VERSION "HNPBNNNYNNNNNNNNNNNNNNNNNNNNNNNNYNYYYYYYYY>4>%%%/4>'%**4YYY///"

NS_ :

BS_:

BU_: RDF2 Air Vehicle_CAN MPC2

BO_ 3221225472 VECTOR__INDEPENDENT_SIG_MSG: 0 Vector__XXX
 SG_ IHC_StaticLightDist : 0|16@1+ (1,0) [0|65535] "" Vector__XXX
 SG_ IHC_State : 0|8@1+ (1,0) [0|255] "" Vector__XXX
 SG_ RSF_SpeedLimit2FusionStrategy : 0|3@1+ (1,0) [0|7] "" Vector__XXX

BO_ 2566881322 NM_MPC_RDF2: 8 RDF2
 SG_ NM_Mode : 0|8@1+ (1,0) [0|255] "" Vector__XXX
 SG_ NM_Successor : 8|8@1+ (1,0) [0|255] "NoUnit" Vector__XXX
 SG_ NM_Ud_Launch : 16|6@1+ (1,0) [0|63] "" Vector__XXX
 SG_ NM_Sleep_Ack : 22|1@1+ (1,0) [0|1] "" Vector__XXX
 SG_ NM_Sleep_Ind : 23|1@1+ (1,0) [0|1] "" Vector__XXX
 SG_ NM_Ud_Srv M : 24|8@1+ (1,0) [0|255] "" Vector__XXX
 SG_ WakeupRsn_MPC m2 : 32|8@1+ (1,0) [0|255] "" Vector__XXX
 SG_ Awake_NwSt m15 : 32|1@1+ (1,0) [0|1] "" Vector__XXX
 SG_ Awake_Diag_Actv m15 : 33|1@1+ (1,0) [0|1] "" Vector__XXX
 SG_ Awake_IgnOn m15 : 34|1@1+ (1,0) [0|1] "" Vector__XXX
 SG_ Awake_XCP_Diag m15 : 36|1@1+ (1,0) [0|1] "" Vector__XXX
 SG_ Awake_VC_TrfData m15 : 37|1@1+ (1,0) [0|1] "" Vector__XXX
 SG_ WakeupCnt_cv m2 : 40|8@1+ (1,0) [0|254] "NoUnit" Vector__XXX
 SG_ Nw_Id : 56|8@1+ (1,0) [0|255] "" Vector__XXX

BO_ 2566881392 NM_MPC_A: 8 Air
 SG_ NM_Mode : 0|8@1+ (1,0) [0|255] "" Vector__XXX
 SG_ NM_Successor : 8|8@1+ (1,0) [0|255] "NoUnit" Vector__XXX
 SG_ NM_Ud_Launch : 16|6@1+ (1,0) [0|63] "" Vector__XXX
 SG_ NM_Sleep_Ack : 22|1@1+ (1,0) [0|1] "" Vector__XXX
 SG_ NM_Sleep_Ind : 23|1@1+ (1,0) [0|1] "" Vector__XXX
 SG_ NM_Ud_Srv M : 24|8@1+ (1,0) [0|255] "" Vector__XXX
 SG_ WakeupRsn_MPC m2 : 32|8@1+ (1,0) [0|255] "" Vector__XXX
 SG_ Awake_NwSt m15 : 32|1@1+ (1,0) [0|1] "" Vector__XXX
 SG_ Awake_Diag_Actv m15 : 33|1@1+ (1,0) [0|1] "" Vector__XXX
 SG_ Awake_IgnOn m15 : 34|1@1+ (1,0) [0|1] "" Vector__XXX
 SG_ Awake_XCP_Diag m15 : 36|1@1+ (1,0) [0|1] "" Vector__XXX
 SG_ Awake_VC_TrfData m15 : 37|1@1+ (1,0) [0|1] "" Vector__XXX
 SG_ WakeupCnt_cv m2 : 40|8@1+ (1,0) [0|254] "NoUnit" Vector__XXX
 SG_ Nw_Id : 56|8@1+ (1,0) [0|255] "" Vector__XXX

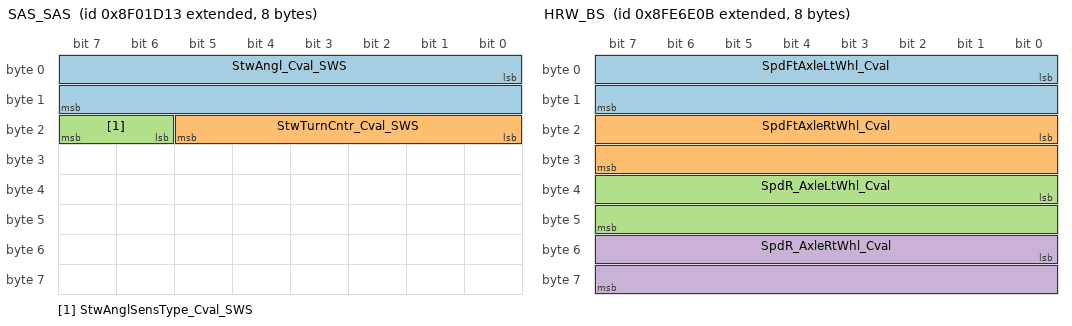
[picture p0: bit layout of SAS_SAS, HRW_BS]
BO_ 2297437459 SAS_SAS: 8 Vehicle_CAN
 SG_ StwAngl_Cval_SWS : 0|16@1+ (0.0009765625,-31.374) [-31.374|31.3750234375] "rad"  MPC2
 SG_ StwTurnCntr_Cval_SWS : 16|6@1+ (1,-32) [-32|29] "turn"  MPC2
 SG_ StwAnglSensType_Cval_SWS : 22|2@1+ (1,0) [0|3] ""  MPC2

BO_ 2298375691 HRW_BS: 8 Vehicle_CAN
 SG_ SpdFtAxleLtWhl_Cval : 0|16@1+ (0.00390625,0) [0|250.99609375] "km/h"  MPC2
 SG_ SpdFtAxleRtWhl_Cval : 16|16@1+ (0.00390625,0) [0|250.99609375] "km/h"  MPC2
 SG_ SpdR_AxleLtWhl_Cval : 32|16@1+ (0.00390625,0) [0|250.99609375] "km/h"  MPC2
 SG_ SpdR_AxleRtWhl_Cval : 48|16@1+ (0.00390625,0) [0|250.99609375] "km/h"  MPC2

BO_ 2365484055 TCO1_ICUC: 8 Vehicle_CAN
 SG_ DirInd_Stat_ICUC : 30|2@1+ (1,0) [0|3] ""  MPC2
 SG_ VehSpd_Cval_ICUC : 48|16@1+ (0.00390625,0) [0|250.99609375] "km/h"  MPC2

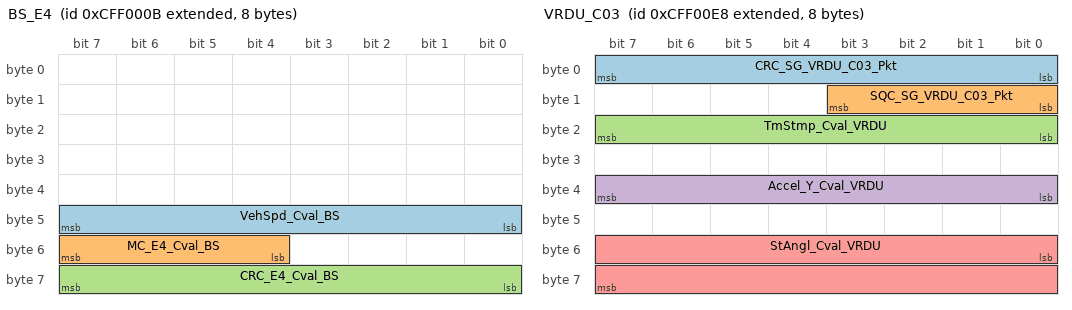
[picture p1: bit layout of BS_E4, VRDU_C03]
BO_ 2365521931 BS_E4: 8 Vehicle_CAN
 SG_ VehSpd_Cval_BS : 40|8@1+ (1,0) [0|250] "km/h"  MPC2
 SG_ MC_E4_Cval_BS : 52|4@1+ (1,0) [0|15] "NoUnit"  MPC2
 SG_ CRC_E4_Cval_BS : 56|8@1+ (1,0) [0|255] "NoUnit"  MPC2

BO_ 2365522152 VRDU_C03: 8 Vehicle_CAN
 SG_ CRC_SG_VRDU_C03_Pkt : 0|8@1+ (1,0) [0|255] "NoUnit"  MPC2
 SG_ SQC_SG_VRDU_C03_Pkt : 8|4@1+ (1,0) [0|15] "NoUnit"  MPC2
 SG_ TmStmp_Cval_VRDU : 16|8@1+ (1,0) [0|250] "NoUnit"  MPC2
 SG_ Accel_Y_Cval_VRDU : 32|8@1+ (0.1,-12.5) [-12.5|12.5] "m/s²"  MPC2
 SG_ StAngl_Cval_VRDU : 48|16@1+ (4E-005,-1.28508) [-1.28508|1.28512] "rad"  MPC2

BO_ 2431648512 EEC2_Prop_CPC3: 8 Vehicle_CAN
 SG_ AccelPdlKickDnSw_Rq : 2|2@1+ (1,0) [0|3] ""  MPC2
 SG_ AccelPdlPosn_Cval : 8|8@1+ (0.4,0) [0|100] "%"  MPC2

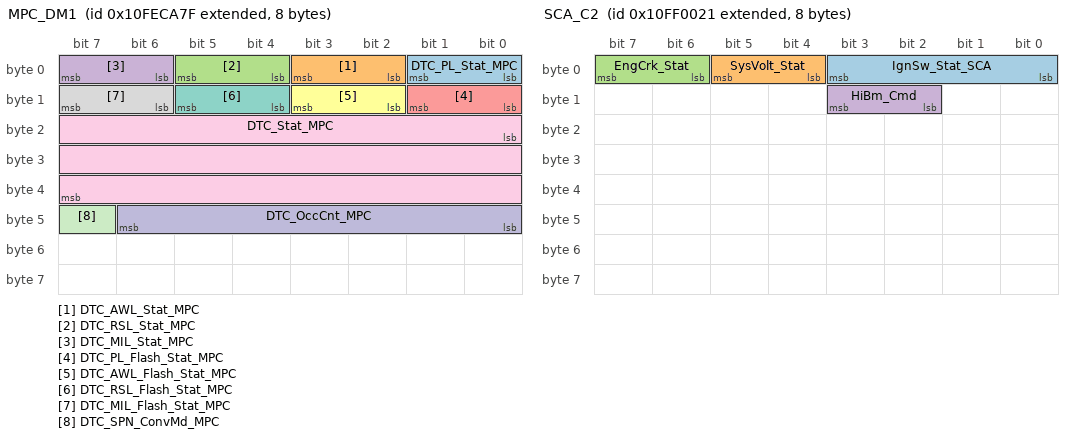
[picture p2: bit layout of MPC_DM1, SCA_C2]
BO_ 2432617087 MPC_DM1: 8 MPC2
 SG_ DTC_PL_Stat_MPC : 0|2@1+ (1,0) [0|3] "" Vector__XXX
 SG_ DTC_AWL_Stat_MPC : 2|2@1+ (1,0) [0|3] "" Vector__XXX
 SG_ DTC_RSL_Stat_MPC : 4|2@1+ (1,0) [0|3] "" Vector__XXX
 SG_ DTC_MIL_Stat_MPC : 6|2@1+ (1,0) [0|3] "" Vector__XXX
 SG_ DTC_PL_Flash_Stat_MPC : 8|2@1+ (1,0) [0|3] "" Vector__XXX
 SG_ DTC_AWL_Flash_Stat_MPC : 10|2@1+ (1,0) [0|3] "" Vector__XXX
 SG_ DTC_RSL_Flash_Stat_MPC : 12|2@1+ (1,0) [0|3] "" Vector__XXX
 SG_ DTC_MIL_Flash_Stat_MPC : 14|2@1+ (1,0) [0|3] "" Vector__XXX
 SG_ DTC_Stat_MPC : 16|24@1+ (1,0) [0|16777215] "NoUnit" Vector__XXX
 SG_ DTC_OccCnt_MPC : 40|7@1+ (1,0) [0|126] "count(s)" Vector__XXX
 SG_ DTC_SPN_ConvMd_MPC : 47|1@1+ (1,0) [0|1] "" Vector__XXX

BO_ 2432630817 SCA_C2: 8 Vehicle_CAN
 SG_ IgnSw_Stat_SCA : 0|4@1+ (1,0) [0|15] ""  MPC2
 SG_ SysVolt_Stat : 4|2@1+ (1,0) [0|3] ""  MPC2
 SG_ EngCrk_Stat : 6|2@1+ (1,0) [0|3] ""  MPC2
 SG_ HiBm_Cmd : 10|2@1+ (1,0) [0|3] ""  MPC2

BO_ 2432630911 MPC_C01: 8 MPC2
 SG_ Rsrv_CRC_SG_MPC_C01_Pkt : 0|8@1+ (1,0) [0|255] "NoUnit" Vector__XXX
 SG_ Rsrv_SQC_SG_MPC_C01_Pkt : 8|4@1+ (1,0) [0|15] "NoUnit" Vector__XXX
 SG_ LaneDptFuncActv_Stat_MPC : 12|4@1+ (1,0) [0|15] "" Vector__XXX
 SG_ LaneDptImntLt_Rq_MPC : 16|2@1+ (1,0) [0|3] "" Vector__XXX
 SG_ LaneDptImntRt_Rq_MPC : 18|2@1+ (1,0) [0|3] "" Vector__XXX
 SG_ LaneDptWarnLt_Rq_MPC : 20|2@1+ (1,0) [0|3] "" Vector__XXX
 SG_ LaneDptWarnRt_Rq_MPC : 22|2@1+ (1,0) [0|3] "" Vector__XXX
 SG_ LaneDptD_Actv_Stat_MPC : 24|2@1+ (1,0) [0|3] "" Vector__XXX
 SG_ SwLED_LDW_Rq_MPC : 26|2@1+ (1,0) [0|3] "" Vector__XXX
 SG_ TypeLaneMarkLt_Stat_MPC : 28|2@1+ (1,0) [0|3] "" Vector__XXX
 SG_ TypeLaneMarkRt_Stat_MPC : 30|2@1+ (1,0) [0|3] "" Vector__XXX
 SG_ ActlLgtDist_Cval : 32|8@1+ (2.5,0) [0|625] "m" Vector__XXX
 SG_ HL_ChgOvrLvl_Cval : 40|4@1+ (1,0) [0|15] "count(s)" Vector__XXX
 SG_ IHC_Func_Stat_MPC : 44|4@1+ (1,0) [0|15] "" Vector__XXX
 SG_ HiBm_Rq_MPC : 48|2@1+ (1,0) [0|3] "" Vector__XXX
 SG_ DayNightMd_Stat_MPC : 50|2@1+ (1,0) [0|3] "" Vector__XXX
 SG_ LimSight_Stat_MPC : 52|2@1+ (1,0) [0|3] "" Vector__XXX
 SG_ LaneMarkRecLt_Stat : 54|2@1+ (1,0) [0|3] "" Vector__XXX
 SG_ LaneMarkRecRt_Stat : 56|2@1+ (1,0) [0|3] "" Vector__XXX
 SG_ LaneMarkColLt_Cval_MPC : 58|3@1+ (1,0) [0|7] "" Vector__XXX
 SG_ LaneMarkColRt_Cval_MPC : 61|3@1+ (1,0) [0|7] "" Vector__XXX

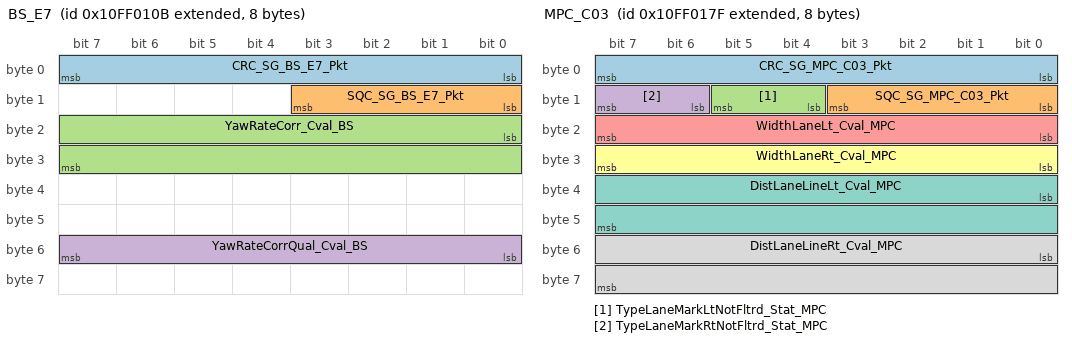
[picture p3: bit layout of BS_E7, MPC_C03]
BO_ 2432631051 BS_E7: 8 Vehicle_CAN
 SG_ CRC_SG_BS_E7_Pkt : 0|8@1+ (1,0) [0|255] "NoUnit"  MPC2
 SG_ SQC_SG_BS_E7_Pkt : 8|4@1+ (1,0) [0|15] "NoUnit"  MPC2
 SG_ YawRateCorr_Cval_BS : 16|16@1+ (0.0001220703125,-3.92) [-3.92|3.9199658203125] "rad/s"  MPC2
 SG_ YawRateCorrQual_Cval_BS : 48|8@1+ (0.4,0) [0|100] "%"  MPC2

BO_ 2432631167 MPC_C03: 8 MPC2
 SG_ CRC_SG_MPC_C03_Pkt : 0|8@1+ (1,0) [0|255] "NoUnit" Vector__XXX
 SG_ SQC_SG_MPC_C03_Pkt : 8|4@1+ (1,0) [0|15] "NoUnit" Vector__XXX
 SG_ TypeLaneMarkLtNotFltrd_Stat_MPC : 12|2@1+ (1,0) [0|3] "" Vector__XXX
 SG_ TypeLaneMarkRtNotFltrd_Stat_MPC : 14|2@1+ (1,0) [0|3] "" Vector__XXX
 SG_ WidthLaneLt_Cval_MPC : 16|8@1+ (10,0) [0|2500] "mm" Vector__XXX
 SG_ WidthLaneRt_Cval_MPC : 24|8@1+ (10,0) [0|2500] "mm" Vector__XXX
 SG_ DistLaneLineLt_Cval_MPC : 32|16@1+ (0.0078125,-250.99609375) [-250.99609375|250.99609375] "m" Vector__XXX
 SG_ DistLaneLineRt_Cval_MPC : 48|16@1+ (0.0078125,-250.99609375) [-250.99609375|250.99609375] "m" Vector__XXX

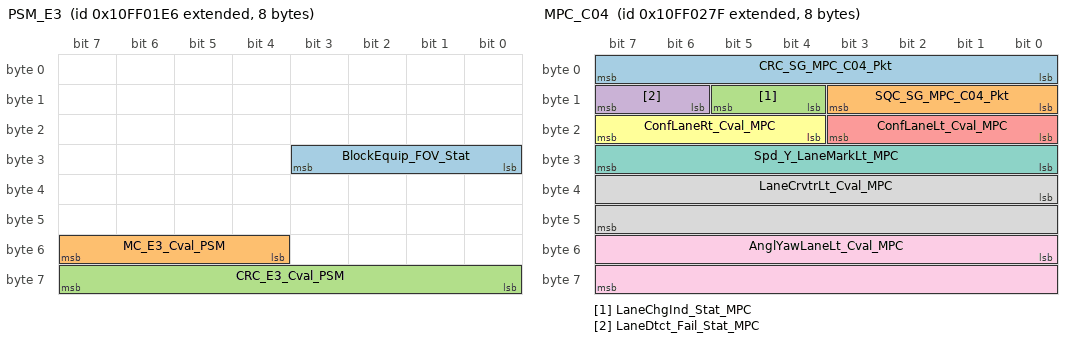
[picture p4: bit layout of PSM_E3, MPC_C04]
BO_ 2432631270 PSM_E3: 8 Vehicle_CAN
 SG_ BlockEquip_FOV_Stat : 24|4@1+ (1,0) [0|15] ""  MPC2
 SG_ MC_E3_Cval_PSM : 52|4@1+ (1,0) [0|15] "NoUnit"  MPC2
 SG_ CRC_E3_Cval_PSM : 56|8@1+ (1,0) [0|255] "NoUnit"  MPC2

BO_ 2432631423 MPC_C04: 8 MPC2
 SG_ CRC_SG_MPC_C04_Pkt : 0|8@1+ (1,0) [0|255] "NoUnit" Vector__XXX
 SG_ SQC_SG_MPC_C04_Pkt : 8|4@1+ (1,0) [0|15] "NoUnit" Vector__XXX
 SG_ LaneChgInd_Stat_MPC : 12|2@1+ (1,0) [0|3] "" Vector__XXX
 SG_ LaneDtct_Fail_Stat_MPC : 14|2@1+ (1,0) [0|3] "" Vector__XXX
 SG_ ConfLaneLt_Cval_MPC : 16|4@1+ (10,0) [0|100] "%" Vector__XXX
 SG_ ConfLaneRt_Cval_MPC : 20|4@1+ (10,0) [0|100] "%" Vector__XXX
 SG_ Spd_Y_LaneMarkLt_MPC : 24|8@1+ (0.1,-12.5) [-12.5|12.5] "m/s" Vector__XXX
 SG_ LaneCrvtrLt_Cval_MPC : 32|16@1+ (0.0078125,-250) [-250|251.9921875] "1/km" Vector__XXX
 SG_ AnglYawLaneLt_Cval_MPC : 48|16@1+ (0.00390625,-125) [-125|125] "°" Vector__XXX

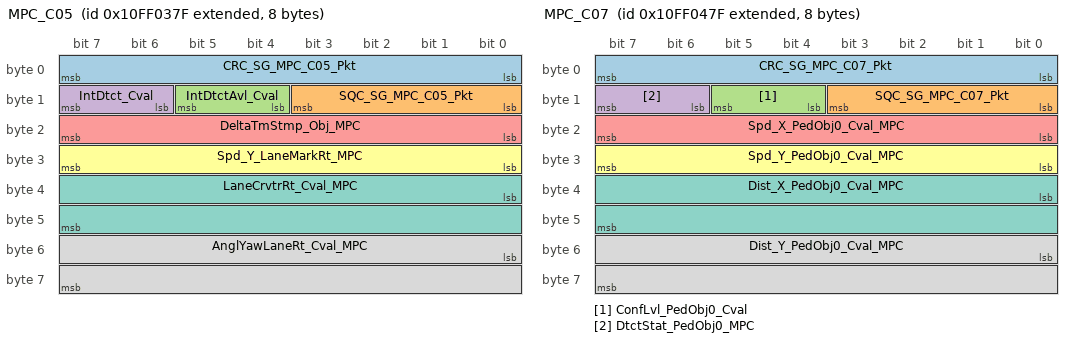
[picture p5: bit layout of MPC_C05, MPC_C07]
BO_ 2432631679 MPC_C05: 8 MPC2
 SG_ CRC_SG_MPC_C05_Pkt : 0|8@1+ (1,0) [0|255] "NoUnit" Vector__XXX
 SG_ SQC_SG_MPC_C05_Pkt : 8|4@1+ (1,0) [0|15] "NoUnit" Vector__XXX
 SG_ IntDtctAvl_Cval : 12|2@1+ (1,0) [0|3] "" Vector__XXX
 SG_ IntDtct_Cval : 14|2@1+ (1,0) [0|3] "" Vector__XXX
 SG_ DeltaTmStmp_Obj_MPC : 16|8@1+ (1,0) [0|250] "NoUnit" Vector__XXX
 SG_ Spd_Y_LaneMarkRt_MPC : 24|8@1+ (0.1,-12.5) [-12.5|12.5] "m/s" Vector__XXX
 SG_ LaneCrvtrRt_Cval_MPC : 32|16@1+ (0.0078125,-250) [-250|251.9921875] "1/km" Vector__XXX
 SG_ AnglYawLaneRt_Cval_MPC : 48|16@1+ (0.00390625,-125) [-125|125] "°" Vector__XXX

BO_ 2432631935 MPC_C07: 8 MPC2
 SG_ CRC_SG_MPC_C07_Pkt : 0|8@1+ (1,0) [0|255] "NoUnit" Vector__XXX
 SG_ SQC_SG_MPC_C07_Pkt : 8|4@1+ (1,0) [0|15] "NoUnit" Vector__XXX
 SG_ ConfLvl_PedObj0_Cval : 12|2@1+ (1,0) [0|3] "" Vector__XXX
 SG_ DtctStat_PedObj0_MPC : 14|2@1+ (1,0) [0|3] "" Vector__XXX
 SG_ Spd_X_PedObj0_Cval_MPC : 16|8@1+ (1,-200) [-200|50] "km/h" Vector__XXX
 SG_ Spd_Y_PedObj0_Cval_MPC : 24|8@1+ (0.1,-12.5) [-12.5|12.5] "m/s" Vector__XXX
 SG_ Dist_X_PedObj0_Cval_MPC : 32|16@1+ (0.0078125,-250.99609375) [-250.99609375|250.99609375] "m" Vector__XXX
 SG_ Dist_Y_PedObj0_Cval_MPC : 48|16@1+ (0.0078125,-250.99609375) [-250.99609375|250.99609375] "m" Vector__XXX

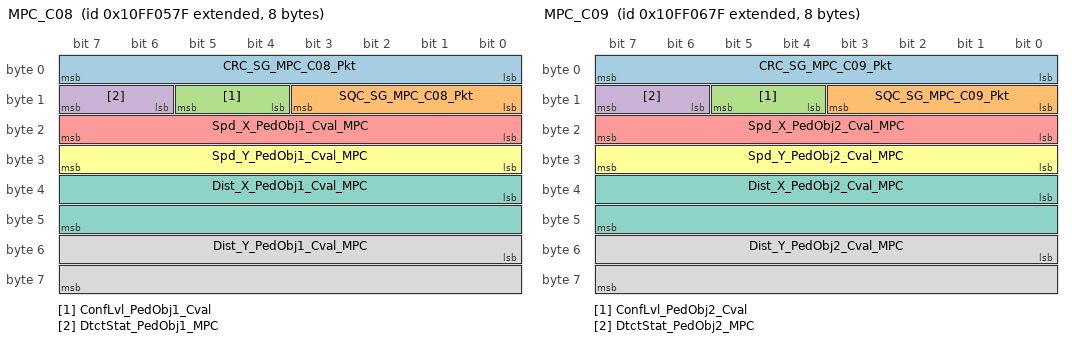
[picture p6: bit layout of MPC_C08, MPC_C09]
BO_ 2432632191 MPC_C08: 8 MPC2
 SG_ CRC_SG_MPC_C08_Pkt : 0|8@1+ (1,0) [0|255] "NoUnit" Vector__XXX
 SG_ SQC_SG_MPC_C08_Pkt : 8|4@1+ (1,0) [0|15] "NoUnit" Vector__XXX
 SG_ ConfLvl_PedObj1_Cval : 12|2@1+ (1,0) [0|3] "" Vector__XXX
 SG_ DtctStat_PedObj1_MPC : 14|2@1+ (1,0) [0|3] "" Vector__XXX
 SG_ Spd_X_PedObj1_Cval_MPC : 16|8@1+ (1,-200) [-200|50] "km/h" Vector__XXX
 SG_ Spd_Y_PedObj1_Cval_MPC : 24|8@1+ (0.1,-12.5) [-12.5|12.5] "m/s" Vector__XXX
 SG_ Dist_X_PedObj1_Cval_MPC : 32|16@1+ (0.0078125,-250.99609375) [-250.99609375|250.99609375] "m" Vector__XXX
 SG_ Dist_Y_PedObj1_Cval_MPC : 48|16@1+ (0.0078125,-250.99609375) [-250.99609375|250.99609375] "m" Vector__XXX

BO_ 2432632447 MPC_C09: 8 MPC2
 SG_ CRC_SG_MPC_C09_Pkt : 0|8@1+ (1,0) [0|255] "NoUnit" Vector__XXX
 SG_ SQC_SG_MPC_C09_Pkt : 8|4@1+ (1,0) [0|15] "NoUnit" Vector__XXX
 SG_ ConfLvl_PedObj2_Cval : 12|2@1+ (1,0) [0|3] "" Vector__XXX
 SG_ DtctStat_PedObj2_MPC : 14|2@1+ (1,0) [0|3] "" Vector__XXX
 SG_ Spd_X_PedObj2_Cval_MPC : 16|8@1+ (1,-200) [-200|50] "km/h" Vector__XXX
 SG_ Spd_Y_PedObj2_Cval_MPC : 24|8@1+ (0.1,-12.5) [-12.5|12.5] "m/s" Vector__XXX
 SG_ Dist_X_PedObj2_Cval_MPC : 32|16@1+ (0.0078125,-250.99609375) [-250.99609375|250.99609375] "m" Vector__XXX
 SG_ Dist_Y_PedObj2_Cval_MPC : 48|16@1+ (0.0078125,-250.99609375) [-250.99609375|250.99609375] "m" Vector__XXX

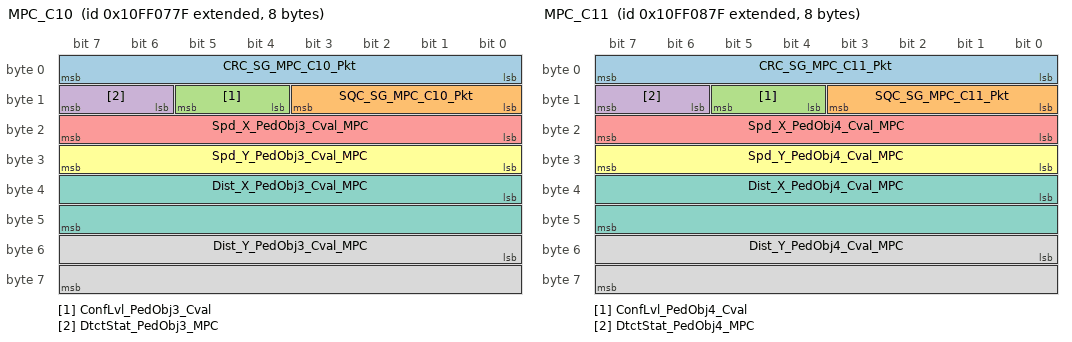
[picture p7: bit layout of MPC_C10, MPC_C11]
BO_ 2432632703 MPC_C10: 8 MPC2
 SG_ CRC_SG_MPC_C10_Pkt : 0|8@1+ (1,0) [0|255] "NoUnit" Vector__XXX
 SG_ SQC_SG_MPC_C10_Pkt : 8|4@1+ (1,0) [0|15] "NoUnit" Vector__XXX
 SG_ ConfLvl_PedObj3_Cval : 12|2@1+ (1,0) [0|3] "" Vector__XXX
 SG_ DtctStat_PedObj3_MPC : 14|2@1+ (1,0) [0|3] "" Vector__XXX
 SG_ Spd_X_PedObj3_Cval_MPC : 16|8@1+ (1,-200) [-200|50] "km/h" Vector__XXX
 SG_ Spd_Y_PedObj3_Cval_MPC : 24|8@1+ (0.1,-12.5) [-12.5|12.5] "m/s" Vector__XXX
 SG_ Dist_X_PedObj3_Cval_MPC : 32|16@1+ (0.0078125,-250.99609375) [-250.99609375|250.99609375] "m" Vector__XXX
 SG_ Dist_Y_PedObj3_Cval_MPC : 48|16@1+ (0.0078125,-250.99609375) [-250.99609375|250.99609375] "m" Vector__XXX

BO_ 2432632959 MPC_C11: 8 MPC2
 SG_ CRC_SG_MPC_C11_Pkt : 0|8@1+ (1,0) [0|255] "NoUnit" Vector__XXX
 SG_ SQC_SG_MPC_C11_Pkt : 8|4@1+ (1,0) [0|15] "NoUnit" Vector__XXX
 SG_ ConfLvl_PedObj4_Cval : 12|2@1+ (1,0) [0|3] "" Vector__XXX
 SG_ DtctStat_PedObj4_MPC : 14|2@1+ (1,0) [0|3] "" Vector__XXX
 SG_ Spd_X_PedObj4_Cval_MPC : 16|8@1+ (1,-200) [-200|50] "km/h" Vector__XXX
 SG_ Spd_Y_PedObj4_Cval_MPC : 24|8@1+ (0.1,-12.5) [-12.5|12.5] "m/s" Vector__XXX
 SG_ Dist_X_PedObj4_Cval_MPC : 32|16@1+ (0.0078125,-250.99609375) [-250.99609375|250.99609375] "m" Vector__XXX
 SG_ Dist_Y_PedObj4_Cval_MPC : 48|16@1+ (0.0078125,-250.99609375) [-250.99609375|250.99609375] "m" Vector__XXX

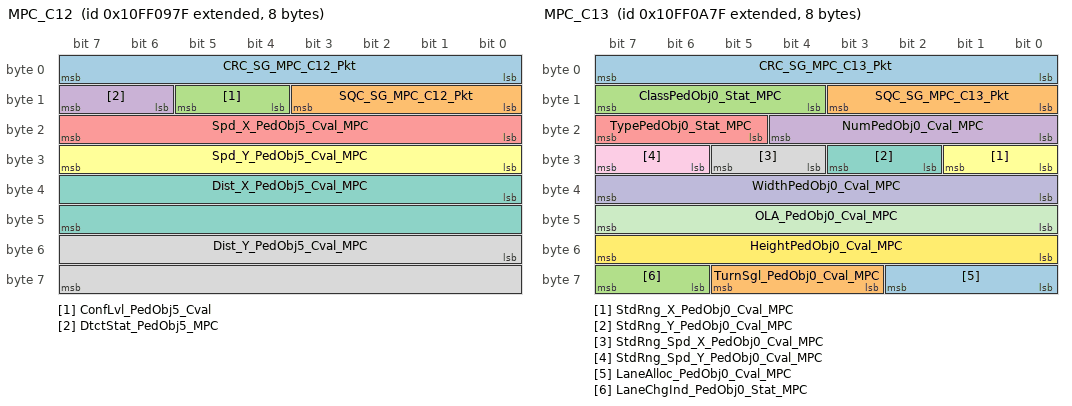
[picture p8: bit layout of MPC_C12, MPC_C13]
BO_ 2432633215 MPC_C12: 8 MPC2
 SG_ CRC_SG_MPC_C12_Pkt : 0|8@1+ (1,0) [0|255] "NoUnit" Vector__XXX
 SG_ SQC_SG_MPC_C12_Pkt : 8|4@1+ (1,0) [0|15] "NoUnit" Vector__XXX
 SG_ ConfLvl_PedObj5_Cval : 12|2@1+ (1,0) [0|3] "" Vector__XXX
 SG_ DtctStat_PedObj5_MPC : 14|2@1+ (1,0) [0|3] "" Vector__XXX
 SG_ Spd_X_PedObj5_Cval_MPC : 16|8@1+ (1,-200) [-200|50] "km/h" Vector__XXX
 SG_ Spd_Y_PedObj5_Cval_MPC : 24|8@1+ (0.1,-12.5) [-12.5|12.5] "m/s" Vector__XXX
 SG_ Dist_X_PedObj5_Cval_MPC : 32|16@1+ (0.0078125,-250.99609375) [-250.99609375|250.99609375] "m" Vector__XXX
 SG_ Dist_Y_PedObj5_Cval_MPC : 48|16@1+ (0.0078125,-250.99609375) [-250.99609375|250.99609375] "m" Vector__XXX

BO_ 2432633471 MPC_C13: 8 MPC2
 SG_ CRC_SG_MPC_C13_Pkt : 0|8@1+ (1,0) [0|255] "NoUnit" Vector__XXX
 SG_ SQC_SG_MPC_C13_Pkt : 8|4@1+ (1,0) [0|15] "NoUnit" Vector__XXX
 SG_ ClassPedObj0_Stat_MPC : 12|4@1+ (1,0) [0|15] "" Vector__XXX
 SG_ NumPedObj0_Cval_MPC : 16|5@1+ (1,0) [0|30] "NoUnit" Vector__XXX
 SG_ TypePedObj0_Stat_MPC : 21|3@1+ (1,0) [0|7] "" Vector__XXX
 SG_ StdRng_X_PedObj0_Cval_MPC : 24|2@1+ (1,0) [0|3] "" Vector__XXX
 SG_ StdRng_Y_PedObj0_Cval_MPC : 26|2@1+ (1,0) [0|3] "" Vector__XXX
 SG_ StdRng_Spd_X_PedObj0_Cval_MPC : 28|2@1+ (1,0) [0|3] "" Vector__XXX
 SG_ StdRng_Spd_Y_PedObj0_Cval_MPC : 30|2@1+ (1,0) [0|3] "" Vector__XXX
 SG_ WidthPedObj0_Cval_MPC : 32|8@1+ (0.05,0) [0|12.5] "m" Vector__XXX
 SG_ OLA_PedObj0_Cval_MPC : 40|8@1+ (0.004,-0.5) [-0.5|0.5] "rad" Vector__XXX
 SG_ HeightPedObj0_Cval_MPC : 48|8@1+ (0.05,0) [0|12.5] "m" Vector__XXX
 SG_ LaneAlloc_PedObj0_Cval_MPC : 56|3@1+ (1,0) [0|7] "" Vector__XXX
 SG_ TurnSgl_PedObj0_Cval_MPC : 59|3@1+ (1,0) [0|7] "" Vector__XXX
 SG_ LaneChgInd_PedObj0_Stat_MPC : 62|2@1+ (1,0) [0|3] "" Vector__XXX

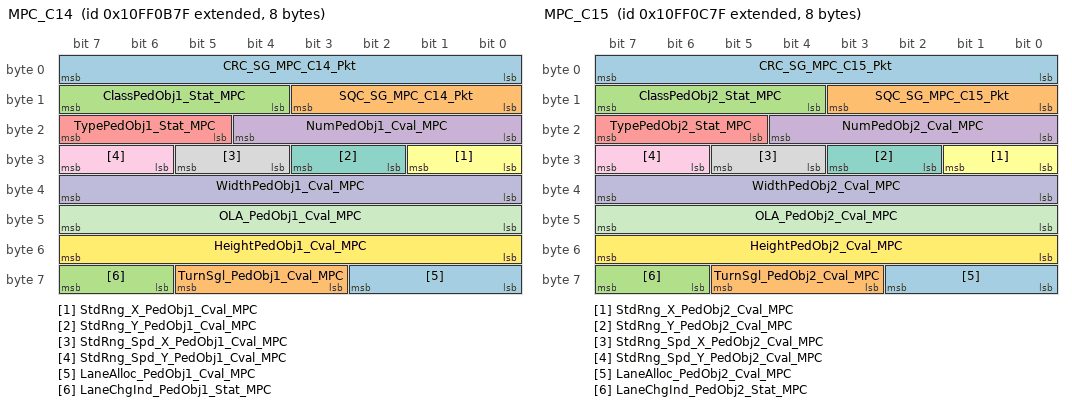
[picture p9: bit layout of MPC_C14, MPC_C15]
BO_ 2432633727 MPC_C14: 8 MPC2
 SG_ CRC_SG_MPC_C14_Pkt : 0|8@1+ (1,0) [0|255] "NoUnit" Vector__XXX
 SG_ SQC_SG_MPC_C14_Pkt : 8|4@1+ (1,0) [0|15] "NoUnit" Vector__XXX
 SG_ ClassPedObj1_Stat_MPC : 12|4@1+ (1,0) [0|15] "" Vector__XXX
 SG_ NumPedObj1_Cval_MPC : 16|5@1+ (1,0) [0|30] "NoUnit" Vector__XXX
 SG_ TypePedObj1_Stat_MPC : 21|3@1+ (1,0) [0|7] "" Vector__XXX
 SG_ StdRng_X_PedObj1_Cval_MPC : 24|2@1+ (1,0) [0|3] "" Vector__XXX
 SG_ StdRng_Y_PedObj1_Cval_MPC : 26|2@1+ (1,0) [0|3] "" Vector__XXX
 SG_ StdRng_Spd_X_PedObj1_Cval_MPC : 28|2@1+ (1,0) [0|3] "" Vector__XXX
 SG_ StdRng_Spd_Y_PedObj1_Cval_MPC : 30|2@1+ (1,0) [0|3] "" Vector__XXX
 SG_ WidthPedObj1_Cval_MPC : 32|8@1+ (0.05,0) [0|12.5] "m" Vector__XXX
 SG_ OLA_PedObj1_Cval_MPC : 40|8@1+ (0.004,-0.5) [-0.5|0.5] "rad" Vector__XXX
 SG_ HeightPedObj1_Cval_MPC : 48|8@1+ (0.05,0) [0|12.5] "m" Vector__XXX
 SG_ LaneAlloc_PedObj1_Cval_MPC : 56|3@1+ (1,0) [0|7] "" Vector__XXX
 SG_ TurnSgl_PedObj1_Cval_MPC : 59|3@1+ (1,0) [0|7] "" Vector__XXX
 SG_ LaneChgInd_PedObj1_Stat_MPC : 62|2@1+ (1,0) [0|3] "" Vector__XXX

BO_ 2432633983 MPC_C15: 8 MPC2
 SG_ CRC_SG_MPC_C15_Pkt : 0|8@1+ (1,0) [0|255] "NoUnit" Vector__XXX
 SG_ SQC_SG_MPC_C15_Pkt : 8|4@1+ (1,0) [0|15] "NoUnit" Vector__XXX
 SG_ ClassPedObj2_Stat_MPC : 12|4@1+ (1,0) [0|15] "" Vector__XXX
 SG_ NumPedObj2_Cval_MPC : 16|5@1+ (1,0) [0|30] "NoUnit" Vector__XXX
 SG_ TypePedObj2_Stat_MPC : 21|3@1+ (1,0) [0|7] "" Vector__XXX
 SG_ StdRng_X_PedObj2_Cval_MPC : 24|2@1+ (1,0) [0|3] "" Vector__XXX
 SG_ StdRng_Y_PedObj2_Cval_MPC : 26|2@1+ (1,0) [0|3] "" Vector__XXX
 SG_ StdRng_Spd_X_PedObj2_Cval_MPC : 28|2@1+ (1,0) [0|3] "" Vector__XXX
 SG_ StdRng_Spd_Y_PedObj2_Cval_MPC : 30|2@1+ (1,0) [0|3] "" Vector__XXX
 SG_ WidthPedObj2_Cval_MPC : 32|8@1+ (0.05,0) [0|12.5] "m" Vector__XXX
 SG_ OLA_PedObj2_Cval_MPC : 40|8@1+ (0.004,-0.5) [-0.5|0.5] "rad" Vector__XXX
 SG_ HeightPedObj2_Cval_MPC : 48|8@1+ (0.05,0) [0|12.5] "m" Vector__XXX
 SG_ LaneAlloc_PedObj2_Cval_MPC : 56|3@1+ (1,0) [0|7] "" Vector__XXX
 SG_ TurnSgl_PedObj2_Cval_MPC : 59|3@1+ (1,0) [0|7] "" Vector__XXX
 SG_ LaneChgInd_PedObj2_Stat_MPC : 62|2@1+ (1,0) [0|3] "" Vector__XXX

CM_ "CHECKSUM={EF10D18F581602AD82588EC0D8D8A7D16F9B9236}XDIS NWC Export: ASSISTANCE_CAN_667kB [44,1], UUID BA5943FFBF5F11E7B70578E3B518F750, RELEASED 2017-11-11 CET-00:17:23XDIS-Database: CVD-Database";
CM_ BO_ 3221225472 "This is a message for not used signals, created by Vector CANdb++ DBC OLE DB Provider.";
CM_ SG_ 2297437459 StwAngl_Cval_SWS "Steering Wheel Angle Steering Wheel Sensor Current value";
CM_ SG_ 2297437459 StwTurnCntr_Cval_SWS "Steering Wheel Turn Counter Steering Wheel Sensor Current value";
CM_ SG_ 2297437459 StwAnglSensType_Cval_SWS "Steering Wheel Angle Sensor Type Steering Wheel Sensor Current value";
CM_ SG_ 2298375691 SpdFtAxleLtWhl_Cval "Front Axle, Left Wheel Speed";
CM_ SG_ 2298375691 SpdFtAxleRtWhl_Cval "Front Axle, Right Wheel Speed";
CM_ SG_ 2298375691 SpdR_AxleLtWhl_Cval "Rear Axle, Left Wheel Speed";
CM_ SG_ 2298375691 SpdR_AxleRtWhl_Cval "Rear Axle, Right Wheel Speed";
CM_ SG_ 2365484055 DirInd_Stat_ICUC "Direction Indicator Current state Speedometer";
CM_ SG_ 2365484055 VehSpd_Cval_ICUC "Vehicle Speed Current value ICUC";
CM_ SG_ 2365521931 VehSpd_Cval_BS "Vehicle Speed Current value";
CM_ SG_ 2365521931 MC_E4_Cval_BS "Message Counter E4 Current Value BS";
CM_ SG_ 2365521931 CRC_E4_Cval_BS "Checksum E4 Current value BS";
CM_ SG_ 2365522152 CRC_SG_VRDU_C03_Pkt "Message checksum";
CM_ SG_ 2365522152 SQC_SG_VRDU_C03_Pkt "Message Counter C03 Current Value VRDU";
CM_ SG_ 2365522152 TmStmp_Cval_VRDU "VRDU Time stamp - current value";
CM_ SG_ 2365522152 Accel_Y_Cval_VRDU "Lateral Accelerate (Y) Current value VRDU";
CM_ SG_ 2365522152 StAngl_Cval_VRDU "Steering Angle Current value VRDU";
CM_ SG_ 2431648512 AccelPdlKickDnSw_Rq "Accelerator Pedal Kickdown Switch";
CM_ SG_ 2431648512 AccelPdlPosn_Cval "Accelerator Pedal Position Current value";
CM_ SG_ 2432617087 DTC_PL_Stat_MPC "Protect Lamp Status";
CM_ SG_ 2432617087 DTC_AWL_Stat_MPC "Amber Warning Lamp Status";
CM_ SG_ 2432617087 DTC_RSL_Stat_MPC "Red Stop Lamp Status";
CM_ SG_ 2432617087 DTC_MIL_Stat_MPC "Malfunction Indicator Lamp Status";
CM_ SG_ 2432617087 DTC_PL_Flash_Stat_MPC "Protect Lamp Flash Status";
CM_ SG_ 2432617087 DTC_AWL_Flash_Stat_MPC "Amber Warning Lamp Flash Status";
CM_ SG_ 2432617087 DTC_RSL_Flash_Stat_MPC "Red Stop Lamp Flash Status";
CM_ SG_ 2432617087 DTC_MIL_Flash_Stat_MPC "Malfunction Indicator Lamp Flash Status";
CM_ SG_ 2432617087 DTC_Stat_MPC "DTC MPC Current state";
CM_ SG_ 2432617087 DTC_OccCnt_MPC "DTC Occurrence Count";
CM_ SG_ 2432617087 DTC_SPN_ConvMd_MPC "SPN Conversion Method";
CM_ SG_ 2432630817 IgnSw_Stat_SCA "Ignition Switch Current state from SCA";
CM_ SG_ 2432630817 SysVolt_Stat "System Voltage Current state";
CM_ SG_ 2432630817 EngCrk_Stat "Engine Cranking Current State";
CM_ SG_ 2432630817 HiBm_Cmd "High beam Command";
CM_ SG_ 2432630911 Rsrv_CRC_SG_MPC_C01_Pkt "Checksum C01 Current value MPC";
CM_ SG_ 2432630911 Rsrv_SQC_SG_MPC_C01_Pkt "Sequence Counter C01 Current Value MPC";
CM_ SG_ 2432630911 LaneDptFuncActv_Stat_MPC "Lane Departure Function Activation Current state";
CM_ SG_ 2432630911 LaneDptImntLt_Rq_MPC "Lane departure imminent left side (optical)";
CM_ SG_ 2432630911 LaneDptImntRt_Rq_MPC "Lane departure imminent right side (optical)";
CM_ SG_ 2432630911 LaneDptWarnLt_Rq_MPC "Lane departure warning left side (optical, acoustical)";
CM_ SG_ 2432630911 LaneDptWarnRt_Rq_MPC "Lane departure warning right side (optical, acoustical)";
CM_ SG_ 2432630911 LaneDptD_Actv_Stat_MPC "Lane Departure Driver Activation Current state";
CM_ SG_ 2432630911 SwLED_LDW_Rq_MPC "Request switch LED (LDW)";
CM_ SG_ 2432630911 TypeLaneMarkLt_Stat_MPC "Type of left lane mark";
CM_ SG_ 2432630911 TypeLaneMarkRt_Stat_MPC "Type of right lane mark";
CM_ SG_ 2432630911 ActlLgtDist_Cval "Actual Light Distance Current value";
CM_ SG_ 2432630911 HL_ChgOvrLvl_Cval "Head Lamp Change Over Level Current value";
CM_ SG_ 2432630911 IHC_Func_Stat_MPC "IHC Function Current state MPC";
CM_ SG_ 2432630911 HiBm_Rq_MPC "High beam Requested state MPC";
CM_ SG_ 2432630911 DayNightMd_Stat_MPC "Day-/Night Mode Current State MPC";
CM_ SG_ 2432630911 LimSight_Stat_MPC "Limited Sight Current state (MPC)";
CM_ SG_ 2432630911 LaneMarkRecLt_Stat "Lane Mark Recognition Left Current state";
CM_ SG_ 2432630911 LaneMarkRecRt_Stat "Lane Mark Recognition Right(s) Current state";
CM_ SG_ 2432630911 LaneMarkColLt_Cval_MPC "Lane Mark Color Left Current value MPC";
CM_ SG_ 2432630911 LaneMarkColRt_Cval_MPC "Lane Mark Color Right(s) Current value MPC";
CM_ SG_ 2432631051 CRC_SG_BS_E7_Pkt "Checksum E7 Current value BS";
CM_ SG_ 2432631051 SQC_SG_BS_E7_Pkt "Sequence Counter E7 Current Value BS";
CM_ SG_ 2432631051 YawRateCorr_Cval_BS "Yaw Rate Corrected  Current value BS";
CM_ SG_ 2432631051 YawRateCorrQual_Cval_BS "Yaw Rate Correction Quality Current value BS";
CM_ SG_ 2432631167 CRC_SG_MPC_C03_Pkt "Checksum C03 Current value MPC (Autosar) {D6,90,4A,04,B9,73,2D,E2,9C,56,10,C5,7F,39,EE,A8}";
CM_ SG_ 2432631167 SQC_SG_MPC_C03_Pkt "Sequence Counter C03 Current Value MPC (Autosar)";
CM_ SG_ 2432631167 TypeLaneMarkLtNotFltrd_Stat_MPC "Type of left lane mark not filtered";
CM_ SG_ 2432631167 TypeLaneMarkRtNotFltrd_Stat_MPC "Type of right lane mark not filtered";
CM_ SG_ 2432631167 WidthLaneLt_Cval_MPC "width of left lane mark";
CM_ SG_ 2432631167 WidthLaneRt_Cval_MPC "width of right lane mark";
CM_ SG_ 2432631167 DistLaneLineLt_Cval_MPC "Distance to left lane mark";
CM_ SG_ 2432631167 DistLaneLineRt_Cval_MPC "Distance to right lane mark";
CM_ SG_ 2432631270 BlockEquip_FOV_Stat "Blocking Equipment FOV Current state";
CM_ SG_ 2432631270 MC_E3_Cval_PSM "Message Counter E3 Current Value PSM";
CM_ SG_ 2432631270 CRC_E3_Cval_PSM "Checksum E3 Current value PSM";
CM_ SG_ 2432631423 CRC_SG_MPC_C04_Pkt "Checksum C04 Current value MPC (Autosar) {3D,93,E9,44,9A,F0,4B,A1,F7,52,A8,03,59,AF,0A,60}";
CM_ SG_ 2432631423 SQC_SG_MPC_C04_Pkt "Sequence Counter C04 Current Value MPC (Autosar)";
CM_ SG_ 2432631423 LaneChgInd_Stat_MPC "Lane Change Indicator Current state MPC";
CM_ SG_ 2432631423 LaneDtct_Fail_Stat_MPC "Lane Detection Failure Current state (MPC)";
CM_ SG_ 2432631423 ConfLaneLt_Cval_MPC "Confidence Lane Left Current value MPC";
CM_ SG_ 2432631423 ConfLaneRt_Cval_MPC "Confidence Lane Right Current value MPC";
CM_ SG_ 2432631423 Spd_Y_LaneMarkLt_MPC "Lateral Speed (vy) to lane marking Left (MPC)";
CM_ SG_ 2432631423 LaneCrvtrLt_Cval_MPC "lane curvature c0 left MPC";
CM_ SG_ 2432631423 AnglYawLaneLt_Cval_MPC "angle of yaw to the lane left MPC";
CM_ SG_ 2432631679 CRC_SG_MPC_C05_Pkt "Checksum C05 Current value MPC {5D,C8,38,A3,13,7E,E9,59,C4,34,9F,0F,7A,E5,55,C0}";
CM_ SG_ 2432631679 SQC_SG_MPC_C05_Pkt "Sequence Counter C05 Current Value MPC";
CM_ SG_ 2432631679 IntDtctAvl_Cval "Intruder Detection Available Current value";
CM_ SG_ 2432631679 IntDtct_Cval "Intruder Detected Current value";
CM_ SG_ 2432631679 DeltaTmStmp_Obj_MPC "Time Stamp of objects (MPC)";
CM_ SG_ 2432631679 Spd_Y_LaneMarkRt_MPC "Lateral Speed (vy) to lane marking right (MPC)";
CM_ SG_ 2432631679 LaneCrvtrRt_Cval_MPC "lane curvature c0 right MPC";
CM_ SG_ 2432631679 AnglYawLaneRt_Cval_MPC "angle of yaw to the lane right MPC";
CM_ SG_ 2432631935 CRC_SG_MPC_C07_Pkt "Checksum C07 Current value MPC {D3,53,CE,4E,C9,49,C4,44,BF,3F,BA,3A,B5,35,B0,30}";
CM_ SG_ 2432631935 SQC_SG_MPC_C07_Pkt "Message Counter C07 Current Value MPC";
CM_ SG_ 2432631935 ConfLvl_PedObj0_Cval "Confidence Level of pedestrian object 0 Current value (MPC)";
CM_ SG_ 2432631935 DtctStat_PedObj0_MPC "Detection State of pedestrian object 0 Current Value (MPC)";
CM_ SG_ 2432631935 Spd_X_PedObj0_Cval_MPC "Relative speed longitudinal (vx) of pedestrian object 0 Current value (MPC)";
CM_ SG_ 2432631935 Spd_Y_PedObj0_Cval_MPC "Relative speed lateral (vy) of pedestrian object 0 Current value (MPC)";
CM_ SG_ 2432631935 Dist_X_PedObj0_Cval_MPC "Distance longitudinal (x) of pedestrian object 0 Current value (MPC)";
CM_ SG_ 2432631935 Dist_Y_PedObj0_Cval_MPC "Distance lateral (y) of pedestrian object 0 Current value (MPC)";
CM_ SG_ 2432632191 CRC_SG_MPC_C08_Pkt "Checksum C08 Current value MPC {F9,56,AE,0B,63,BB,18,70,C8,25,7D,D5,32,8A,E2,3F}";
CM_ SG_ 2432632191 SQC_SG_MPC_C08_Pkt "Message Counter C08 Current Value MPC";
CM_ SG_ 2432632191 ConfLvl_PedObj1_Cval "Confidence Level of pedestrian object 1 Current value (MPC)";
CM_ SG_ 2432632191 DtctStat_PedObj1_MPC "Detection State of pedestrian object 1 Current Value (MPC)";
CM_ SG_ 2432632191 Spd_X_PedObj1_Cval_MPC "Relative speed longitudinal (vx) of pedestrian object 1 Current value (MPC)";
CM_ SG_ 2432632191 Spd_Y_PedObj1_Cval_MPC "Relative speed lateral (vy) of pedestrian object 1 Current value (MPC)";
CM_ SG_ 2432632191 Dist_X_PedObj1_Cval_MPC "Distance longitudinal (x) of pedestrian object 1 Current value (MPC)";
CM_ SG_ 2432632191 Dist_Y_PedObj1_Cval_MPC "Distance lateral (y) of pedestrian object 1 Current value (MPC)";
CM_ SG_ 2432632447 CRC_SG_MPC_C09_Pkt "Checksum C09 Current value MPC {5C,AC,FC,51,A1,F1,46,96,E6,3B,8B,DB,30,80,D0,25}";
CM_ SG_ 2432632447 SQC_SG_MPC_C09_Pkt "Message Counter C09 Current Value MPC";
CM_ SG_ 2432632447 ConfLvl_PedObj2_Cval "Confidence Level of pedestrian object 2 Current value (MPC)";
CM_ SG_ 2432632447 DtctStat_PedObj2_MPC "Detection State of pedestrian object 2 Current Value (MPC)";
CM_ SG_ 2432632447 Spd_X_PedObj2_Cval_MPC "Relative speed longitudinal (vx) of pedestrian object 2 Current value (MPC)";
CM_ SG_ 2432632447 Spd_Y_PedObj2_Cval_MPC "Relative speed lateral (vy) of pedestrian object 2 Current value (MPC)";
CM_ SG_ 2432632447 Dist_X_PedObj2_Cval_MPC "Distance longitudinal (x) of pedestrian object 2 Current value (MPC)";
CM_ SG_ 2432632447 Dist_Y_PedObj2_Cval_MPC "Distance lateral (y) of pedestrian object 2 Current value (MPC)";
CM_ SG_ 2432632703 CRC_SG_MPC_C10_Pkt "Checksum C10 Current value MPC {27,80,D9,37,90,E9,47,A0,F9,57,B0,0E,67,C0,1E,77}";
CM_ SG_ 2432632703 SQC_SG_MPC_C10_Pkt "Message Counter C10 Current Value MPC";
CM_ SG_ 2432632703 ConfLvl_PedObj3_Cval "Confidence Level of pedestrian object 3 Current value (MPC)";
CM_ SG_ 2432632703 DtctStat_PedObj3_MPC "Detection State of pedestrian object 3 Current Value (MPC)";
CM_ SG_ 2432632703 Spd_X_PedObj3_Cval_MPC "Relative speed longitudinal (vx) of pedestrian object 3 Current value (MPC)";
CM_ SG_ 2432632703 Spd_Y_PedObj3_Cval_MPC "Relative speed lateral (vy) of pedestrian object 3 Current value (MPC)";
CM_ SG_ 2432632703 Dist_X_PedObj3_Cval_MPC "Distance longitudinal (x) of pedestrian object 3 Current value (MPC)";
CM_ SG_ 2432632703 Dist_Y_PedObj3_Cval_MPC "Distance lateral (y) of pedestrian object 3 Current value (MPC)";
CM_ SG_ 2432632959 CRC_SG_MPC_C11_Pkt "Checksum C11 Current value MPC {1B,3A,59,78,97,B6,D5,F4,18,37,56,75,94,B3,D2,F1}";
CM_ SG_ 2432632959 SQC_SG_MPC_C11_Pkt "Message Counter C11 Current Value MPC";
CM_ SG_ 2432632959 ConfLvl_PedObj4_Cval "Confidence Level of pedestrian object 4 Current value (MPC)";
CM_ SG_ 2432632959 DtctStat_PedObj4_MPC "Detection State of pedestrian object 4 Current Value (MPC)";
CM_ SG_ 2432632959 Spd_X_PedObj4_Cval_MPC "Relative speed longitudinal (vx) of pedestrian object 4 Current value (MPC)";
CM_ SG_ 2432632959 Spd_Y_PedObj4_Cval_MPC "Relative speed lateral (vy) of pedestrian object 4 Current value (MPC)";
CM_ SG_ 2432632959 Dist_X_PedObj4_Cval_MPC "Distance longitudinal (x) of pedestrian object 4 Current value (MPC)";
CM_ SG_ 2432632959 Dist_Y_PedObj4_Cval_MPC "Distance lateral (y) of pedestrian object 4 Current value (MPC)";
CM_ SG_ 2432633215 CRC_SG_MPC_C12_Pkt "Checksum C12 Current value MPC {99,D2,10,49,82,BB,F4,32,6B,A4,DD,1B,54,8D,C6,04}";
CM_ SG_ 2432633215 SQC_SG_MPC_C12_Pkt "Message Counter C12 Current Value MPC";
CM_ SG_ 2432633215 ConfLvl_PedObj5_Cval "Confidence Level of pedestrian object 5 Current value (MPC)";
CM_ SG_ 2432633215 DtctStat_PedObj5_MPC "Detection State of pedestrian object 5 Current Value (MPC)";
CM_ SG_ 2432633215 Spd_X_PedObj5_Cval_MPC "Relative speed longitudinal (vx) of pedestrian object 5 Current value (MPC)";
CM_ SG_ 2432633215 Spd_Y_PedObj5_Cval_MPC "Relative speed lateral (vy) of pedestrian object 5 Current value (MPC)";
CM_ SG_ 2432633215 Dist_X_PedObj5_Cval_MPC "Distance longitudinal (x) of pedestrian object 5 Current value (MPC)";
CM_ SG_ 2432633215 Dist_Y_PedObj5_Cval_MPC "Distance lateral (y) of pedestrian object 5 Current value (MPC)";
CM_ SG_ 2432633471 CRC_SG_MPC_C13_Pkt "Checksum C13 Current value MPC {53,68,7D,92,A7,BC,D1,E6,FB,15,2A,3F,54,69,7E,93}";
CM_ SG_ 2432633471 SQC_SG_MPC_C13_Pkt "Message Counter C13 Current Value MPC";
CM_ SG_ 2432633471 ClassPedObj0_Stat_MPC "classification of pedestrian object 0 Current state (MPC)";
CM_ SG_ 2432633471 NumPedObj0_Cval_MPC "object number of pedestrian object 0 Current value (MPC)";
CM_ SG_ 2432633471 TypePedObj0_Stat_MPC "Object type of pedestrian object 0 Current state (MPC)";
CM_ SG_ 2432633471 StdRng_X_PedObj0_Cval_MPC "Longitudinal (x) standard deviation range gate of pedestrian object 0 Current Value (MPC)";
CM_ SG_ 2432633471 StdRng_Y_PedObj0_Cval_MPC "Lateral (y) standard deviation range gate of pedestrian object 0 Current Value (MPC)";
CM_ SG_ 2432633471 StdRng_Spd_X_PedObj0_Cval_MPC "Longitudinal speed standard deviation range gate of pedestrian object 0 Current Value (MPC)";
CM_ SG_ 2432633471 StdRng_Spd_Y_PedObj0_Cval_MPC "Lateral speed standard deviation range gate of pedestrian object 0 Current Value (MPC)";
CM_ SG_ 2432633471 WidthPedObj0_Cval_MPC "Width of the pedestrian object 0 Current value (MPC)";
CM_ SG_ 2432633471 OLA_PedObj0_Cval_MPC "OLA Pedestrian Object 0 Current value MPC";
CM_ SG_ 2432633471 HeightPedObj0_Cval_MPC "Height over grorund of the pedestrian object 0 Current value (MPC)";
CM_ SG_ 2432633471 LaneAlloc_PedObj0_Cval_MPC "Lane Allocation Pedestrian Object 0 Current value MPC";
CM_ SG_ 2432633471 TurnSgl_PedObj0_Cval_MPC "Turn Signal Pedestrian Object 0 Current value MPC";
CM_ SG_ 2432633471 LaneChgInd_PedObj0_Stat_MPC "Lane Change Indication Pedestrian Object 0 Current state MPC";
CM_ SG_ 2432633727 CRC_SG_MPC_C14_Pkt "Checksum C14 Current value MPC {23,55,87,B9,EB,22,54,86,B8,EA,21,53,85,B7,E9,20}";
CM_ SG_ 2432633727 SQC_SG_MPC_C14_Pkt "Message Counter C14 Current Value MPC";
CM_ SG_ 2432633727 ClassPedObj1_Stat_MPC "classification of pedestrian object 1 Current state (MPC)";
CM_ SG_ 2432633727 NumPedObj1_Cval_MPC "object number of pedestrian object 1 Current value (MPC)";
CM_ SG_ 2432633727 TypePedObj1_Stat_MPC "Object type of pedestrian object 1 Current state (MPC)";
CM_ SG_ 2432633727 StdRng_X_PedObj1_Cval_MPC "Longitudinal (x) standard deviation range gate of pedestrian object 1 Current Value (MPC)";
CM_ SG_ 2432633727 StdRng_Y_PedObj1_Cval_MPC "Lateral (y) standard deviation range gate of pedestrian object 1 Current Value (MPC)";
CM_ SG_ 2432633727 StdRng_Spd_X_PedObj1_Cval_MPC "Longitudinal speed standard deviation range gate of pedestrian object 1 Current Value (MPC)";
CM_ SG_ 2432633727 StdRng_Spd_Y_PedObj1_Cval_MPC "Lateral speed standard deviation range gate of pedestrian object 1 Current Value (MPC)";
CM_ SG_ 2432633727 WidthPedObj1_Cval_MPC "Width of the pedestrian object 1 Current value (MPC)";
CM_ SG_ 2432633727 OLA_PedObj1_Cval_MPC "OLA Pedestrian Object 1 Current value MPC";
CM_ SG_ 2432633727 HeightPedObj1_Cval_MPC "Height over grorund of the pedestrian object 1 Current value (MPC)";
CM_ SG_ 2432633727 LaneAlloc_PedObj1_Cval_MPC "Lane Allocation Pedestrian Object 1 Current value MPC";
CM_ SG_ 2432633727 TurnSgl_PedObj1_Cval_MPC "Turn Signal Pedestrian Object 1 Current value MPC";
CM_ SG_ 2432633727 LaneChgInd_PedObj1_Stat_MPC "Lane Change Indication Pedestrian Object 1 Current state MPC";
CM_ SG_ 2432633983 CRC_SG_MPC_C15_Pkt "Checksum C15 Current value MPC {C6,5C,ED,83,19,AA,40,D1,67,F8,8E,24,B5,4B,DC,72}";
CM_ SG_ 2432633983 SQC_SG_MPC_C15_Pkt "Message Counter C15 Current Value MPC";
CM_ SG_ 2432633983 ClassPedObj2_Stat_MPC "classification of pedestrian object 2 Current state (MPC)";
CM_ SG_ 2432633983 NumPedObj2_Cval_MPC "object number of pedestrian object 2 Current value (MPC)";
CM_ SG_ 2432633983 TypePedObj2_Stat_MPC "Object type of pedestrian object 2 Current state (MPC)";
CM_ SG_ 2432633983 StdRng_X_PedObj2_Cval_MPC "Longitudinal (x) standard deviation range gate of pedestrian object 2 Current Value (MPC)";
CM_ SG_ 2432633983 StdRng_Y_PedObj2_Cval_MPC "Lateral (y) standard deviation range gate of pedestrian object 2 Current Value (MPC)";
CM_ SG_ 2432633983 StdRng_Spd_X_PedObj2_Cval_MPC "Longitudinal speed standard deviation range gate of pedestrian object 2 Current Value (MPC)";
CM_ SG_ 2432633983 StdRng_Spd_Y_PedObj2_Cval_MPC "Lateral speed standard deviation range gate of pedestrian object 2 Current Value (MPC)";
CM_ SG_ 2432633983 WidthPedObj2_Cval_MPC "Width of the pedestrian object 2 Current value (MPC)";
CM_ SG_ 2432633983 OLA_PedObj2_Cval_MPC "OLA Pedestrian Object 2 Current value MPC";
CM_ SG_ 2432633983 HeightPedObj2_Cval_MPC "Height over grorund of the pedestrian object 2 Current value (MPC)";
CM_ SG_ 2432633983 LaneAlloc_PedObj2_Cval_MPC "Lane Allocation Pedestrian Object 2 Current value MPC";
CM_ SG_ 2432633983 TurnSgl_PedObj2_Cval_MPC "Turn Signal Pedestrian Object 2 Current value MPC";
CM_ SG_ 2432633983 LaneChgInd_PedObj2_Stat_MPC "Lane Change Indication Pedestrian Object 2 Current state MPC";
BA_DEF_ SG_  "GenSigTimeout_MPC2" INT 0 65535;
BA_DEF_ BU_  "NodeLayerModules" STRING ;
BA_DEF_  "NMIdType" INT 0 1;
BA_DEF_ BU_  "TpOwnSystemEcuNumber" HEX 0 255;
BA_DEF_ BU_  "TpNodeBaseAddress" HEX 0 65535;
BA_DEF_ BO_  "GenMsgStartValue" STRING ;
BA_DEF_ SG_  "GenSigSNA" STRING ;
BA_DEF_  "Version" HEX 0 255;
BA_DEF_  "NmMessageCount" INT 0 256;
BA_DEF_  "NWID" HEX 0 255;
BA_DEF_  "NBTMax" INT 0 255;
BA_DEF_  "NBTMin" INT 0 255;
BA_DEF_  "SamplePointMax" FLOAT 0 100;
BA_DEF_  "SamplePointMin" FLOAT 0 100;
BA_DEF_  "NWM-Basisadresse" HEX 0 536870911;
BA_DEF_  "NWM-Typ" ENUM  "zentral (MB-W210)","dezentral (MB-OSAN)","keines","VAG-OSEK","BMW-OSEK","PAG-OSEK","DBAG-OSEK";
BA_DEF_ BU_  "NWM-Knoten" ENUM  "nein","ja";
BA_DEF_ BU_  "NWM-Stationsadresse" HEX 0 255;
BA_DEF_ SG_  "FlexKomIsMotorola" ENUM  "nein","ja";
BA_DEF_ SG_  "FlexKomSigLaenge" INT 0 64;
BA_DEF_ SG_  "FlexKomSigStartPos" INT 0 63;
BA_DEF_ SG_  "FlexKomComment" STRING ;
BA_DEF_ SG_  "FlexKomSigName" STRING ;
BA_DEF_ SG_  "FlexKomSID" INT 0 2147483647;
BA_DEF_ SG_  "GenSigStartValue" HEX 0 4294967295;
BA_DEF_ SG_  "FlexKomSigStartValue" STRING ;
BA_DEF_ SG_  "GenSigCycleTime" INT 0 65535;
BA_DEF_ SG_  "GenSigSendType" ENUM  "cyclicX","spontanX","cyclicIfActiveX","spontanWithDelay","cyclicAndSpontanX","cyclicAndSpontanWithDelay","spontanWithRepitition","cyclicIfActiveAndSpontanWD","cyclicIfActiveFast","cyclicWithRepeatOnDemand","none";
BA_DEF_ BO_  "GenMsgNrOfRepetitions" INT 0 65535;
BA_DEF_ BO_  "GenMsgDelayTime" INT 0 65535;
BA_DEF_ BO_  "GenMsgStartDelayTime" INT 0 65535;
BA_DEF_ BO_  "GenMsgCycleTime" INT 0 65535;
BA_DEF_ BO_  "GenMsgSendType" ENUM  "cyclicX","spontanX","cyclicIfActiveX","spontanWithDelay","cyclicAndSpontanX","cyclicAndSpontanWithDelay","spontanWithRepitition","cyclicIfActiveAndSpontanWD","cyclicIfActiveFast","cyclicWithRepeatOnDemand","none";
BA_DEF_  "Baudrate" INT 0 1000000;
BA_DEF_  "VersionWeek" INT 0 53;
BA_DEF_  "VersionYear" INT 0 99;
BA_DEF_ BO_  "DiagResponse" ENUM  "nein","ja";
BA_DEF_ BO_  "DiagRequest" ENUM  "nein","ja";
BA_DEF_ BO_  "DiagState" ENUM  "nein","ja";
BA_DEF_ BO_  "App-Botschaft" ENUM  "nein","ja";
BA_DEF_ BO_  "NWM-Botschaft" ENUM  "nein","ja";
BA_DEF_  "Manufacturer" ENUM  "DBAG","VAG","BMWAG","PAG","GM";
BA_DEF_ BO_  "GenMsgMinAcceptLength" INT -1 8;
BA_DEF_DEF_  "GenSigTimeout_MPC2" 0;
BA_DEF_DEF_  "NodeLayerModules" "dcnm01.dll,CANoeILNLDC.dll";
BA_DEF_DEF_  "NMIdType" 1;
BA_DEF_DEF_  "TpOwnSystemEcuNumber" 0;
BA_DEF_DEF_  "TpNodeBaseAddress" 0;
BA_DEF_DEF_  "GenMsgStartValue" "";
BA_DEF_DEF_  "GenSigSNA" "";
BA_DEF_DEF_  "Version" 160;
BA_DEF_DEF_  "NmMessageCount" 256;
BA_DEF_DEF_  "NWID" 6;
BA_DEF_DEF_  "NBTMax" 20;
BA_DEF_DEF_  "NBTMin" 10;
BA_DEF_DEF_  "SamplePointMax" 88;
BA_DEF_DEF_  "SamplePointMin" 83;
BA_DEF_DEF_  "NWM-Basisadresse" 419397632;
BA_DEF_DEF_  "NWM-Typ" "DBAG-OSEK";
BA_DEF_DEF_  "NWM-Knoten" "nein";
BA_DEF_DEF_  "NWM-Stationsadresse" 0;
BA_DEF_DEF_  "FlexKomIsMotorola" "nein";
BA_DEF_DEF_  "FlexKomSigLaenge" 0;
BA_DEF_DEF_  "FlexKomSigStartPos" 0;
BA_DEF_DEF_  "FlexKomComment" "";
BA_DEF_DEF_  "FlexKomSigName" "";
BA_DEF_DEF_  "FlexKomSID" 0;
BA_DEF_DEF_  "GenSigStartValue" 0;
BA_DEF_DEF_  "FlexKomSigStartValue" "";
BA_DEF_DEF_  "GenSigCycleTime" 0;
BA_DEF_DEF_  "GenSigSendType" "cyclicX";
BA_DEF_DEF_  "GenMsgNrOfRepetitions" 0;
BA_DEF_DEF_  "GenMsgDelayTime" 0;
BA_DEF_DEF_  "GenMsgStartDelayTime" 0;
BA_DEF_DEF_  "GenMsgCycleTime" 0;
BA_DEF_DEF_  "GenMsgSendType" "cyclicX";
BA_DEF_DEF_  "Baudrate" 666666;
BA_DEF_DEF_  "VersionWeek" 50;
BA_DEF_DEF_  "VersionYear" 16;
BA_DEF_DEF_  "DiagResponse" "nein";
BA_DEF_DEF_  "DiagRequest" "nein";
BA_DEF_DEF_  "DiagState" "nein";
BA_DEF_DEF_  "App-Botschaft" "nein";
BA_DEF_DEF_  "NWM-Botschaft" "nein";
BA_DEF_DEF_  "Manufacturer" "DBAG";
BA_DEF_DEF_  "GenMsgMinAcceptLength" -1;
BA_ "VersionWeek" 39;
BA_ "VersionYear" 17;
BA_ "NWM-Stationsadresse" BU_ MPC2 127;
BA_ "NWM-Knoten" BU_ MPC2 1;
BA_ "TpOwnSystemEcuNumber" BU_ MPC2 127;
BA_ "TpNodeBaseAddress" BU_ MPC2 6362;
BA_ "GenMsgStartValue" BO_ 2297437459 "FFFFFFFFFFFFFF00h";
BA_ "GenMsgNrOfRepetitions" BO_ 2297437459 2;
BA_ "GenMsgDelayTime" BO_ 2297437459 20;
BA_ "GenMsgCycleTime" BO_ 2297437459 10;
BA_ "GenMsgMinAcceptLength" BO_ 2297437459 8;
BA_ "GenMsgStartValue" BO_ 2298375691 "FFFFFFFFFFFFFFFFh";
BA_ "GenMsgNrOfRepetitions" BO_ 2298375691 2;
BA_ "GenMsgDelayTime" BO_ 2298375691 20;
BA_ "GenMsgCycleTime" BO_ 2298375691 10;
BA_ "GenMsgMinAcceptLength" BO_ 2298375691 8;
BA_ "GenMsgStartValue" BO_ 2365484055 "FFFFFFFFFFFFFFFFh";
BA_ "GenMsgNrOfRepetitions" BO_ 2365484055 2;
BA_ "GenMsgDelayTime" BO_ 2365484055 20;
BA_ "GenMsgCycleTime" BO_ 2365484055 20;
BA_ "GenMsgMinAcceptLength" BO_ 2365484055 8;
BA_ "GenMsgStartValue" BO_ 2365521931 "FFFFFFFFFFFF0F00h";
BA_ "GenMsgNrOfRepetitions" BO_ 2365521931 2;
BA_ "GenMsgDelayTime" BO_ 2365521931 20;
BA_ "GenMsgCycleTime" BO_ 2365521931 20;
BA_ "GenMsgMinAcceptLength" BO_ 2365521931 8;
BA_ "GenMsgStartValue" BO_ 2365522152 "00F0FFFFFFFFFFFFh";
BA_ "GenMsgNrOfRepetitions" BO_ 2365522152 2;
BA_ "GenMsgDelayTime" BO_ 2365522152 20;
BA_ "GenMsgCycleTime" BO_ 2365522152 20;
BA_ "GenMsgMinAcceptLength" BO_ 2365522152 8;
BA_ "GenMsgStartValue" BO_ 2431648512 "FFFFFFFFFFFFFFFFh";
BA_ "GenMsgNrOfRepetitions" BO_ 2431648512 2;
BA_ "GenMsgDelayTime" BO_ 2431648512 20;
BA_ "GenMsgCycleTime" BO_ 2431648512 50;
BA_ "GenMsgMinAcceptLength" BO_ 2431648512 8;
BA_ "GenMsgStartValue" BO_ 2432617087 "FFFFFFFFFF7FFFFFh";
BA_ "GenMsgNrOfRepetitions" BO_ 2432617087 2;
BA_ "GenMsgDelayTime" BO_ 2432617087 20;
BA_ "GenMsgSendType" BO_ 2432617087 1;
BA_ "GenMsgStartValue" BO_ 2432630817 "FFFFFFFFFFBFFFFFh";
BA_ "GenMsgNrOfRepetitions" BO_ 2432630817 2;
BA_ "GenMsgDelayTime" BO_ 2432630817 20;
BA_ "GenMsgCycleTime" BO_ 2432630817 50;
BA_ "GenMsgMinAcceptLength" BO_ 2432630817 8;
BA_ "GenMsgStartValue" BO_ 2432630911 "00F0FFFFFFFFFFFFh";
BA_ "GenMsgNrOfRepetitions" BO_ 2432630911 2;
BA_ "GenMsgDelayTime" BO_ 2432630911 20;
BA_ "GenMsgCycleTime" BO_ 2432630911 50;
BA_ "GenMsgStartValue" BO_ 2432631051 "00F0FFFFFFFFFFFFh";
BA_ "GenMsgNrOfRepetitions" BO_ 2432631051 2;
BA_ "GenMsgDelayTime" BO_ 2432631051 20;
BA_ "GenMsgCycleTime" BO_ 2432631051 50;
BA_ "GenMsgMinAcceptLength" BO_ 2432631051 8;
BA_ "GenMsgStartDelayTime" BO_ 2432631167 10;
BA_ "GenMsgStartValue" BO_ 2432631167 "8FF0FFFFFFFFFFFFh";
BA_ "GenMsgNrOfRepetitions" BO_ 2432631167 2;
BA_ "GenMsgDelayTime" BO_ 2432631167 20;
BA_ "GenMsgCycleTime" BO_ 2432631167 50;
BA_ "GenMsgStartValue" BO_ 2432631270 "FFFFFFFFFFFF0F00h";
BA_ "GenMsgNrOfRepetitions" BO_ 2432631270 2;
BA_ "GenMsgDelayTime" BO_ 2432631270 20;
BA_ "GenMsgCycleTime" BO_ 2432631270 50;
BA_ "GenMsgMinAcceptLength" BO_ 2432631270 8;
BA_ "GenMsgStartDelayTime" BO_ 2432631423 20;
BA_ "GenMsgStartValue" BO_ 2432631423 "DFF0FFFFFFFFFFFFh";
BA_ "GenMsgNrOfRepetitions" BO_ 2432631423 2;
BA_ "GenMsgDelayTime" BO_ 2432631423 20;
BA_ "GenMsgCycleTime" BO_ 2432631423 50;
BA_ "GenMsgStartDelayTime" BO_ 2432631679 30;
BA_ "GenMsgStartValue" BO_ 2432631679 "4AF0FFFFFFFFFFFFh";
BA_ "GenMsgNrOfRepetitions" BO_ 2432631679 2;
BA_ "GenMsgDelayTime" BO_ 2432631679 20;
BA_ "GenMsgCycleTime" BO_ 2432631679 50;
BA_ "GenMsgStartDelayTime" BO_ 2432631935 60;
BA_ "GenMsgStartValue" BO_ 2432631935 "1CF0FFFFFFFFFFFFh";
BA_ "GenMsgNrOfRepetitions" BO_ 2432631935 2;
BA_ "GenMsgDelayTime" BO_ 2432631935 20;
BA_ "GenMsgCycleTime" BO_ 2432631935 50;
BA_ "GenMsgStartDelayTime" BO_ 2432632191 70;
BA_ "GenMsgStartValue" BO_ 2432632191 "66F0FFFFFFFFFFFFh";
BA_ "GenMsgNrOfRepetitions" BO_ 2432632191 2;
BA_ "GenMsgDelayTime" BO_ 2432632191 20;
BA_ "GenMsgCycleTime" BO_ 2432632191 50;
BA_ "GenMsgStartDelayTime" BO_ 2432632447 80;
BA_ "GenMsgStartValue" BO_ 2432632447 "65F0FFFFFFFFFFFFh";
BA_ "GenMsgNrOfRepetitions" BO_ 2432632447 2;
BA_ "GenMsgDelayTime" BO_ 2432632447 20;
BA_ "GenMsgCycleTime" BO_ 2432632447 50;
BA_ "GenMsgStartDelayTime" BO_ 2432632703 90;
BA_ "GenMsgStartValue" BO_ 2432632703 "78F0FFFFFFFFFFFFh";
BA_ "GenMsgNrOfRepetitions" BO_ 2432632703 2;
BA_ "GenMsgDelayTime" BO_ 2432632703 20;
BA_ "GenMsgCycleTime" BO_ 2432632703 50;
BA_ "GenMsgStartDelayTime" BO_ 2432632959 100;
BA_ "GenMsgStartValue" BO_ 2432632959 "4EF0FFFFFFFFFFFFh";
BA_ "GenMsgNrOfRepetitions" BO_ 2432632959 2;
BA_ "GenMsgDelayTime" BO_ 2432632959 20;
BA_ "GenMsgCycleTime" BO_ 2432632959 50;
BA_ "GenMsgStartValue" BO_ 2432633215 "F3F0FFFFFFFFFFFFh";
BA_ "GenMsgNrOfRepetitions" BO_ 2432633215 2;
BA_ "GenMsgDelayTime" BO_ 2432633215 20;
BA_ "GenMsgCycleTime" BO_ 2432633215 50;
BA_ "GenMsgStartDelayTime" BO_ 2432633471 10;
BA_ "GenMsgStartValue" BO_ 2432633471 "FFF0FFFFFFFFFFFFh";
BA_ "GenMsgNrOfRepetitions" BO_ 2432633471 2;
BA_ "GenMsgDelayTime" BO_ 2432633471 20;
BA_ "GenMsgCycleTime" BO_ 2432633471 50;
BA_ "GenMsgStartDelayTime" BO_ 2432633727 20;
BA_ "GenMsgStartValue" BO_ 2432633727 "C4F0FFFFFFFFFFFFh";
BA_ "GenMsgNrOfRepetitions" BO_ 2432633727 2;
BA_ "GenMsgDelayTime" BO_ 2432633727 20;
BA_ "GenMsgCycleTime" BO_ 2432633727 50;
BA_ "GenMsgStartDelayTime" BO_ 2432633983 30;
BA_ "GenMsgStartValue" BO_ 2432633983 "21F0FFFFFFFFFFFFh";
BA_ "GenMsgNrOfRepetitions" BO_ 2432633983 2;
BA_ "GenMsgDelayTime" BO_ 2432633983 20;
BA_ "GenMsgCycleTime" BO_ 2432633983 50;
BA_ "GenSigStartValue" SG_ 3221225472 IHC_StaticLightDist 65535;
BA_ "GenSigSNA" SG_ 2297437459 StwAngl_Cval_SWS "FFFFh";
BA_ "FlexKomIsMotorola" SG_ 2297437459 StwAngl_Cval_SWS 1;
BA_ "FlexKomComment" SG_ 2297437459 StwAngl_Cval_SWS "Proprietary SAS1";
BA_ "FlexKomSigName" SG_ 2297437459 StwAngl_Cval_SWS "SAS1_Pkt_Prop";
BA_ "FlexKomSigLaenge" SG_ 2297437459 StwAngl_Cval_SWS 64;
BA_ "FlexKomSigStartPos" SG_ 2297437459 StwAngl_Cval_SWS 7;
BA_ "FlexKomSID" SG_ 2297437459 StwAngl_Cval_SWS 100663776;
BA_ "GenSigTimeout_MPC2" SG_ 2297437459 StwAngl_Cval_SWS 105;
BA_ "GenSigStartValue" SG_ 2297437459 StwAngl_Cval_SWS 65535;
BA_ "FlexKomSigStartValue" SG_ 2297437459 StwAngl_Cval_SWS "FFFFFFFFFFFFFF00h";
BA_ "GenSigCycleTime" SG_ 2297437459 StwAngl_Cval_SWS 10;
BA_ "GenSigSNA" SG_ 2297437459 StwTurnCntr_Cval_SWS "3Fh";
BA_ "FlexKomIsMotorola" SG_ 2297437459 StwTurnCntr_Cval_SWS 1;
BA_ "FlexKomComment" SG_ 2297437459 StwTurnCntr_Cval_SWS "Proprietary SAS1";
BA_ "FlexKomSigName" SG_ 2297437459 StwTurnCntr_Cval_SWS "SAS1_Pkt_Prop";
BA_ "FlexKomSigLaenge" SG_ 2297437459 StwTurnCntr_Cval_SWS 64;
BA_ "FlexKomSigStartPos" SG_ 2297437459 StwTurnCntr_Cval_SWS 7;
BA_ "FlexKomSID" SG_ 2297437459 StwTurnCntr_Cval_SWS 100663776;
BA_ "GenSigTimeout_MPC2" SG_ 2297437459 StwTurnCntr_Cval_SWS 105;
BA_ "GenSigStartValue" SG_ 2297437459 StwTurnCntr_Cval_SWS 63;
BA_ "FlexKomSigStartValue" SG_ 2297437459 StwTurnCntr_Cval_SWS "FFFFFFFFFFFFFF00h";
BA_ "GenSigCycleTime" SG_ 2297437459 StwTurnCntr_Cval_SWS 10;
BA_ "GenSigSNA" SG_ 2297437459 StwAnglSensType_Cval_SWS "3h";
BA_ "FlexKomIsMotorola" SG_ 2297437459 StwAnglSensType_Cval_SWS 1;
BA_ "FlexKomComment" SG_ 2297437459 StwAnglSensType_Cval_SWS "Proprietary SAS1";
BA_ "FlexKomSigName" SG_ 2297437459 StwAnglSensType_Cval_SWS "SAS1_Pkt_Prop";
BA_ "FlexKomSigLaenge" SG_ 2297437459 StwAnglSensType_Cval_SWS 64;
BA_ "FlexKomSigStartPos" SG_ 2297437459 StwAnglSensType_Cval_SWS 7;
BA_ "FlexKomSID" SG_ 2297437459 StwAnglSensType_Cval_SWS 100663776;
BA_ "GenSigTimeout_MPC2" SG_ 2297437459 StwAnglSensType_Cval_SWS 105;
BA_ "GenSigStartValue" SG_ 2297437459 StwAnglSensType_Cval_SWS 3;
BA_ "FlexKomSigStartValue" SG_ 2297437459 StwAnglSensType_Cval_SWS "FFFFFFFFFFFFFF00h";
BA_ "GenSigCycleTime" SG_ 2297437459 StwAnglSensType_Cval_SWS 10;
BA_ "GenSigSNA" SG_ 2298375691 SpdFtAxleLtWhl_Cval "FFFFh";
BA_ "FlexKomIsMotorola" SG_ 2298375691 SpdFtAxleLtWhl_Cval 1;
BA_ "FlexKomComment" SG_ 2298375691 SpdFtAxleLtWhl_Cval "Complete HRW";
BA_ "FlexKomSigName" SG_ 2298375691 SpdFtAxleLtWhl_Cval "HRW_Pkt";
BA_ "FlexKomSigLaenge" SG_ 2298375691 SpdFtAxleLtWhl_Cval 64;
BA_ "FlexKomSigStartPos" SG_ 2298375691 SpdFtAxleLtWhl_Cval 7;
BA_ "FlexKomSID" SG_ 2298375691 SpdFtAxleLtWhl_Cval 100663773;
BA_ "GenSigTimeout_MPC2" SG_ 2298375691 SpdFtAxleLtWhl_Cval 205;
BA_ "GenSigStartValue" SG_ 2298375691 SpdFtAxleLtWhl_Cval 65535;
BA_ "FlexKomSigStartValue" SG_ 2298375691 SpdFtAxleLtWhl_Cval "FFFFFFFFFFFFFFFFh";
BA_ "GenSigCycleTime" SG_ 2298375691 SpdFtAxleLtWhl_Cval 10;
BA_ "GenSigSNA" SG_ 2298375691 SpdFtAxleRtWhl_Cval "FFFFh";
BA_ "FlexKomIsMotorola" SG_ 2298375691 SpdFtAxleRtWhl_Cval 1;
BA_ "FlexKomComment" SG_ 2298375691 SpdFtAxleRtWhl_Cval "Complete HRW";
BA_ "FlexKomSigName" SG_ 2298375691 SpdFtAxleRtWhl_Cval "HRW_Pkt";
BA_ "FlexKomSigLaenge" SG_ 2298375691 SpdFtAxleRtWhl_Cval 64;
BA_ "FlexKomSigStartPos" SG_ 2298375691 SpdFtAxleRtWhl_Cval 7;
BA_ "FlexKomSID" SG_ 2298375691 SpdFtAxleRtWhl_Cval 100663773;
BA_ "GenSigTimeout_MPC2" SG_ 2298375691 SpdFtAxleRtWhl_Cval 205;
BA_ "GenSigStartValue" SG_ 2298375691 SpdFtAxleRtWhl_Cval 65535;
BA_ "FlexKomSigStartValue" SG_ 2298375691 SpdFtAxleRtWhl_Cval "FFFFFFFFFFFFFFFFh";
BA_ "GenSigCycleTime" SG_ 2298375691 SpdFtAxleRtWhl_Cval 10;
BA_ "GenSigSNA" SG_ 2298375691 SpdR_AxleLtWhl_Cval "FFFFh";
BA_ "FlexKomIsMotorola" SG_ 2298375691 SpdR_AxleLtWhl_Cval 1;
BA_ "FlexKomComment" SG_ 2298375691 SpdR_AxleLtWhl_Cval "Complete HRW";
BA_ "FlexKomSigName" SG_ 2298375691 SpdR_AxleLtWhl_Cval "HRW_Pkt";
BA_ "FlexKomSigLaenge" SG_ 2298375691 SpdR_AxleLtWhl_Cval 64;
BA_ "FlexKomSigStartPos" SG_ 2298375691 SpdR_AxleLtWhl_Cval 7;
BA_ "FlexKomSID" SG_ 2298375691 SpdR_AxleLtWhl_Cval 100663773;
BA_ "GenSigTimeout_MPC2" SG_ 2298375691 SpdR_AxleLtWhl_Cval 205;
BA_ "GenSigStartValue" SG_ 2298375691 SpdR_AxleLtWhl_Cval 65535;
BA_ "FlexKomSigStartValue" SG_ 2298375691 SpdR_AxleLtWhl_Cval "FFFFFFFFFFFFFFFFh";
BA_ "GenSigCycleTime" SG_ 2298375691 SpdR_AxleLtWhl_Cval 10;
BA_ "GenSigSNA" SG_ 2298375691 SpdR_AxleRtWhl_Cval "FFFFh";
BA_ "FlexKomIsMotorola" SG_ 2298375691 SpdR_AxleRtWhl_Cval 1;
BA_ "FlexKomComment" SG_ 2298375691 SpdR_AxleRtWhl_Cval "Complete HRW";
BA_ "FlexKomSigName" SG_ 2298375691 SpdR_AxleRtWhl_Cval "HRW_Pkt";
BA_ "FlexKomSigLaenge" SG_ 2298375691 SpdR_AxleRtWhl_Cval 64;
BA_ "FlexKomSigStartPos" SG_ 2298375691 SpdR_AxleRtWhl_Cval 7;
BA_ "FlexKomSID" SG_ 2298375691 SpdR_AxleRtWhl_Cval 100663773;
BA_ "GenSigTimeout_MPC2" SG_ 2298375691 SpdR_AxleRtWhl_Cval 205;
BA_ "GenSigStartValue" SG_ 2298375691 SpdR_AxleRtWhl_Cval 65535;
BA_ "FlexKomSigStartValue" SG_ 2298375691 SpdR_AxleRtWhl_Cval "FFFFFFFFFFFFFFFFh";
BA_ "GenSigCycleTime" SG_ 2298375691 SpdR_AxleRtWhl_Cval 10;
BA_ "GenSigSNA" SG_ 2365484055 DirInd_Stat_ICUC "3h";
BA_ "FlexKomIsMotorola" SG_ 2365484055 DirInd_Stat_ICUC 1;
BA_ "FlexKomComment" SG_ 2365484055 DirInd_Stat_ICUC "Tachograph Current state from ICUC";
BA_ "FlexKomSigName" SG_ 2365484055 DirInd_Stat_ICUC "Sys_Stat_ICUC";
BA_ "FlexKomSigLaenge" SG_ 2365484055 DirInd_Stat_ICUC 8;
BA_ "FlexKomSigStartPos" SG_ 2365484055 DirInd_Stat_ICUC 31;
BA_ "FlexKomSID" SG_ 2365484055 DirInd_Stat_ICUC 100664299;
BA_ "GenSigTimeout_MPC2" SG_ 2365484055 DirInd_Stat_ICUC 210;
BA_ "GenSigStartValue" SG_ 2365484055 DirInd_Stat_ICUC 3;
BA_ "FlexKomSigStartValue" SG_ 2365484055 DirInd_Stat_ICUC "FFh";
BA_ "GenSigCycleTime" SG_ 2365484055 DirInd_Stat_ICUC 20;
BA_ "GenSigSNA" SG_ 2365484055 VehSpd_Cval_ICUC "FFFFh";
BA_ "FlexKomIsMotorola" SG_ 2365484055 VehSpd_Cval_ICUC 1;
BA_ "FlexKomComment" SG_ 2365484055 VehSpd_Cval_ICUC "Vehicle Speed Current value ICUC";
BA_ "FlexKomSigName" SG_ 2365484055 VehSpd_Cval_ICUC "VehSpd_ICUC";
BA_ "FlexKomSigLaenge" SG_ 2365484055 VehSpd_Cval_ICUC 16;
BA_ "FlexKomSigStartPos" SG_ 2365484055 VehSpd_Cval_ICUC 55;
BA_ "FlexKomSID" SG_ 2365484055 VehSpd_Cval_ICUC 100663689;
BA_ "GenSigTimeout_MPC2" SG_ 2365484055 VehSpd_Cval_ICUC 210;
BA_ "GenSigStartValue" SG_ 2365484055 VehSpd_Cval_ICUC 65535;
BA_ "FlexKomSigStartValue" SG_ 2365484055 VehSpd_Cval_ICUC "FFFFh";
BA_ "GenSigCycleTime" SG_ 2365484055 VehSpd_Cval_ICUC 20;
BA_ "GenSigSNA" SG_ 2365521931 VehSpd_Cval_BS "FFh";
BA_ "FlexKomIsMotorola" SG_ 2365521931 VehSpd_Cval_BS 1;
BA_ "FlexKomComment" SG_ 2365521931 VehSpd_Cval_BS "BS E4 Packet";
BA_ "FlexKomSigName" SG_ 2365521931 VehSpd_Cval_BS "BS_E4_Pkt";
BA_ "FlexKomSigLaenge" SG_ 2365521931 VehSpd_Cval_BS 64;
BA_ "FlexKomSigStartPos" SG_ 2365521931 VehSpd_Cval_BS 7;
BA_ "FlexKomSID" SG_ 2365521931 VehSpd_Cval_BS 100664223;
BA_ "GenSigTimeout_MPC2" SG_ 2365521931 VehSpd_Cval_BS 210;
BA_ "GenSigStartValue" SG_ 2365521931 VehSpd_Cval_BS 255;
BA_ "FlexKomSigStartValue" SG_ 2365521931 VehSpd_Cval_BS "FFFFFFFFFFFF0F00h";
BA_ "GenSigCycleTime" SG_ 2365521931 VehSpd_Cval_BS 20;
BA_ "GenSigSNA" SG_ 2365521931 MC_E4_Cval_BS "0h";
BA_ "FlexKomIsMotorola" SG_ 2365521931 MC_E4_Cval_BS 1;
BA_ "FlexKomComment" SG_ 2365521931 MC_E4_Cval_BS "BS E4 Packet";
BA_ "FlexKomSigName" SG_ 2365521931 MC_E4_Cval_BS "BS_E4_Pkt";
BA_ "FlexKomSigLaenge" SG_ 2365521931 MC_E4_Cval_BS 64;
BA_ "FlexKomSigStartPos" SG_ 2365521931 MC_E4_Cval_BS 7;
BA_ "FlexKomSID" SG_ 2365521931 MC_E4_Cval_BS 100664223;
BA_ "GenSigTimeout_MPC2" SG_ 2365521931 MC_E4_Cval_BS 210;
BA_ "FlexKomSigStartValue" SG_ 2365521931 MC_E4_Cval_BS "FFFFFFFFFFFF0F00h";
BA_ "GenSigCycleTime" SG_ 2365521931 MC_E4_Cval_BS 20;
BA_ "GenSigSNA" SG_ 2365521931 CRC_E4_Cval_BS "0h";
BA_ "FlexKomIsMotorola" SG_ 2365521931 CRC_E4_Cval_BS 1;
BA_ "FlexKomComment" SG_ 2365521931 CRC_E4_Cval_BS "BS E4 Packet";
BA_ "FlexKomSigName" SG_ 2365521931 CRC_E4_Cval_BS "BS_E4_Pkt";
BA_ "FlexKomSigLaenge" SG_ 2365521931 CRC_E4_Cval_BS 64;
BA_ "FlexKomSigStartPos" SG_ 2365521931 CRC_E4_Cval_BS 7;
BA_ "FlexKomSID" SG_ 2365521931 CRC_E4_Cval_BS 100664223;
BA_ "GenSigTimeout_MPC2" SG_ 2365521931 CRC_E4_Cval_BS 210;
BA_ "FlexKomSigStartValue" SG_ 2365521931 CRC_E4_Cval_BS "FFFFFFFFFFFF0F00h";
BA_ "GenSigCycleTime" SG_ 2365521931 CRC_E4_Cval_BS 20;
BA_ "GenSigSNA" SG_ 2365522152 CRC_SG_VRDU_C03_Pkt "0h";
BA_ "FlexKomIsMotorola" SG_ 2365522152 CRC_SG_VRDU_C03_Pkt 1;
BA_ "FlexKomComment" SG_ 2365522152 CRC_SG_VRDU_C03_Pkt "VRDU C03 Pkt";
BA_ "FlexKomSigName" SG_ 2365522152 CRC_SG_VRDU_C03_Pkt "VRDU_C03_Pkt";
BA_ "FlexKomSigLaenge" SG_ 2365522152 CRC_SG_VRDU_C03_Pkt 64;
BA_ "FlexKomSigStartPos" SG_ 2365522152 CRC_SG_VRDU_C03_Pkt 7;
BA_ "FlexKomSID" SG_ 2365522152 CRC_SG_VRDU_C03_Pkt 100678487;
BA_ "GenSigTimeout_MPC2" SG_ 2365522152 CRC_SG_VRDU_C03_Pkt 210;
BA_ "FlexKomSigStartValue" SG_ 2365522152 CRC_SG_VRDU_C03_Pkt "00F0FFFFFFFFFFFFh";
BA_ "GenSigCycleTime" SG_ 2365522152 CRC_SG_VRDU_C03_Pkt 20;
BA_ "GenSigSNA" SG_ 2365522152 SQC_SG_VRDU_C03_Pkt "0h";
BA_ "FlexKomIsMotorola" SG_ 2365522152 SQC_SG_VRDU_C03_Pkt 1;
BA_ "FlexKomComment" SG_ 2365522152 SQC_SG_VRDU_C03_Pkt "VRDU C03 Pkt";
BA_ "FlexKomSigName" SG_ 2365522152 SQC_SG_VRDU_C03_Pkt "VRDU_C03_Pkt";
BA_ "FlexKomSigLaenge" SG_ 2365522152 SQC_SG_VRDU_C03_Pkt 64;
BA_ "FlexKomSigStartPos" SG_ 2365522152 SQC_SG_VRDU_C03_Pkt 7;
BA_ "FlexKomSID" SG_ 2365522152 SQC_SG_VRDU_C03_Pkt 100678487;
BA_ "GenSigTimeout_MPC2" SG_ 2365522152 SQC_SG_VRDU_C03_Pkt 210;
BA_ "FlexKomSigStartValue" SG_ 2365522152 SQC_SG_VRDU_C03_Pkt "00F0FFFFFFFFFFFFh";
BA_ "GenSigCycleTime" SG_ 2365522152 SQC_SG_VRDU_C03_Pkt 20;
BA_ "GenSigSNA" SG_ 2365522152 TmStmp_Cval_VRDU "FFh";
BA_ "FlexKomIsMotorola" SG_ 2365522152 TmStmp_Cval_VRDU 1;
BA_ "FlexKomComment" SG_ 2365522152 TmStmp_Cval_VRDU "VRDU C03 Pkt";
BA_ "FlexKomSigName" SG_ 2365522152 TmStmp_Cval_VRDU "VRDU_C03_Pkt";
BA_ "FlexKomSigLaenge" SG_ 2365522152 TmStmp_Cval_VRDU 64;
BA_ "FlexKomSigStartPos" SG_ 2365522152 TmStmp_Cval_VRDU 7;
BA_ "FlexKomSID" SG_ 2365522152 TmStmp_Cval_VRDU 100678487;
BA_ "GenSigTimeout_MPC2" SG_ 2365522152 TmStmp_Cval_VRDU 210;
BA_ "GenSigStartValue" SG_ 2365522152 TmStmp_Cval_VRDU 255;
BA_ "FlexKomSigStartValue" SG_ 2365522152 TmStmp_Cval_VRDU "00F0FFFFFFFFFFFFh";
BA_ "GenSigCycleTime" SG_ 2365522152 TmStmp_Cval_VRDU 20;
BA_ "GenSigSNA" SG_ 2365522152 Accel_Y_Cval_VRDU "FFh";
BA_ "FlexKomIsMotorola" SG_ 2365522152 Accel_Y_Cval_VRDU 1;
BA_ "FlexKomComment" SG_ 2365522152 Accel_Y_Cval_VRDU "VRDU C03 Pkt";
BA_ "FlexKomSigName" SG_ 2365522152 Accel_Y_Cval_VRDU "VRDU_C03_Pkt";
BA_ "FlexKomSigLaenge" SG_ 2365522152 Accel_Y_Cval_VRDU 64;
BA_ "FlexKomSigStartPos" SG_ 2365522152 Accel_Y_Cval_VRDU 7;
BA_ "FlexKomSID" SG_ 2365522152 Accel_Y_Cval_VRDU 100678487;
BA_ "GenSigTimeout_MPC2" SG_ 2365522152 Accel_Y_Cval_VRDU 210;
BA_ "GenSigStartValue" SG_ 2365522152 Accel_Y_Cval_VRDU 255;
BA_ "FlexKomSigStartValue" SG_ 2365522152 Accel_Y_Cval_VRDU "00F0FFFFFFFFFFFFh";
BA_ "GenSigCycleTime" SG_ 2365522152 Accel_Y_Cval_VRDU 20;
BA_ "GenSigSNA" SG_ 2365522152 StAngl_Cval_VRDU "FFFFh";
BA_ "FlexKomIsMotorola" SG_ 2365522152 StAngl_Cval_VRDU 1;
BA_ "FlexKomComment" SG_ 2365522152 StAngl_Cval_VRDU "VRDU C03 Pkt";
BA_ "FlexKomSigName" SG_ 2365522152 StAngl_Cval_VRDU "VRDU_C03_Pkt";
BA_ "FlexKomSigLaenge" SG_ 2365522152 StAngl_Cval_VRDU 64;
BA_ "FlexKomSigStartPos" SG_ 2365522152 StAngl_Cval_VRDU 7;
BA_ "FlexKomSID" SG_ 2365522152 StAngl_Cval_VRDU 100678487;
BA_ "GenSigTimeout_MPC2" SG_ 2365522152 StAngl_Cval_VRDU 210;
BA_ "GenSigStartValue" SG_ 2365522152 StAngl_Cval_VRDU 65535;
BA_ "FlexKomSigStartValue" SG_ 2365522152 StAngl_Cval_VRDU "00F0FFFFFFFFFFFFh";
BA_ "GenSigCycleTime" SG_ 2365522152 StAngl_Cval_VRDU 20;
BA_ "GenSigSNA" SG_ 2431648512 AccelPdlKickDnSw_Rq "3h";
BA_ "FlexKomIsMotorola" SG_ 2431648512 AccelPdlKickDnSw_Rq 1;
BA_ "FlexKomComment" SG_ 2431648512 AccelPdlKickDnSw_Rq "Accelerator Pedal Kickdown Switch";
BA_ "FlexKomSigName" SG_ 2431648512 AccelPdlKickDnSw_Rq "AccelPdlKickDnSw_Rq";
BA_ "FlexKomSigLaenge" SG_ 2431648512 AccelPdlKickDnSw_Rq 2;
BA_ "FlexKomSigStartPos" SG_ 2431648512 AccelPdlKickDnSw_Rq 3;
BA_ "FlexKomSID" SG_ 2431648512 AccelPdlKickDnSw_Rq 100663811;
BA_ "GenSigTimeout_MPC2" SG_ 2431648512 AccelPdlKickDnSw_Rq 525;
BA_ "GenSigStartValue" SG_ 2431648512 AccelPdlKickDnSw_Rq 3;
BA_ "FlexKomSigStartValue" SG_ 2431648512 AccelPdlKickDnSw_Rq "03h";
BA_ "GenSigCycleTime" SG_ 2431648512 AccelPdlKickDnSw_Rq 50;
BA_ "GenSigSNA" SG_ 2431648512 AccelPdlPosn_Cval "FFh";
BA_ "FlexKomIsMotorola" SG_ 2431648512 AccelPdlPosn_Cval 1;
BA_ "FlexKomComment" SG_ 2431648512 AccelPdlPosn_Cval "Accelerator Pedal Position Current value";
BA_ "FlexKomSigName" SG_ 2431648512 AccelPdlPosn_Cval "AccelPdlPosn_Cval";
BA_ "FlexKomSigLaenge" SG_ 2431648512 AccelPdlPosn_Cval 8;
BA_ "FlexKomSigStartPos" SG_ 2431648512 AccelPdlPosn_Cval 15;
BA_ "FlexKomSID" SG_ 2431648512 AccelPdlPosn_Cval 100663781;
BA_ "GenSigTimeout_MPC2" SG_ 2431648512 AccelPdlPosn_Cval 525;
BA_ "GenSigStartValue" SG_ 2431648512 AccelPdlPosn_Cval 255;
BA_ "FlexKomSigStartValue" SG_ 2431648512 AccelPdlPosn_Cval "FFh";
BA_ "GenSigCycleTime" SG_ 2431648512 AccelPdlPosn_Cval 50;
BA_ "GenSigSNA" SG_ 2432617087 DTC_PL_Stat_MPC "3h";
BA_ "FlexKomIsMotorola" SG_ 2432617087 DTC_PL_Stat_MPC 1;
BA_ "FlexKomComment" SG_ 2432617087 DTC_PL_Stat_MPC "Diagnostic Message DM1";
BA_ "FlexKomSigName" SG_ 2432617087 DTC_PL_Stat_MPC "DM1_Pkt_MPC";
BA_ "FlexKomSigLaenge" SG_ 2432617087 DTC_PL_Stat_MPC 64;
BA_ "FlexKomSigStartPos" SG_ 2432617087 DTC_PL_Stat_MPC 7;
BA_ "FlexKomSID" SG_ 2432617087 DTC_PL_Stat_MPC 100676537;
BA_ "GenSigStartValue" SG_ 2432617087 DTC_PL_Stat_MPC 3;
BA_ "FlexKomSigStartValue" SG_ 2432617087 DTC_PL_Stat_MPC "FFFFFFFFFF7FFFFFh";
BA_ "GenSigSendType" SG_ 2432617087 DTC_PL_Stat_MPC 1;
BA_ "GenSigSNA" SG_ 2432617087 DTC_AWL_Stat_MPC "3h";
BA_ "FlexKomIsMotorola" SG_ 2432617087 DTC_AWL_Stat_MPC 1;
BA_ "FlexKomComment" SG_ 2432617087 DTC_AWL_Stat_MPC "Diagnostic Message DM1";
BA_ "FlexKomSigName" SG_ 2432617087 DTC_AWL_Stat_MPC "DM1_Pkt_MPC";
BA_ "FlexKomSigLaenge" SG_ 2432617087 DTC_AWL_Stat_MPC 64;
BA_ "FlexKomSigStartPos" SG_ 2432617087 DTC_AWL_Stat_MPC 7;
BA_ "FlexKomSID" SG_ 2432617087 DTC_AWL_Stat_MPC 100676537;
BA_ "GenSigStartValue" SG_ 2432617087 DTC_AWL_Stat_MPC 3;
BA_ "FlexKomSigStartValue" SG_ 2432617087 DTC_AWL_Stat_MPC "FFFFFFFFFF7FFFFFh";
BA_ "GenSigSendType" SG_ 2432617087 DTC_AWL_Stat_MPC 1;
BA_ "GenSigSNA" SG_ 2432617087 DTC_RSL_Stat_MPC "3h";
BA_ "FlexKomIsMotorola" SG_ 2432617087 DTC_RSL_Stat_MPC 1;
BA_ "FlexKomComment" SG_ 2432617087 DTC_RSL_Stat_MPC "Diagnostic Message DM1";
BA_ "FlexKomSigName" SG_ 2432617087 DTC_RSL_Stat_MPC "DM1_Pkt_MPC";
BA_ "FlexKomSigLaenge" SG_ 2432617087 DTC_RSL_Stat_MPC 64;
BA_ "FlexKomSigStartPos" SG_ 2432617087 DTC_RSL_Stat_MPC 7;
BA_ "FlexKomSID" SG_ 2432617087 DTC_RSL_Stat_MPC 100676537;
BA_ "GenSigStartValue" SG_ 2432617087 DTC_RSL_Stat_MPC 3;
BA_ "FlexKomSigStartValue" SG_ 2432617087 DTC_RSL_Stat_MPC "FFFFFFFFFF7FFFFFh";
BA_ "GenSigSendType" SG_ 2432617087 DTC_RSL_Stat_MPC 1;
BA_ "GenSigSNA" SG_ 2432617087 DTC_MIL_Stat_MPC "3h";
BA_ "FlexKomIsMotorola" SG_ 2432617087 DTC_MIL_Stat_MPC 1;
BA_ "FlexKomComment" SG_ 2432617087 DTC_MIL_Stat_MPC "Diagnostic Message DM1";
BA_ "FlexKomSigName" SG_ 2432617087 DTC_MIL_Stat_MPC "DM1_Pkt_MPC";
BA_ "FlexKomSigLaenge" SG_ 2432617087 DTC_MIL_Stat_MPC 64;
BA_ "FlexKomSigStartPos" SG_ 2432617087 DTC_MIL_Stat_MPC 7;
BA_ "FlexKomSID" SG_ 2432617087 DTC_MIL_Stat_MPC 100676537;
BA_ "GenSigStartValue" SG_ 2432617087 DTC_MIL_Stat_MPC 3;
BA_ "FlexKomSigStartValue" SG_ 2432617087 DTC_MIL_Stat_MPC "FFFFFFFFFF7FFFFFh";
BA_ "GenSigSendType" SG_ 2432617087 DTC_MIL_Stat_MPC 1;
BA_ "GenSigSNA" SG_ 2432617087 DTC_PL_Flash_Stat_MPC "3h";
BA_ "FlexKomIsMotorola" SG_ 2432617087 DTC_PL_Flash_Stat_MPC 1;
BA_ "FlexKomComment" SG_ 2432617087 DTC_PL_Flash_Stat_MPC "Diagnostic Message DM1";
BA_ "FlexKomSigName" SG_ 2432617087 DTC_PL_Flash_Stat_MPC "DM1_Pkt_MPC";
BA_ "FlexKomSigLaenge" SG_ 2432617087 DTC_PL_Flash_Stat_MPC 64;
BA_ "FlexKomSigStartPos" SG_ 2432617087 DTC_PL_Flash_Stat_MPC 7;
BA_ "FlexKomSID" SG_ 2432617087 DTC_PL_Flash_Stat_MPC 100676537;
BA_ "GenSigStartValue" SG_ 2432617087 DTC_PL_Flash_Stat_MPC 3;
BA_ "FlexKomSigStartValue" SG_ 2432617087 DTC_PL_Flash_Stat_MPC "FFFFFFFFFF7FFFFFh";
BA_ "GenSigSendType" SG_ 2432617087 DTC_PL_Flash_Stat_MPC 1;
BA_ "GenSigSNA" SG_ 2432617087 DTC_AWL_Flash_Stat_MPC "3h";
BA_ "FlexKomIsMotorola" SG_ 2432617087 DTC_AWL_Flash_Stat_MPC 1;
BA_ "FlexKomComment" SG_ 2432617087 DTC_AWL_Flash_Stat_MPC "Diagnostic Message DM1";
BA_ "FlexKomSigName" SG_ 2432617087 DTC_AWL_Flash_Stat_MPC "DM1_Pkt_MPC";
BA_ "FlexKomSigLaenge" SG_ 2432617087 DTC_AWL_Flash_Stat_MPC 64;
BA_ "FlexKomSigStartPos" SG_ 2432617087 DTC_AWL_Flash_Stat_MPC 7;
BA_ "FlexKomSID" SG_ 2432617087 DTC_AWL_Flash_Stat_MPC 100676537;
BA_ "GenSigStartValue" SG_ 2432617087 DTC_AWL_Flash_Stat_MPC 3;
BA_ "FlexKomSigStartValue" SG_ 2432617087 DTC_AWL_Flash_Stat_MPC "FFFFFFFFFF7FFFFFh";
BA_ "GenSigSendType" SG_ 2432617087 DTC_AWL_Flash_Stat_MPC 1;
BA_ "GenSigSNA" SG_ 2432617087 DTC_RSL_Flash_Stat_MPC "3h";
BA_ "FlexKomIsMotorola" SG_ 2432617087 DTC_RSL_Flash_Stat_MPC 1;
BA_ "FlexKomComment" SG_ 2432617087 DTC_RSL_Flash_Stat_MPC "Diagnostic Message DM1";
BA_ "FlexKomSigName" SG_ 2432617087 DTC_RSL_Flash_Stat_MPC "DM1_Pkt_MPC";
BA_ "FlexKomSigLaenge" SG_ 2432617087 DTC_RSL_Flash_Stat_MPC 64;
BA_ "FlexKomSigStartPos" SG_ 2432617087 DTC_RSL_Flash_Stat_MPC 7;
BA_ "FlexKomSID" SG_ 2432617087 DTC_RSL_Flash_Stat_MPC 100676537;
BA_ "GenSigStartValue" SG_ 2432617087 DTC_RSL_Flash_Stat_MPC 3;
BA_ "FlexKomSigStartValue" SG_ 2432617087 DTC_RSL_Flash_Stat_MPC "FFFFFFFFFF7FFFFFh";
BA_ "GenSigSendType" SG_ 2432617087 DTC_RSL_Flash_Stat_MPC 1;
BA_ "GenSigSNA" SG_ 2432617087 DTC_MIL_Flash_Stat_MPC "3h";
BA_ "FlexKomIsMotorola" SG_ 2432617087 DTC_MIL_Flash_Stat_MPC 1;
BA_ "FlexKomComment" SG_ 2432617087 DTC_MIL_Flash_Stat_MPC "Diagnostic Message DM1";
BA_ "FlexKomSigName" SG_ 2432617087 DTC_MIL_Flash_Stat_MPC "DM1_Pkt_MPC";
BA_ "FlexKomSigLaenge" SG_ 2432617087 DTC_MIL_Flash_Stat_MPC 64;
BA_ "FlexKomSigStartPos" SG_ 2432617087 DTC_MIL_Flash_Stat_MPC 7;
BA_ "FlexKomSID" SG_ 2432617087 DTC_MIL_Flash_Stat_MPC 100676537;
BA_ "GenSigStartValue" SG_ 2432617087 DTC_MIL_Flash_Stat_MPC 3;
BA_ "FlexKomSigStartValue" SG_ 2432617087 DTC_MIL_Flash_Stat_MPC "FFFFFFFFFF7FFFFFh";
BA_ "GenSigSendType" SG_ 2432617087 DTC_MIL_Flash_Stat_MPC 1;
BA_ "GenSigSNA" SG_ 2432617087 DTC_Stat_MPC "FFFFFFh";
BA_ "FlexKomIsMotorola" SG_ 2432617087 DTC_Stat_MPC 1;
BA_ "FlexKomComment" SG_ 2432617087 DTC_Stat_MPC "Diagnostic Message DM1";
BA_ "FlexKomSigName" SG_ 2432617087 DTC_Stat_MPC "DM1_Pkt_MPC";
BA_ "FlexKomSigLaenge" SG_ 2432617087 DTC_Stat_MPC 64;
BA_ "FlexKomSigStartPos" SG_ 2432617087 DTC_Stat_MPC 7;
BA_ "FlexKomSID" SG_ 2432617087 DTC_Stat_MPC 100676537;
BA_ "GenSigStartValue" SG_ 2432617087 DTC_Stat_MPC 16777215;
BA_ "FlexKomSigStartValue" SG_ 2432617087 DTC_Stat_MPC "FFFFFFFFFF7FFFFFh";
BA_ "GenSigSendType" SG_ 2432617087 DTC_Stat_MPC 1;
BA_ "GenSigSNA" SG_ 2432617087 DTC_OccCnt_MPC "7Fh";
BA_ "FlexKomIsMotorola" SG_ 2432617087 DTC_OccCnt_MPC 1;
BA_ "FlexKomComment" SG_ 2432617087 DTC_OccCnt_MPC "Diagnostic Message DM1";
BA_ "FlexKomSigName" SG_ 2432617087 DTC_OccCnt_MPC "DM1_Pkt_MPC";
BA_ "FlexKomSigLaenge" SG_ 2432617087 DTC_OccCnt_MPC 64;
BA_ "FlexKomSigStartPos" SG_ 2432617087 DTC_OccCnt_MPC 7;
BA_ "FlexKomSID" SG_ 2432617087 DTC_OccCnt_MPC 100676537;
BA_ "GenSigStartValue" SG_ 2432617087 DTC_OccCnt_MPC 127;
BA_ "FlexKomSigStartValue" SG_ 2432617087 DTC_OccCnt_MPC "FFFFFFFFFF7FFFFFh";
BA_ "GenSigSendType" SG_ 2432617087 DTC_OccCnt_MPC 1;
BA_ "GenSigSNA" SG_ 2432617087 DTC_SPN_ConvMd_MPC "0h";
BA_ "FlexKomIsMotorola" SG_ 2432617087 DTC_SPN_ConvMd_MPC 1;
BA_ "FlexKomComment" SG_ 2432617087 DTC_SPN_ConvMd_MPC "Diagnostic Message DM1";
BA_ "FlexKomSigName" SG_ 2432617087 DTC_SPN_ConvMd_MPC "DM1_Pkt_MPC";
BA_ "FlexKomSigLaenge" SG_ 2432617087 DTC_SPN_ConvMd_MPC 64;
BA_ "FlexKomSigStartPos" SG_ 2432617087 DTC_SPN_ConvMd_MPC 7;
BA_ "FlexKomSID" SG_ 2432617087 DTC_SPN_ConvMd_MPC 100676537;
BA_ "FlexKomSigStartValue" SG_ 2432617087 DTC_SPN_ConvMd_MPC "FFFFFFFFFF7FFFFFh";
BA_ "GenSigSendType" SG_ 2432617087 DTC_SPN_ConvMd_MPC 1;
BA_ "GenSigSNA" SG_ 2432630817 IgnSw_Stat_SCA "Fh";
BA_ "FlexKomIsMotorola" SG_ 2432630817 IgnSw_Stat_SCA 1;
BA_ "FlexKomComment" SG_ 2432630817 IgnSw_Stat_SCA "Ignition Switch from SCA";
BA_ "FlexKomSigName" SG_ 2432630817 IgnSw_Stat_SCA "IgnSw_SCA";
BA_ "FlexKomSigLaenge" SG_ 2432630817 IgnSw_Stat_SCA 4;
BA_ "FlexKomSigStartPos" SG_ 2432630817 IgnSw_Stat_SCA 3;
BA_ "FlexKomSID" SG_ 2432630817 IgnSw_Stat_SCA 100663350;
BA_ "GenSigTimeout_MPC2" SG_ 2432630817 IgnSw_Stat_SCA 525;
BA_ "GenSigStartValue" SG_ 2432630817 IgnSw_Stat_SCA 15;
BA_ "FlexKomSigStartValue" SG_ 2432630817 IgnSw_Stat_SCA "0Fh";
BA_ "GenSigCycleTime" SG_ 2432630817 IgnSw_Stat_SCA 50;
BA_ "GenSigSNA" SG_ 2432630817 SysVolt_Stat "3h";
BA_ "FlexKomIsMotorola" SG_ 2432630817 SysVolt_Stat 1;
BA_ "FlexKomComment" SG_ 2432630817 SysVolt_Stat "System Voltage Current state";
BA_ "FlexKomSigName" SG_ 2432630817 SysVolt_Stat "SysVolt";
BA_ "FlexKomSigLaenge" SG_ 2432630817 SysVolt_Stat 2;
BA_ "FlexKomSigStartPos" SG_ 2432630817 SysVolt_Stat 5;
BA_ "FlexKomSID" SG_ 2432630817 SysVolt_Stat 100664027;
BA_ "GenSigTimeout_MPC2" SG_ 2432630817 SysVolt_Stat 525;
BA_ "GenSigStartValue" SG_ 2432630817 SysVolt_Stat 3;
BA_ "FlexKomSigStartValue" SG_ 2432630817 SysVolt_Stat "03h";
BA_ "GenSigCycleTime" SG_ 2432630817 SysVolt_Stat 50;
BA_ "GenSigSNA" SG_ 2432630817 EngCrk_Stat "3h";
BA_ "FlexKomIsMotorola" SG_ 2432630817 EngCrk_Stat 1;
BA_ "FlexKomComment" SG_ 2432630817 EngCrk_Stat "Engine Cranking";
BA_ "FlexKomSigName" SG_ 2432630817 EngCrk_Stat "EngCrk";
BA_ "FlexKomSigLaenge" SG_ 2432630817 EngCrk_Stat 2;
BA_ "FlexKomSigStartPos" SG_ 2432630817 EngCrk_Stat 7;
BA_ "FlexKomSID" SG_ 2432630817 EngCrk_Stat 100664309;
BA_ "GenSigTimeout_MPC2" SG_ 2432630817 EngCrk_Stat 525;
BA_ "GenSigStartValue" SG_ 2432630817 EngCrk_Stat 3;
BA_ "FlexKomSigStartValue" SG_ 2432630817 EngCrk_Stat "03h";
BA_ "GenSigCycleTime" SG_ 2432630817 EngCrk_Stat 50;
BA_ "GenSigSNA" SG_ 2432630817 HiBm_Cmd "3h";
BA_ "FlexKomIsMotorola" SG_ 2432630817 HiBm_Cmd 1;
BA_ "FlexKomComment" SG_ 2432630817 HiBm_Cmd "High beam Command";
BA_ "FlexKomSigName" SG_ 2432630817 HiBm_Cmd "HiBm";
BA_ "FlexKomSigLaenge" SG_ 2432630817 HiBm_Cmd 2;
BA_ "FlexKomSigStartPos" SG_ 2432630817 HiBm_Cmd 11;
BA_ "FlexKomSID" SG_ 2432630817 HiBm_Cmd 100663372;
BA_ "GenSigTimeout_MPC2" SG_ 2432630817 HiBm_Cmd 525;
BA_ "GenSigStartValue" SG_ 2432630817 HiBm_Cmd 3;
BA_ "FlexKomSigStartValue" SG_ 2432630817 HiBm_Cmd "03h";
BA_ "GenSigCycleTime" SG_ 2432630817 HiBm_Cmd 50;
BA_ "GenSigSNA" SG_ 2432630911 Rsrv_CRC_SG_MPC_C01_Pkt "0h";
BA_ "FlexKomIsMotorola" SG_ 2432630911 Rsrv_CRC_SG_MPC_C01_Pkt 1;
BA_ "FlexKomComment" SG_ 2432630911 Rsrv_CRC_SG_MPC_C01_Pkt "Multi Purpose Camera Paket 1";
BA_ "FlexKomSigName" SG_ 2432630911 Rsrv_CRC_SG_MPC_C01_Pkt "MPC_C01_Pkt";
BA_ "FlexKomSigLaenge" SG_ 2432630911 Rsrv_CRC_SG_MPC_C01_Pkt 64;
BA_ "FlexKomSigStartPos" SG_ 2432630911 Rsrv_CRC_SG_MPC_C01_Pkt 7;
BA_ "FlexKomSID" SG_ 2432630911 Rsrv_CRC_SG_MPC_C01_Pkt 100677003;
BA_ "FlexKomSigStartValue" SG_ 2432630911 Rsrv_CRC_SG_MPC_C01_Pkt "00F0FFFFFFFFFFFFh";
BA_ "GenSigCycleTime" SG_ 2432630911 Rsrv_CRC_SG_MPC_C01_Pkt 50;
BA_ "GenSigSNA" SG_ 2432630911 Rsrv_SQC_SG_MPC_C01_Pkt "0h";
BA_ "FlexKomIsMotorola" SG_ 2432630911 Rsrv_SQC_SG_MPC_C01_Pkt 1;
BA_ "FlexKomComment" SG_ 2432630911 Rsrv_SQC_SG_MPC_C01_Pkt "Multi Purpose Camera Paket 1";
BA_ "FlexKomSigName" SG_ 2432630911 Rsrv_SQC_SG_MPC_C01_Pkt "MPC_C01_Pkt";
BA_ "FlexKomSigLaenge" SG_ 2432630911 Rsrv_SQC_SG_MPC_C01_Pkt 64;
BA_ "FlexKomSigStartPos" SG_ 2432630911 Rsrv_SQC_SG_MPC_C01_Pkt 7;
BA_ "FlexKomSID" SG_ 2432630911 Rsrv_SQC_SG_MPC_C01_Pkt 100677003;
BA_ "FlexKomSigStartValue" SG_ 2432630911 Rsrv_SQC_SG_MPC_C01_Pkt "00F0FFFFFFFFFFFFh";
BA_ "GenSigCycleTime" SG_ 2432630911 Rsrv_SQC_SG_MPC_C01_Pkt 50;
BA_ "GenSigSNA" SG_ 2432630911 LaneDptFuncActv_Stat_MPC "Fh";
BA_ "FlexKomIsMotorola" SG_ 2432630911 LaneDptFuncActv_Stat_MPC 1;
BA_ "FlexKomComment" SG_ 2432630911 LaneDptFuncActv_Stat_MPC "Multi Purpose Camera Paket 1";
BA_ "FlexKomSigName" SG_ 2432630911 LaneDptFuncActv_Stat_MPC "MPC_C01_Pkt";
BA_ "FlexKomSigLaenge" SG_ 2432630911 LaneDptFuncActv_Stat_MPC 64;
BA_ "FlexKomSigStartPos" SG_ 2432630911 LaneDptFuncActv_Stat_MPC 7;
BA_ "FlexKomSID" SG_ 2432630911 LaneDptFuncActv_Stat_MPC 100677003;
BA_ "GenSigStartValue" SG_ 2432630911 LaneDptFuncActv_Stat_MPC 15;
BA_ "FlexKomSigStartValue" SG_ 2432630911 LaneDptFuncActv_Stat_MPC "00F0FFFFFFFFFFFFh";
BA_ "GenSigCycleTime" SG_ 2432630911 LaneDptFuncActv_Stat_MPC 50;
BA_ "GenSigSNA" SG_ 2432630911 LaneDptImntLt_Rq_MPC "3h";
BA_ "FlexKomIsMotorola" SG_ 2432630911 LaneDptImntLt_Rq_MPC 1;
BA_ "FlexKomComment" SG_ 2432630911 LaneDptImntLt_Rq_MPC "Multi Purpose Camera Paket 1";
BA_ "FlexKomSigName" SG_ 2432630911 LaneDptImntLt_Rq_MPC "MPC_C01_Pkt";
BA_ "FlexKomSigLaenge" SG_ 2432630911 LaneDptImntLt_Rq_MPC 64;
BA_ "FlexKomSigStartPos" SG_ 2432630911 LaneDptImntLt_Rq_MPC 7;
BA_ "FlexKomSID" SG_ 2432630911 LaneDptImntLt_Rq_MPC 100677003;
BA_ "GenSigStartValue" SG_ 2432630911 LaneDptImntLt_Rq_MPC 3;
BA_ "FlexKomSigStartValue" SG_ 2432630911 LaneDptImntLt_Rq_MPC "00F0FFFFFFFFFFFFh";
BA_ "GenSigCycleTime" SG_ 2432630911 LaneDptImntLt_Rq_MPC 50;
BA_ "GenSigSNA" SG_ 2432630911 LaneDptImntRt_Rq_MPC "3h";
BA_ "FlexKomIsMotorola" SG_ 2432630911 LaneDptImntRt_Rq_MPC 1;
BA_ "FlexKomComment" SG_ 2432630911 LaneDptImntRt_Rq_MPC "Multi Purpose Camera Paket 1";
BA_ "FlexKomSigName" SG_ 2432630911 LaneDptImntRt_Rq_MPC "MPC_C01_Pkt";
BA_ "FlexKomSigLaenge" SG_ 2432630911 LaneDptImntRt_Rq_MPC 64;
BA_ "FlexKomSigStartPos" SG_ 2432630911 LaneDptImntRt_Rq_MPC 7;
BA_ "FlexKomSID" SG_ 2432630911 LaneDptImntRt_Rq_MPC 100677003;
BA_ "GenSigStartValue" SG_ 2432630911 LaneDptImntRt_Rq_MPC 3;
BA_ "FlexKomSigStartValue" SG_ 2432630911 LaneDptImntRt_Rq_MPC "00F0FFFFFFFFFFFFh";
BA_ "GenSigCycleTime" SG_ 2432630911 LaneDptImntRt_Rq_MPC 50;
BA_ "GenSigSNA" SG_ 2432630911 LaneDptWarnLt_Rq_MPC "3h";
BA_ "FlexKomIsMotorola" SG_ 2432630911 LaneDptWarnLt_Rq_MPC 1;
BA_ "FlexKomComment" SG_ 2432630911 LaneDptWarnLt_Rq_MPC "Multi Purpose Camera Paket 1";
BA_ "FlexKomSigName" SG_ 2432630911 LaneDptWarnLt_Rq_MPC "MPC_C01_Pkt";
BA_ "FlexKomSigLaenge" SG_ 2432630911 LaneDptWarnLt_Rq_MPC 64;
BA_ "FlexKomSigStartPos" SG_ 2432630911 LaneDptWarnLt_Rq_MPC 7;
BA_ "FlexKomSID" SG_ 2432630911 LaneDptWarnLt_Rq_MPC 100677003;
BA_ "GenSigStartValue" SG_ 2432630911 LaneDptWarnLt_Rq_MPC 3;
BA_ "FlexKomSigStartValue" SG_ 2432630911 LaneDptWarnLt_Rq_MPC "00F0FFFFFFFFFFFFh";
BA_ "GenSigCycleTime" SG_ 2432630911 LaneDptWarnLt_Rq_MPC 50;
BA_ "GenSigSNA" SG_ 2432630911 LaneDptWarnRt_Rq_MPC "3h";
BA_ "FlexKomIsMotorola" SG_ 2432630911 LaneDptWarnRt_Rq_MPC 1;
BA_ "FlexKomComment" SG_ 2432630911 LaneDptWarnRt_Rq_MPC "Multi Purpose Camera Paket 1";
BA_ "FlexKomSigName" SG_ 2432630911 LaneDptWarnRt_Rq_MPC "MPC_C01_Pkt";
BA_ "FlexKomSigLaenge" SG_ 2432630911 LaneDptWarnRt_Rq_MPC 64;
BA_ "FlexKomSigStartPos" SG_ 2432630911 LaneDptWarnRt_Rq_MPC 7;
BA_ "FlexKomSID" SG_ 2432630911 LaneDptWarnRt_Rq_MPC 100677003;
BA_ "GenSigStartValue" SG_ 2432630911 LaneDptWarnRt_Rq_MPC 3;
BA_ "FlexKomSigStartValue" SG_ 2432630911 LaneDptWarnRt_Rq_MPC "00F0FFFFFFFFFFFFh";
BA_ "GenSigCycleTime" SG_ 2432630911 LaneDptWarnRt_Rq_MPC 50;
BA_ "GenSigSNA" SG_ 2432630911 LaneDptD_Actv_Stat_MPC "3h";
BA_ "FlexKomIsMotorola" SG_ 2432630911 LaneDptD_Actv_Stat_MPC 1;
BA_ "FlexKomComment" SG_ 2432630911 LaneDptD_Actv_Stat_MPC "Multi Purpose Camera Paket 1";
BA_ "FlexKomSigName" SG_ 2432630911 LaneDptD_Actv_Stat_MPC "MPC_C01_Pkt";
BA_ "FlexKomSigLaenge" SG_ 2432630911 LaneDptD_Actv_Stat_MPC 64;
BA_ "FlexKomSigStartPos" SG_ 2432630911 LaneDptD_Actv_Stat_MPC 7;
BA_ "FlexKomSID" SG_ 2432630911 LaneDptD_Actv_Stat_MPC 100677003;
BA_ "GenSigStartValue" SG_ 2432630911 LaneDptD_Actv_Stat_MPC 3;
BA_ "FlexKomSigStartValue" SG_ 2432630911 LaneDptD_Actv_Stat_MPC "00F0FFFFFFFFFFFFh";
BA_ "GenSigCycleTime" SG_ 2432630911 LaneDptD_Actv_Stat_MPC 50;
BA_ "GenSigSNA" SG_ 2432630911 SwLED_LDW_Rq_MPC "3h";
BA_ "FlexKomIsMotorola" SG_ 2432630911 SwLED_LDW_Rq_MPC 1;
BA_ "FlexKomComment" SG_ 2432630911 SwLED_LDW_Rq_MPC "Multi Purpose Camera Paket 1";
BA_ "FlexKomSigName" SG_ 2432630911 SwLED_LDW_Rq_MPC "MPC_C01_Pkt";
BA_ "FlexKomSigLaenge" SG_ 2432630911 SwLED_LDW_Rq_MPC 64;
BA_ "FlexKomSigStartPos" SG_ 2432630911 SwLED_LDW_Rq_MPC 7;
BA_ "FlexKomSID" SG_ 2432630911 SwLED_LDW_Rq_MPC 100677003;
BA_ "GenSigStartValue" SG_ 2432630911 SwLED_LDW_Rq_MPC 3;
BA_ "FlexKomSigStartValue" SG_ 2432630911 SwLED_LDW_Rq_MPC "00F0FFFFFFFFFFFFh";
BA_ "GenSigCycleTime" SG_ 2432630911 SwLED_LDW_Rq_MPC 50;
BA_ "GenSigSNA" SG_ 2432630911 TypeLaneMarkLt_Stat_MPC "3h";
BA_ "FlexKomIsMotorola" SG_ 2432630911 TypeLaneMarkLt_Stat_MPC 1;
BA_ "FlexKomComment" SG_ 2432630911 TypeLaneMarkLt_Stat_MPC "Multi Purpose Camera Paket 1";
BA_ "FlexKomSigName" SG_ 2432630911 TypeLaneMarkLt_Stat_MPC "MPC_C01_Pkt";
BA_ "FlexKomSigLaenge" SG_ 2432630911 TypeLaneMarkLt_Stat_MPC 64;
BA_ "FlexKomSigStartPos" SG_ 2432630911 TypeLaneMarkLt_Stat_MPC 7;
BA_ "FlexKomSID" SG_ 2432630911 TypeLaneMarkLt_Stat_MPC 100677003;
BA_ "GenSigStartValue" SG_ 2432630911 TypeLaneMarkLt_Stat_MPC 3;
BA_ "FlexKomSigStartValue" SG_ 2432630911 TypeLaneMarkLt_Stat_MPC "00F0FFFFFFFFFFFFh";
BA_ "GenSigCycleTime" SG_ 2432630911 TypeLaneMarkLt_Stat_MPC 50;
BA_ "GenSigSNA" SG_ 2432630911 TypeLaneMarkRt_Stat_MPC "3h";
BA_ "FlexKomIsMotorola" SG_ 2432630911 TypeLaneMarkRt_Stat_MPC 1;
BA_ "FlexKomComment" SG_ 2432630911 TypeLaneMarkRt_Stat_MPC "Multi Purpose Camera Paket 1";
BA_ "FlexKomSigName" SG_ 2432630911 TypeLaneMarkRt_Stat_MPC "MPC_C01_Pkt";
BA_ "FlexKomSigLaenge" SG_ 2432630911 TypeLaneMarkRt_Stat_MPC 64;
BA_ "FlexKomSigStartPos" SG_ 2432630911 TypeLaneMarkRt_Stat_MPC 7;
BA_ "FlexKomSID" SG_ 2432630911 TypeLaneMarkRt_Stat_MPC 100677003;
BA_ "GenSigStartValue" SG_ 2432630911 TypeLaneMarkRt_Stat_MPC 3;
BA_ "FlexKomSigStartValue" SG_ 2432630911 TypeLaneMarkRt_Stat_MPC "00F0FFFFFFFFFFFFh";
BA_ "GenSigCycleTime" SG_ 2432630911 TypeLaneMarkRt_Stat_MPC 50;
BA_ "GenSigSNA" SG_ 2432630911 ActlLgtDist_Cval "FFh";
BA_ "FlexKomIsMotorola" SG_ 2432630911 ActlLgtDist_Cval 1;
BA_ "FlexKomComment" SG_ 2432630911 ActlLgtDist_Cval "Multi Purpose Camera Paket 1";
BA_ "FlexKomSigName" SG_ 2432630911 ActlLgtDist_Cval "MPC_C01_Pkt";
BA_ "FlexKomSigLaenge" SG_ 2432630911 ActlLgtDist_Cval 64;
BA_ "FlexKomSigStartPos" SG_ 2432630911 ActlLgtDist_Cval 7;
BA_ "FlexKomSID" SG_ 2432630911 ActlLgtDist_Cval 100677003;
BA_ "GenSigStartValue" SG_ 2432630911 ActlLgtDist_Cval 255;
BA_ "FlexKomSigStartValue" SG_ 2432630911 ActlLgtDist_Cval "00F0FFFFFFFFFFFFh";
BA_ "GenSigCycleTime" SG_ 2432630911 ActlLgtDist_Cval 50;
BA_ "GenSigSNA" SG_ 2432630911 HL_ChgOvrLvl_Cval "Fh";
BA_ "FlexKomIsMotorola" SG_ 2432630911 HL_ChgOvrLvl_Cval 1;
BA_ "FlexKomComment" SG_ 2432630911 HL_ChgOvrLvl_Cval "Multi Purpose Camera Paket 1";
BA_ "FlexKomSigName" SG_ 2432630911 HL_ChgOvrLvl_Cval "MPC_C01_Pkt";
BA_ "FlexKomSigLaenge" SG_ 2432630911 HL_ChgOvrLvl_Cval 64;
BA_ "FlexKomSigStartPos" SG_ 2432630911 HL_ChgOvrLvl_Cval 7;
BA_ "FlexKomSID" SG_ 2432630911 HL_ChgOvrLvl_Cval 100677003;
BA_ "GenSigStartValue" SG_ 2432630911 HL_ChgOvrLvl_Cval 15;
BA_ "FlexKomSigStartValue" SG_ 2432630911 HL_ChgOvrLvl_Cval "00F0FFFFFFFFFFFFh";
BA_ "GenSigCycleTime" SG_ 2432630911 HL_ChgOvrLvl_Cval 50;
BA_ "GenSigSNA" SG_ 2432630911 IHC_Func_Stat_MPC "Fh";
BA_ "FlexKomIsMotorola" SG_ 2432630911 IHC_Func_Stat_MPC 1;
BA_ "FlexKomComment" SG_ 2432630911 IHC_Func_Stat_MPC "Multi Purpose Camera Paket 1";
BA_ "FlexKomSigName" SG_ 2432630911 IHC_Func_Stat_MPC "MPC_C01_Pkt";
BA_ "FlexKomSigLaenge" SG_ 2432630911 IHC_Func_Stat_MPC 64;
BA_ "FlexKomSigStartPos" SG_ 2432630911 IHC_Func_Stat_MPC 7;
BA_ "FlexKomSID" SG_ 2432630911 IHC_Func_Stat_MPC 100677003;
BA_ "GenSigStartValue" SG_ 2432630911 IHC_Func_Stat_MPC 15;
BA_ "FlexKomSigStartValue" SG_ 2432630911 IHC_Func_Stat_MPC "00F0FFFFFFFFFFFFh";
BA_ "GenSigCycleTime" SG_ 2432630911 IHC_Func_Stat_MPC 50;
BA_ "GenSigSNA" SG_ 2432630911 HiBm_Rq_MPC "3h";
BA_ "FlexKomIsMotorola" SG_ 2432630911 HiBm_Rq_MPC 1;
BA_ "FlexKomComment" SG_ 2432630911 HiBm_Rq_MPC "Multi Purpose Camera Paket 1";
BA_ "FlexKomSigName" SG_ 2432630911 HiBm_Rq_MPC "MPC_C01_Pkt";
BA_ "FlexKomSigLaenge" SG_ 2432630911 HiBm_Rq_MPC 64;
BA_ "FlexKomSigStartPos" SG_ 2432630911 HiBm_Rq_MPC 7;
BA_ "FlexKomSID" SG_ 2432630911 HiBm_Rq_MPC 100677003;
BA_ "GenSigStartValue" SG_ 2432630911 HiBm_Rq_MPC 3;
BA_ "FlexKomSigStartValue" SG_ 2432630911 HiBm_Rq_MPC "00F0FFFFFFFFFFFFh";
BA_ "GenSigCycleTime" SG_ 2432630911 HiBm_Rq_MPC 50;
BA_ "GenSigSNA" SG_ 2432630911 DayNightMd_Stat_MPC "3h";
BA_ "FlexKomIsMotorola" SG_ 2432630911 DayNightMd_Stat_MPC 1;
BA_ "FlexKomComment" SG_ 2432630911 DayNightMd_Stat_MPC "Multi Purpose Camera Paket 1";
BA_ "FlexKomSigName" SG_ 2432630911 DayNightMd_Stat_MPC "MPC_C01_Pkt";
BA_ "FlexKomSigLaenge" SG_ 2432630911 DayNightMd_Stat_MPC 64;
BA_ "FlexKomSigStartPos" SG_ 2432630911 DayNightMd_Stat_MPC 7;
BA_ "FlexKomSID" SG_ 2432630911 DayNightMd_Stat_MPC 100677003;
BA_ "GenSigStartValue" SG_ 2432630911 DayNightMd_Stat_MPC 3;
BA_ "FlexKomSigStartValue" SG_ 2432630911 DayNightMd_Stat_MPC "00F0FFFFFFFFFFFFh";
BA_ "GenSigCycleTime" SG_ 2432630911 DayNightMd_Stat_MPC 50;
BA_ "GenSigSNA" SG_ 2432630911 LimSight_Stat_MPC "3h";
BA_ "FlexKomIsMotorola" SG_ 2432630911 LimSight_Stat_MPC 1;
BA_ "FlexKomComment" SG_ 2432630911 LimSight_Stat_MPC "Multi Purpose Camera Paket 1";
BA_ "FlexKomSigName" SG_ 2432630911 LimSight_Stat_MPC "MPC_C01_Pkt";
BA_ "FlexKomSigLaenge" SG_ 2432630911 LimSight_Stat_MPC 64;
BA_ "FlexKomSigStartPos" SG_ 2432630911 LimSight_Stat_MPC 7;
BA_ "FlexKomSID" SG_ 2432630911 LimSight_Stat_MPC 100677003;
BA_ "GenSigStartValue" SG_ 2432630911 LimSight_Stat_MPC 3;
BA_ "FlexKomSigStartValue" SG_ 2432630911 LimSight_Stat_MPC "00F0FFFFFFFFFFFFh";
BA_ "GenSigCycleTime" SG_ 2432630911 LimSight_Stat_MPC 50;
BA_ "GenSigSNA" SG_ 2432630911 LaneMarkRecLt_Stat "3h";
BA_ "FlexKomIsMotorola" SG_ 2432630911 LaneMarkRecLt_Stat 1;
BA_ "FlexKomComment" SG_ 2432630911 LaneMarkRecLt_Stat "Multi Purpose Camera Paket 1";
BA_ "FlexKomSigName" SG_ 2432630911 LaneMarkRecLt_Stat "MPC_C01_Pkt";
BA_ "FlexKomSigLaenge" SG_ 2432630911 LaneMarkRecLt_Stat 64;
BA_ "FlexKomSigStartPos" SG_ 2432630911 LaneMarkRecLt_Stat 7;
BA_ "FlexKomSID" SG_ 2432630911 LaneMarkRecLt_Stat 100677003;
BA_ "GenSigStartValue" SG_ 2432630911 LaneMarkRecLt_Stat 3;
BA_ "FlexKomSigStartValue" SG_ 2432630911 LaneMarkRecLt_Stat "00F0FFFFFFFFFFFFh";
BA_ "GenSigCycleTime" SG_ 2432630911 LaneMarkRecLt_Stat 50;
BA_ "GenSigSNA" SG_ 2432630911 LaneMarkRecRt_Stat "3h";
BA_ "FlexKomIsMotorola" SG_ 2432630911 LaneMarkRecRt_Stat 1;
BA_ "FlexKomComment" SG_ 2432630911 LaneMarkRecRt_Stat "Multi Purpose Camera Paket 1";
BA_ "FlexKomSigName" SG_ 2432630911 LaneMarkRecRt_Stat "MPC_C01_Pkt";
BA_ "FlexKomSigLaenge" SG_ 2432630911 LaneMarkRecRt_Stat 64;
BA_ "FlexKomSigStartPos" SG_ 2432630911 LaneMarkRecRt_Stat 7;
BA_ "FlexKomSID" SG_ 2432630911 LaneMarkRecRt_Stat 100677003;
BA_ "GenSigStartValue" SG_ 2432630911 LaneMarkRecRt_Stat 3;
BA_ "FlexKomSigStartValue" SG_ 2432630911 LaneMarkRecRt_Stat "00F0FFFFFFFFFFFFh";
BA_ "GenSigCycleTime" SG_ 2432630911 LaneMarkRecRt_Stat 50;
BA_ "GenSigSNA" SG_ 2432630911 LaneMarkColLt_Cval_MPC "7h";
BA_ "FlexKomIsMotorola" SG_ 2432630911 LaneMarkColLt_Cval_MPC 1;
BA_ "FlexKomComment" SG_ 2432630911 LaneMarkColLt_Cval_MPC "Multi Purpose Camera Paket 1";
BA_ "FlexKomSigName" SG_ 2432630911 LaneMarkColLt_Cval_MPC "MPC_C01_Pkt";
BA_ "FlexKomSigLaenge" SG_ 2432630911 LaneMarkColLt_Cval_MPC 64;
BA_ "FlexKomSigStartPos" SG_ 2432630911 LaneMarkColLt_Cval_MPC 7;
BA_ "FlexKomSID" SG_ 2432630911 LaneMarkColLt_Cval_MPC 100677003;
BA_ "GenSigStartValue" SG_ 2432630911 LaneMarkColLt_Cval_MPC 7;
BA_ "FlexKomSigStartValue" SG_ 2432630911 LaneMarkColLt_Cval_MPC "00F0FFFFFFFFFFFFh";
BA_ "GenSigCycleTime" SG_ 2432630911 LaneMarkColLt_Cval_MPC 50;
BA_ "GenSigSNA" SG_ 2432630911 LaneMarkColRt_Cval_MPC "7h";
BA_ "FlexKomIsMotorola" SG_ 2432630911 LaneMarkColRt_Cval_MPC 1;
BA_ "FlexKomComment" SG_ 2432630911 LaneMarkColRt_Cval_MPC "Multi Purpose Camera Paket 1";
BA_ "FlexKomSigName" SG_ 2432630911 LaneMarkColRt_Cval_MPC "MPC_C01_Pkt";
BA_ "FlexKomSigLaenge" SG_ 2432630911 LaneMarkColRt_Cval_MPC 64;
BA_ "FlexKomSigStartPos" SG_ 2432630911 LaneMarkColRt_Cval_MPC 7;
BA_ "FlexKomSID" SG_ 2432630911 LaneMarkColRt_Cval_MPC 100677003;
BA_ "GenSigStartValue" SG_ 2432630911 LaneMarkColRt_Cval_MPC 7;
BA_ "FlexKomSigStartValue" SG_ 2432630911 LaneMarkColRt_Cval_MPC "00F0FFFFFFFFFFFFh";
BA_ "GenSigCycleTime" SG_ 2432630911 LaneMarkColRt_Cval_MPC 50;
BA_ "GenSigSNA" SG_ 2432631051 CRC_SG_BS_E7_Pkt "0h";
BA_ "FlexKomIsMotorola" SG_ 2432631051 CRC_SG_BS_E7_Pkt 1;
BA_ "FlexKomComment" SG_ 2432631051 CRC_SG_BS_E7_Pkt "BS_E7_Pkt";
BA_ "FlexKomSigName" SG_ 2432631051 CRC_SG_BS_E7_Pkt "BS_E7_Pkt";
BA_ "FlexKomSigLaenge" SG_ 2432631051 CRC_SG_BS_E7_Pkt 64;
BA_ "FlexKomSigStartPos" SG_ 2432631051 CRC_SG_BS_E7_Pkt 7;
BA_ "FlexKomSID" SG_ 2432631051 CRC_SG_BS_E7_Pkt 100677020;
BA_ "GenSigTimeout_MPC2" SG_ 2432631051 CRC_SG_BS_E7_Pkt 275;
BA_ "FlexKomSigStartValue" SG_ 2432631051 CRC_SG_BS_E7_Pkt "00F0FFFFFFFFFFFFh";
BA_ "GenSigCycleTime" SG_ 2432631051 CRC_SG_BS_E7_Pkt 50;
BA_ "GenSigSNA" SG_ 2432631051 SQC_SG_BS_E7_Pkt "0h";
BA_ "FlexKomIsMotorola" SG_ 2432631051 SQC_SG_BS_E7_Pkt 1;
BA_ "FlexKomComment" SG_ 2432631051 SQC_SG_BS_E7_Pkt "BS_E7_Pkt";
BA_ "FlexKomSigName" SG_ 2432631051 SQC_SG_BS_E7_Pkt "BS_E7_Pkt";
BA_ "FlexKomSigLaenge" SG_ 2432631051 SQC_SG_BS_E7_Pkt 64;
BA_ "FlexKomSigStartPos" SG_ 2432631051 SQC_SG_BS_E7_Pkt 7;
BA_ "FlexKomSID" SG_ 2432631051 SQC_SG_BS_E7_Pkt 100677020;
BA_ "GenSigTimeout_MPC2" SG_ 2432631051 SQC_SG_BS_E7_Pkt 275;
BA_ "FlexKomSigStartValue" SG_ 2432631051 SQC_SG_BS_E7_Pkt "00F0FFFFFFFFFFFFh";
BA_ "GenSigCycleTime" SG_ 2432631051 SQC_SG_BS_E7_Pkt 50;
BA_ "GenSigSNA" SG_ 2432631051 YawRateCorr_Cval_BS "FFFFh";
BA_ "FlexKomIsMotorola" SG_ 2432631051 YawRateCorr_Cval_BS 1;
BA_ "FlexKomComment" SG_ 2432631051 YawRateCorr_Cval_BS "BS_E7_Pkt";
BA_ "FlexKomSigName" SG_ 2432631051 YawRateCorr_Cval_BS "BS_E7_Pkt";
BA_ "FlexKomSigLaenge" SG_ 2432631051 YawRateCorr_Cval_BS 64;
BA_ "FlexKomSigStartPos" SG_ 2432631051 YawRateCorr_Cval_BS 7;
BA_ "FlexKomSID" SG_ 2432631051 YawRateCorr_Cval_BS 100677020;
BA_ "GenSigTimeout_MPC2" SG_ 2432631051 YawRateCorr_Cval_BS 275;
BA_ "GenSigStartValue" SG_ 2432631051 YawRateCorr_Cval_BS 65535;
BA_ "FlexKomSigStartValue" SG_ 2432631051 YawRateCorr_Cval_BS "00F0FFFFFFFFFFFFh";
BA_ "GenSigCycleTime" SG_ 2432631051 YawRateCorr_Cval_BS 50;
BA_ "GenSigSNA" SG_ 2432631051 YawRateCorrQual_Cval_BS "FFh";
BA_ "FlexKomIsMotorola" SG_ 2432631051 YawRateCorrQual_Cval_BS 1;
BA_ "FlexKomComment" SG_ 2432631051 YawRateCorrQual_Cval_BS "BS_E7_Pkt";
BA_ "FlexKomSigName" SG_ 2432631051 YawRateCorrQual_Cval_BS "BS_E7_Pkt";
BA_ "FlexKomSigLaenge" SG_ 2432631051 YawRateCorrQual_Cval_BS 64;
BA_ "FlexKomSigStartPos" SG_ 2432631051 YawRateCorrQual_Cval_BS 7;
BA_ "FlexKomSID" SG_ 2432631051 YawRateCorrQual_Cval_BS 100677020;
BA_ "GenSigTimeout_MPC2" SG_ 2432631051 YawRateCorrQual_Cval_BS 275;
BA_ "GenSigStartValue" SG_ 2432631051 YawRateCorrQual_Cval_BS 255;
BA_ "FlexKomSigStartValue" SG_ 2432631051 YawRateCorrQual_Cval_BS "00F0FFFFFFFFFFFFh";
BA_ "GenSigCycleTime" SG_ 2432631051 YawRateCorrQual_Cval_BS 50;
BA_ "GenSigSNA" SG_ 2432631167 CRC_SG_MPC_C03_Pkt "8Fh";
BA_ "FlexKomIsMotorola" SG_ 2432631167 CRC_SG_MPC_C03_Pkt 1;
BA_ "FlexKomComment" SG_ 2432631167 CRC_SG_MPC_C03_Pkt "MPC_C03_Pkt";
BA_ "FlexKomSigName" SG_ 2432631167 CRC_SG_MPC_C03_Pkt "MPC_C03_Pkt";
BA_ "FlexKomSigLaenge" SG_ 2432631167 CRC_SG_MPC_C03_Pkt 64;
BA_ "FlexKomSigStartPos" SG_ 2432631167 CRC_SG_MPC_C03_Pkt 7;
BA_ "FlexKomSID" SG_ 2432631167 CRC_SG_MPC_C03_Pkt 100677018;
BA_ "GenSigStartValue" SG_ 2432631167 CRC_SG_MPC_C03_Pkt 143;
BA_ "FlexKomSigStartValue" SG_ 2432631167 CRC_SG_MPC_C03_Pkt "8FF0FFFFFFFFFFFFh";
BA_ "GenSigCycleTime" SG_ 2432631167 CRC_SG_MPC_C03_Pkt 50;
BA_ "GenSigSNA" SG_ 2432631167 SQC_SG_MPC_C03_Pkt "0h";
BA_ "FlexKomIsMotorola" SG_ 2432631167 SQC_SG_MPC_C03_Pkt 1;
BA_ "FlexKomComment" SG_ 2432631167 SQC_SG_MPC_C03_Pkt "MPC_C03_Pkt";
BA_ "FlexKomSigName" SG_ 2432631167 SQC_SG_MPC_C03_Pkt "MPC_C03_Pkt";
BA_ "FlexKomSigLaenge" SG_ 2432631167 SQC_SG_MPC_C03_Pkt 64;
BA_ "FlexKomSigStartPos" SG_ 2432631167 SQC_SG_MPC_C03_Pkt 7;
BA_ "FlexKomSID" SG_ 2432631167 SQC_SG_MPC_C03_Pkt 100677018;
BA_ "FlexKomSigStartValue" SG_ 2432631167 SQC_SG_MPC_C03_Pkt "8FF0FFFFFFFFFFFFh";
BA_ "GenSigCycleTime" SG_ 2432631167 SQC_SG_MPC_C03_Pkt 50;
BA_ "GenSigSNA" SG_ 2432631167 TypeLaneMarkLtNotFltrd_Stat_MPC "3h";
BA_ "FlexKomIsMotorola" SG_ 2432631167 TypeLaneMarkLtNotFltrd_Stat_MPC 1;
BA_ "FlexKomComment" SG_ 2432631167 TypeLaneMarkLtNotFltrd_Stat_MPC "MPC_C03_Pkt";
BA_ "FlexKomSigName" SG_ 2432631167 TypeLaneMarkLtNotFltrd_Stat_MPC "MPC_C03_Pkt";
BA_ "FlexKomSigLaenge" SG_ 2432631167 TypeLaneMarkLtNotFltrd_Stat_MPC 64;
BA_ "FlexKomSigStartPos" SG_ 2432631167 TypeLaneMarkLtNotFltrd_Stat_MPC 7;
BA_ "FlexKomSID" SG_ 2432631167 TypeLaneMarkLtNotFltrd_Stat_MPC 100677018;
BA_ "GenSigStartValue" SG_ 2432631167 TypeLaneMarkLtNotFltrd_Stat_MPC 3;
BA_ "FlexKomSigStartValue" SG_ 2432631167 TypeLaneMarkLtNotFltrd_Stat_MPC "8FF0FFFFFFFFFFFFh";
BA_ "GenSigCycleTime" SG_ 2432631167 TypeLaneMarkLtNotFltrd_Stat_MPC 50;
BA_ "GenSigSNA" SG_ 2432631167 TypeLaneMarkRtNotFltrd_Stat_MPC "3h";
BA_ "FlexKomIsMotorola" SG_ 2432631167 TypeLaneMarkRtNotFltrd_Stat_MPC 1;
BA_ "FlexKomComment" SG_ 2432631167 TypeLaneMarkRtNotFltrd_Stat_MPC "MPC_C03_Pkt";
BA_ "FlexKomSigName" SG_ 2432631167 TypeLaneMarkRtNotFltrd_Stat_MPC "MPC_C03_Pkt";
BA_ "FlexKomSigLaenge" SG_ 2432631167 TypeLaneMarkRtNotFltrd_Stat_MPC 64;
BA_ "FlexKomSigStartPos" SG_ 2432631167 TypeLaneMarkRtNotFltrd_Stat_MPC 7;
BA_ "FlexKomSID" SG_ 2432631167 TypeLaneMarkRtNotFltrd_Stat_MPC 100677018;
BA_ "GenSigStartValue" SG_ 2432631167 TypeLaneMarkRtNotFltrd_Stat_MPC 3;
BA_ "FlexKomSigStartValue" SG_ 2432631167 TypeLaneMarkRtNotFltrd_Stat_MPC "8FF0FFFFFFFFFFFFh";
BA_ "GenSigCycleTime" SG_ 2432631167 TypeLaneMarkRtNotFltrd_Stat_MPC 50;
BA_ "GenSigSNA" SG_ 2432631167 WidthLaneLt_Cval_MPC "FFh";
BA_ "FlexKomIsMotorola" SG_ 2432631167 WidthLaneLt_Cval_MPC 1;
BA_ "FlexKomComment" SG_ 2432631167 WidthLaneLt_Cval_MPC "MPC_C03_Pkt";
BA_ "FlexKomSigName" SG_ 2432631167 WidthLaneLt_Cval_MPC "MPC_C03_Pkt";
BA_ "FlexKomSigLaenge" SG_ 2432631167 WidthLaneLt_Cval_MPC 64;
BA_ "FlexKomSigStartPos" SG_ 2432631167 WidthLaneLt_Cval_MPC 7;
BA_ "FlexKomSID" SG_ 2432631167 WidthLaneLt_Cval_MPC 100677018;
BA_ "GenSigStartValue" SG_ 2432631167 WidthLaneLt_Cval_MPC 255;
BA_ "FlexKomSigStartValue" SG_ 2432631167 WidthLaneLt_Cval_MPC "8FF0FFFFFFFFFFFFh";
BA_ "GenSigCycleTime" SG_ 2432631167 WidthLaneLt_Cval_MPC 50;
BA_ "GenSigSNA" SG_ 2432631167 WidthLaneRt_Cval_MPC "FFh";
BA_ "FlexKomIsMotorola" SG_ 2432631167 WidthLaneRt_Cval_MPC 1;
BA_ "FlexKomComment" SG_ 2432631167 WidthLaneRt_Cval_MPC "MPC_C03_Pkt";
BA_ "FlexKomSigName" SG_ 2432631167 WidthLaneRt_Cval_MPC "MPC_C03_Pkt";
BA_ "FlexKomSigLaenge" SG_ 2432631167 WidthLaneRt_Cval_MPC 64;
BA_ "FlexKomSigStartPos" SG_ 2432631167 WidthLaneRt_Cval_MPC 7;
BA_ "FlexKomSID" SG_ 2432631167 WidthLaneRt_Cval_MPC 100677018;
BA_ "GenSigStartValue" SG_ 2432631167 WidthLaneRt_Cval_MPC 255;
BA_ "FlexKomSigStartValue" SG_ 2432631167 WidthLaneRt_Cval_MPC "8FF0FFFFFFFFFFFFh";
BA_ "GenSigCycleTime" SG_ 2432631167 WidthLaneRt_Cval_MPC 50;
BA_ "GenSigSNA" SG_ 2432631167 DistLaneLineLt_Cval_MPC "FFFFh";
BA_ "FlexKomIsMotorola" SG_ 2432631167 DistLaneLineLt_Cval_MPC 1;
BA_ "FlexKomComment" SG_ 2432631167 DistLaneLineLt_Cval_MPC "MPC_C03_Pkt";
BA_ "FlexKomSigName" SG_ 2432631167 DistLaneLineLt_Cval_MPC "MPC_C03_Pkt";
BA_ "FlexKomSigLaenge" SG_ 2432631167 DistLaneLineLt_Cval_MPC 64;
BA_ "FlexKomSigStartPos" SG_ 2432631167 DistLaneLineLt_Cval_MPC 7;
BA_ "FlexKomSID" SG_ 2432631167 DistLaneLineLt_Cval_MPC 100677018;
BA_ "GenSigStartValue" SG_ 2432631167 DistLaneLineLt_Cval_MPC 65535;
BA_ "FlexKomSigStartValue" SG_ 2432631167 DistLaneLineLt_Cval_MPC "8FF0FFFFFFFFFFFFh";
BA_ "GenSigCycleTime" SG_ 2432631167 DistLaneLineLt_Cval_MPC 50;
BA_ "GenSigSNA" SG_ 2432631167 DistLaneLineRt_Cval_MPC "FFFFh";
BA_ "FlexKomIsMotorola" SG_ 2432631167 DistLaneLineRt_Cval_MPC 1;
BA_ "FlexKomComment" SG_ 2432631167 DistLaneLineRt_Cval_MPC "MPC_C03_Pkt";
BA_ "FlexKomSigName" SG_ 2432631167 DistLaneLineRt_Cval_MPC "MPC_C03_Pkt";
BA_ "FlexKomSigLaenge" SG_ 2432631167 DistLaneLineRt_Cval_MPC 64;
BA_ "FlexKomSigStartPos" SG_ 2432631167 DistLaneLineRt_Cval_MPC 7;
BA_ "FlexKomSID" SG_ 2432631167 DistLaneLineRt_Cval_MPC 100677018;
BA_ "GenSigStartValue" SG_ 2432631167 DistLaneLineRt_Cval_MPC 65535;
BA_ "FlexKomSigStartValue" SG_ 2432631167 DistLaneLineRt_Cval_MPC "8FF0FFFFFFFFFFFFh";
BA_ "GenSigCycleTime" SG_ 2432631167 DistLaneLineRt_Cval_MPC 50;
BA_ "GenSigSNA" SG_ 2432631270 BlockEquip_FOV_Stat "Fh";
BA_ "FlexKomIsMotorola" SG_ 2432631270 BlockEquip_FOV_Stat 1;
BA_ "FlexKomComment" SG_ 2432631270 BlockEquip_FOV_Stat "PSM E3 Packet";
BA_ "FlexKomSigName" SG_ 2432631270 BlockEquip_FOV_Stat "PSM_E3_Pkt";
BA_ "FlexKomSigLaenge" SG_ 2432631270 BlockEquip_FOV_Stat 64;
BA_ "FlexKomSigStartPos" SG_ 2432631270 BlockEquip_FOV_Stat 7;
BA_ "FlexKomSID" SG_ 2432631270 BlockEquip_FOV_Stat 100663880;
BA_ "GenSigTimeout_MPC2" SG_ 2432631270 BlockEquip_FOV_Stat 525;
BA_ "GenSigStartValue" SG_ 2432631270 BlockEquip_FOV_Stat 15;
BA_ "FlexKomSigStartValue" SG_ 2432631270 BlockEquip_FOV_Stat "FFFFFFFFFFFF0F00h";
BA_ "GenSigCycleTime" SG_ 2432631270 BlockEquip_FOV_Stat 50;
BA_ "GenSigSNA" SG_ 2432631270 MC_E3_Cval_PSM "0h";
BA_ "FlexKomIsMotorola" SG_ 2432631270 MC_E3_Cval_PSM 1;
BA_ "FlexKomComment" SG_ 2432631270 MC_E3_Cval_PSM "PSM E3 Packet";
BA_ "FlexKomSigName" SG_ 2432631270 MC_E3_Cval_PSM "PSM_E3_Pkt";
BA_ "FlexKomSigLaenge" SG_ 2432631270 MC_E3_Cval_PSM 64;
BA_ "FlexKomSigStartPos" SG_ 2432631270 MC_E3_Cval_PSM 7;
BA_ "FlexKomSID" SG_ 2432631270 MC_E3_Cval_PSM 100663880;
BA_ "GenSigTimeout_MPC2" SG_ 2432631270 MC_E3_Cval_PSM 525;
BA_ "FlexKomSigStartValue" SG_ 2432631270 MC_E3_Cval_PSM "FFFFFFFFFFFF0F00h";
BA_ "GenSigCycleTime" SG_ 2432631270 MC_E3_Cval_PSM 50;
BA_ "GenSigSNA" SG_ 2432631270 CRC_E3_Cval_PSM "0h";
BA_ "FlexKomIsMotorola" SG_ 2432631270 CRC_E3_Cval_PSM 1;
BA_ "FlexKomComment" SG_ 2432631270 CRC_E3_Cval_PSM "PSM E3 Packet";
BA_ "FlexKomSigName" SG_ 2432631270 CRC_E3_Cval_PSM "PSM_E3_Pkt";
BA_ "FlexKomSigLaenge" SG_ 2432631270 CRC_E3_Cval_PSM 64;
BA_ "FlexKomSigStartPos" SG_ 2432631270 CRC_E3_Cval_PSM 7;
BA_ "FlexKomSID" SG_ 2432631270 CRC_E3_Cval_PSM 100663880;
BA_ "GenSigTimeout_MPC2" SG_ 2432631270 CRC_E3_Cval_PSM 525;
BA_ "FlexKomSigStartValue" SG_ 2432631270 CRC_E3_Cval_PSM "FFFFFFFFFFFF0F00h";
BA_ "GenSigCycleTime" SG_ 2432631270 CRC_E3_Cval_PSM 50;
BA_ "GenSigSNA" SG_ 2432631423 CRC_SG_MPC_C04_Pkt "DFh";
BA_ "FlexKomIsMotorola" SG_ 2432631423 CRC_SG_MPC_C04_Pkt 1;
BA_ "FlexKomComment" SG_ 2432631423 CRC_SG_MPC_C04_Pkt "MPC_C04_Pkt";
BA_ "FlexKomSigName" SG_ 2432631423 CRC_SG_MPC_C04_Pkt "MPC_C04_Pkt";
BA_ "FlexKomSigLaenge" SG_ 2432631423 CRC_SG_MPC_C04_Pkt 64;
BA_ "FlexKomSigStartPos" SG_ 2432631423 CRC_SG_MPC_C04_Pkt 7;
BA_ "FlexKomSID" SG_ 2432631423 CRC_SG_MPC_C04_Pkt 100677019;
BA_ "GenSigStartValue" SG_ 2432631423 CRC_SG_MPC_C04_Pkt 223;
BA_ "FlexKomSigStartValue" SG_ 2432631423 CRC_SG_MPC_C04_Pkt "DFF0FFFFFFFFFFFFh";
BA_ "GenSigCycleTime" SG_ 2432631423 CRC_SG_MPC_C04_Pkt 50;
BA_ "GenSigSNA" SG_ 2432631423 SQC_SG_MPC_C04_Pkt "0h";
BA_ "FlexKomIsMotorola" SG_ 2432631423 SQC_SG_MPC_C04_Pkt 1;
BA_ "FlexKomComment" SG_ 2432631423 SQC_SG_MPC_C04_Pkt "MPC_C04_Pkt";
BA_ "FlexKomSigName" SG_ 2432631423 SQC_SG_MPC_C04_Pkt "MPC_C04_Pkt";
BA_ "FlexKomSigLaenge" SG_ 2432631423 SQC_SG_MPC_C04_Pkt 64;
BA_ "FlexKomSigStartPos" SG_ 2432631423 SQC_SG_MPC_C04_Pkt 7;
BA_ "FlexKomSID" SG_ 2432631423 SQC_SG_MPC_C04_Pkt 100677019;
BA_ "FlexKomSigStartValue" SG_ 2432631423 SQC_SG_MPC_C04_Pkt "DFF0FFFFFFFFFFFFh";
BA_ "GenSigCycleTime" SG_ 2432631423 SQC_SG_MPC_C04_Pkt 50;
BA_ "GenSigSNA" SG_ 2432631423 LaneChgInd_Stat_MPC "3h";
BA_ "FlexKomIsMotorola" SG_ 2432631423 LaneChgInd_Stat_MPC 1;
BA_ "FlexKomComment" SG_ 2432631423 LaneChgInd_Stat_MPC "MPC_C04_Pkt";
BA_ "FlexKomSigName" SG_ 2432631423 LaneChgInd_Stat_MPC "MPC_C04_Pkt";
BA_ "FlexKomSigLaenge" SG_ 2432631423 LaneChgInd_Stat_MPC 64;
BA_ "FlexKomSigStartPos" SG_ 2432631423 LaneChgInd_Stat_MPC 7;
BA_ "FlexKomSID" SG_ 2432631423 LaneChgInd_Stat_MPC 100677019;
BA_ "GenSigStartValue" SG_ 2432631423 LaneChgInd_Stat_MPC 3;
BA_ "FlexKomSigStartValue" SG_ 2432631423 LaneChgInd_Stat_MPC "DFF0FFFFFFFFFFFFh";
BA_ "GenSigCycleTime" SG_ 2432631423 LaneChgInd_Stat_MPC 50;
BA_ "GenSigSNA" SG_ 2432631423 LaneDtct_Fail_Stat_MPC "3h";
BA_ "FlexKomIsMotorola" SG_ 2432631423 LaneDtct_Fail_Stat_MPC 1;
BA_ "FlexKomComment" SG_ 2432631423 LaneDtct_Fail_Stat_MPC "MPC_C04_Pkt";
BA_ "FlexKomSigName" SG_ 2432631423 LaneDtct_Fail_Stat_MPC "MPC_C04_Pkt";
BA_ "FlexKomSigLaenge" SG_ 2432631423 LaneDtct_Fail_Stat_MPC 64;
BA_ "FlexKomSigStartPos" SG_ 2432631423 LaneDtct_Fail_Stat_MPC 7;
BA_ "FlexKomSID" SG_ 2432631423 LaneDtct_Fail_Stat_MPC 100677019;
BA_ "GenSigStartValue" SG_ 2432631423 LaneDtct_Fail_Stat_MPC 3;
BA_ "FlexKomSigStartValue" SG_ 2432631423 LaneDtct_Fail_Stat_MPC "DFF0FFFFFFFFFFFFh";
BA_ "GenSigCycleTime" SG_ 2432631423 LaneDtct_Fail_Stat_MPC 50;
BA_ "GenSigSNA" SG_ 2432631423 ConfLaneLt_Cval_MPC "Fh";
BA_ "FlexKomIsMotorola" SG_ 2432631423 ConfLaneLt_Cval_MPC 1;
BA_ "FlexKomComment" SG_ 2432631423 ConfLaneLt_Cval_MPC "MPC_C04_Pkt";
BA_ "FlexKomSigName" SG_ 2432631423 ConfLaneLt_Cval_MPC "MPC_C04_Pkt";
BA_ "FlexKomSigLaenge" SG_ 2432631423 ConfLaneLt_Cval_MPC 64;
BA_ "FlexKomSigStartPos" SG_ 2432631423 ConfLaneLt_Cval_MPC 7;
BA_ "FlexKomSID" SG_ 2432631423 ConfLaneLt_Cval_MPC 100677019;
BA_ "GenSigStartValue" SG_ 2432631423 ConfLaneLt_Cval_MPC 15;
BA_ "FlexKomSigStartValue" SG_ 2432631423 ConfLaneLt_Cval_MPC "DFF0FFFFFFFFFFFFh";
BA_ "GenSigCycleTime" SG_ 2432631423 ConfLaneLt_Cval_MPC 50;
BA_ "GenSigSNA" SG_ 2432631423 ConfLaneRt_Cval_MPC "Fh";
BA_ "FlexKomIsMotorola" SG_ 2432631423 ConfLaneRt_Cval_MPC 1;
BA_ "FlexKomComment" SG_ 2432631423 ConfLaneRt_Cval_MPC "MPC_C04_Pkt";
BA_ "FlexKomSigName" SG_ 2432631423 ConfLaneRt_Cval_MPC "MPC_C04_Pkt";
BA_ "FlexKomSigLaenge" SG_ 2432631423 ConfLaneRt_Cval_MPC 64;
BA_ "FlexKomSigStartPos" SG_ 2432631423 ConfLaneRt_Cval_MPC 7;
BA_ "FlexKomSID" SG_ 2432631423 ConfLaneRt_Cval_MPC 100677019;
BA_ "GenSigStartValue" SG_ 2432631423 ConfLaneRt_Cval_MPC 15;
BA_ "FlexKomSigStartValue" SG_ 2432631423 ConfLaneRt_Cval_MPC "DFF0FFFFFFFFFFFFh";
BA_ "GenSigCycleTime" SG_ 2432631423 ConfLaneRt_Cval_MPC 50;
BA_ "GenSigSNA" SG_ 2432631423 Spd_Y_LaneMarkLt_MPC "FFh";
BA_ "FlexKomIsMotorola" SG_ 2432631423 Spd_Y_LaneMarkLt_MPC 1;
BA_ "FlexKomComment" SG_ 2432631423 Spd_Y_LaneMarkLt_MPC "MPC_C04_Pkt";
BA_ "FlexKomSigName" SG_ 2432631423 Spd_Y_LaneMarkLt_MPC "MPC_C04_Pkt";
BA_ "FlexKomSigLaenge" SG_ 2432631423 Spd_Y_LaneMarkLt_MPC 64;
BA_ "FlexKomSigStartPos" SG_ 2432631423 Spd_Y_LaneMarkLt_MPC 7;
BA_ "FlexKomSID" SG_ 2432631423 Spd_Y_LaneMarkLt_MPC 100677019;
BA_ "GenSigStartValue" SG_ 2432631423 Spd_Y_LaneMarkLt_MPC 255;
BA_ "FlexKomSigStartValue" SG_ 2432631423 Spd_Y_LaneMarkLt_MPC "DFF0FFFFFFFFFFFFh";
BA_ "GenSigCycleTime" SG_ 2432631423 Spd_Y_LaneMarkLt_MPC 50;
BA_ "GenSigSNA" SG_ 2432631423 LaneCrvtrLt_Cval_MPC "FFFFh";
BA_ "FlexKomIsMotorola" SG_ 2432631423 LaneCrvtrLt_Cval_MPC 1;
BA_ "FlexKomComment" SG_ 2432631423 LaneCrvtrLt_Cval_MPC "MPC_C04_Pkt";
BA_ "FlexKomSigName" SG_ 2432631423 LaneCrvtrLt_Cval_MPC "MPC_C04_Pkt";
BA_ "FlexKomSigLaenge" SG_ 2432631423 LaneCrvtrLt_Cval_MPC 64;
BA_ "FlexKomSigStartPos" SG_ 2432631423 LaneCrvtrLt_Cval_MPC 7;
BA_ "FlexKomSID" SG_ 2432631423 LaneCrvtrLt_Cval_MPC 100677019;
BA_ "GenSigStartValue" SG_ 2432631423 LaneCrvtrLt_Cval_MPC 65535;
BA_ "FlexKomSigStartValue" SG_ 2432631423 LaneCrvtrLt_Cval_MPC "DFF0FFFFFFFFFFFFh";
BA_ "GenSigCycleTime" SG_ 2432631423 LaneCrvtrLt_Cval_MPC 50;
BA_ "GenSigSNA" SG_ 2432631423 AnglYawLaneLt_Cval_MPC "FFFFh";
BA_ "FlexKomIsMotorola" SG_ 2432631423 AnglYawLaneLt_Cval_MPC 1;
BA_ "FlexKomComment" SG_ 2432631423 AnglYawLaneLt_Cval_MPC "MPC_C04_Pkt";
BA_ "FlexKomSigName" SG_ 2432631423 AnglYawLaneLt_Cval_MPC "MPC_C04_Pkt";
BA_ "FlexKomSigLaenge" SG_ 2432631423 AnglYawLaneLt_Cval_MPC 64;
BA_ "FlexKomSigStartPos" SG_ 2432631423 AnglYawLaneLt_Cval_MPC 7;
BA_ "FlexKomSID" SG_ 2432631423 AnglYawLaneLt_Cval_MPC 100677019;
BA_ "GenSigStartValue" SG_ 2432631423 AnglYawLaneLt_Cval_MPC 65535;
BA_ "FlexKomSigStartValue" SG_ 2432631423 AnglYawLaneLt_Cval_MPC "DFF0FFFFFFFFFFFFh";
BA_ "GenSigCycleTime" SG_ 2432631423 AnglYawLaneLt_Cval_MPC 50;
BA_ "GenSigSNA" SG_ 2432631679 CRC_SG_MPC_C05_Pkt "4Ah";
BA_ "FlexKomIsMotorola" SG_ 2432631679 CRC_SG_MPC_C05_Pkt 1;
BA_ "FlexKomComment" SG_ 2432631679 CRC_SG_MPC_C05_Pkt "MPC_C05_Pkt";
BA_ "FlexKomSigName" SG_ 2432631679 CRC_SG_MPC_C05_Pkt "MPC_C05_Pkt";
BA_ "FlexKomSigLaenge" SG_ 2432631679 CRC_SG_MPC_C05_Pkt 64;
BA_ "FlexKomSigStartPos" SG_ 2432631679 CRC_SG_MPC_C05_Pkt 7;
BA_ "FlexKomSID" SG_ 2432631679 CRC_SG_MPC_C05_Pkt 100679811;
BA_ "GenSigStartValue" SG_ 2432631679 CRC_SG_MPC_C05_Pkt 74;
BA_ "FlexKomSigStartValue" SG_ 2432631679 CRC_SG_MPC_C05_Pkt "4AF0FFFFFFFFFFFFh";
BA_ "GenSigCycleTime" SG_ 2432631679 CRC_SG_MPC_C05_Pkt 50;
BA_ "GenSigSNA" SG_ 2432631679 SQC_SG_MPC_C05_Pkt "0h";
BA_ "FlexKomIsMotorola" SG_ 2432631679 SQC_SG_MPC_C05_Pkt 1;
BA_ "FlexKomComment" SG_ 2432631679 SQC_SG_MPC_C05_Pkt "MPC_C05_Pkt";
BA_ "FlexKomSigName" SG_ 2432631679 SQC_SG_MPC_C05_Pkt "MPC_C05_Pkt";
BA_ "FlexKomSigLaenge" SG_ 2432631679 SQC_SG_MPC_C05_Pkt 64;
BA_ "FlexKomSigStartPos" SG_ 2432631679 SQC_SG_MPC_C05_Pkt 7;
BA_ "FlexKomSID" SG_ 2432631679 SQC_SG_MPC_C05_Pkt 100679811;
BA_ "FlexKomSigStartValue" SG_ 2432631679 SQC_SG_MPC_C05_Pkt "4AF0FFFFFFFFFFFFh";
BA_ "GenSigCycleTime" SG_ 2432631679 SQC_SG_MPC_C05_Pkt 50;
BA_ "GenSigSNA" SG_ 2432631679 IntDtctAvl_Cval "3h";
BA_ "FlexKomIsMotorola" SG_ 2432631679 IntDtctAvl_Cval 1;
BA_ "FlexKomComment" SG_ 2432631679 IntDtctAvl_Cval "MPC_C05_Pkt";
BA_ "FlexKomSigName" SG_ 2432631679 IntDtctAvl_Cval "MPC_C05_Pkt";
BA_ "FlexKomSigLaenge" SG_ 2432631679 IntDtctAvl_Cval 64;
BA_ "FlexKomSigStartPos" SG_ 2432631679 IntDtctAvl_Cval 7;
BA_ "FlexKomSID" SG_ 2432631679 IntDtctAvl_Cval 100679811;
BA_ "GenSigStartValue" SG_ 2432631679 IntDtctAvl_Cval 3;
BA_ "FlexKomSigStartValue" SG_ 2432631679 IntDtctAvl_Cval "4AF0FFFFFFFFFFFFh";
BA_ "GenSigCycleTime" SG_ 2432631679 IntDtctAvl_Cval 50;
BA_ "GenSigSNA" SG_ 2432631679 IntDtct_Cval "3h";
BA_ "FlexKomIsMotorola" SG_ 2432631679 IntDtct_Cval 1;
BA_ "FlexKomComment" SG_ 2432631679 IntDtct_Cval "MPC_C05_Pkt";
BA_ "FlexKomSigName" SG_ 2432631679 IntDtct_Cval "MPC_C05_Pkt";
BA_ "FlexKomSigLaenge" SG_ 2432631679 IntDtct_Cval 64;
BA_ "FlexKomSigStartPos" SG_ 2432631679 IntDtct_Cval 7;
BA_ "FlexKomSID" SG_ 2432631679 IntDtct_Cval 100679811;
BA_ "GenSigStartValue" SG_ 2432631679 IntDtct_Cval 3;
BA_ "FlexKomSigStartValue" SG_ 2432631679 IntDtct_Cval "4AF0FFFFFFFFFFFFh";
BA_ "GenSigCycleTime" SG_ 2432631679 IntDtct_Cval 50;
BA_ "GenSigSNA" SG_ 2432631679 DeltaTmStmp_Obj_MPC "FFh";
BA_ "FlexKomIsMotorola" SG_ 2432631679 DeltaTmStmp_Obj_MPC 1;
BA_ "FlexKomComment" SG_ 2432631679 DeltaTmStmp_Obj_MPC "MPC_C05_Pkt";
BA_ "FlexKomSigName" SG_ 2432631679 DeltaTmStmp_Obj_MPC "MPC_C05_Pkt";
BA_ "FlexKomSigLaenge" SG_ 2432631679 DeltaTmStmp_Obj_MPC 64;
BA_ "FlexKomSigStartPos" SG_ 2432631679 DeltaTmStmp_Obj_MPC 7;
BA_ "FlexKomSID" SG_ 2432631679 DeltaTmStmp_Obj_MPC 100679811;
BA_ "GenSigStartValue" SG_ 2432631679 DeltaTmStmp_Obj_MPC 255;
BA_ "FlexKomSigStartValue" SG_ 2432631679 DeltaTmStmp_Obj_MPC "4AF0FFFFFFFFFFFFh";
BA_ "GenSigCycleTime" SG_ 2432631679 DeltaTmStmp_Obj_MPC 50;
BA_ "GenSigSNA" SG_ 2432631679 Spd_Y_LaneMarkRt_MPC "FFh";
BA_ "FlexKomIsMotorola" SG_ 2432631679 Spd_Y_LaneMarkRt_MPC 1;
BA_ "FlexKomComment" SG_ 2432631679 Spd_Y_LaneMarkRt_MPC "MPC_C05_Pkt";
BA_ "FlexKomSigName" SG_ 2432631679 Spd_Y_LaneMarkRt_MPC "MPC_C05_Pkt";
BA_ "FlexKomSigLaenge" SG_ 2432631679 Spd_Y_LaneMarkRt_MPC 64;
BA_ "FlexKomSigStartPos" SG_ 2432631679 Spd_Y_LaneMarkRt_MPC 7;
BA_ "FlexKomSID" SG_ 2432631679 Spd_Y_LaneMarkRt_MPC 100679811;
BA_ "GenSigStartValue" SG_ 2432631679 Spd_Y_LaneMarkRt_MPC 255;
BA_ "FlexKomSigStartValue" SG_ 2432631679 Spd_Y_LaneMarkRt_MPC "4AF0FFFFFFFFFFFFh";
BA_ "GenSigCycleTime" SG_ 2432631679 Spd_Y_LaneMarkRt_MPC 50;
BA_ "GenSigSNA" SG_ 2432631679 LaneCrvtrRt_Cval_MPC "FFFFh";
BA_ "FlexKomIsMotorola" SG_ 2432631679 LaneCrvtrRt_Cval_MPC 1;
BA_ "FlexKomComment" SG_ 2432631679 LaneCrvtrRt_Cval_MPC "MPC_C05_Pkt";
BA_ "FlexKomSigName" SG_ 2432631679 LaneCrvtrRt_Cval_MPC "MPC_C05_Pkt";
BA_ "FlexKomSigLaenge" SG_ 2432631679 LaneCrvtrRt_Cval_MPC 64;
BA_ "FlexKomSigStartPos" SG_ 2432631679 LaneCrvtrRt_Cval_MPC 7;
BA_ "FlexKomSID" SG_ 2432631679 LaneCrvtrRt_Cval_MPC 100679811;
BA_ "GenSigStartValue" SG_ 2432631679 LaneCrvtrRt_Cval_MPC 65535;
BA_ "FlexKomSigStartValue" SG_ 2432631679 LaneCrvtrRt_Cval_MPC "4AF0FFFFFFFFFFFFh";
BA_ "GenSigCycleTime" SG_ 2432631679 LaneCrvtrRt_Cval_MPC 50;
BA_ "GenSigSNA" SG_ 2432631679 AnglYawLaneRt_Cval_MPC "FFFFh";
BA_ "FlexKomIsMotorola" SG_ 2432631679 AnglYawLaneRt_Cval_MPC 1;
BA_ "FlexKomComment" SG_ 2432631679 AnglYawLaneRt_Cval_MPC "MPC_C05_Pkt";
BA_ "FlexKomSigName" SG_ 2432631679 AnglYawLaneRt_Cval_MPC "MPC_C05_Pkt";
BA_ "FlexKomSigLaenge" SG_ 2432631679 AnglYawLaneRt_Cval_MPC 64;
BA_ "FlexKomSigStartPos" SG_ 2432631679 AnglYawLaneRt_Cval_MPC 7;
BA_ "FlexKomSID" SG_ 2432631679 AnglYawLaneRt_Cval_MPC 100679811;
BA_ "GenSigStartValue" SG_ 2432631679 AnglYawLaneRt_Cval_MPC 65535;
BA_ "FlexKomSigStartValue" SG_ 2432631679 AnglYawLaneRt_Cval_MPC "4AF0FFFFFFFFFFFFh";
BA_ "GenSigCycleTime" SG_ 2432631679 AnglYawLaneRt_Cval_MPC 50;
BA_ "GenSigSNA" SG_ 2432631935 CRC_SG_MPC_C07_Pkt "1Ch";
BA_ "FlexKomIsMotorola" SG_ 2432631935 CRC_SG_MPC_C07_Pkt 1;
BA_ "FlexKomComment" SG_ 2432631935 CRC_SG_MPC_C07_Pkt "MPC_C07_Pkt";
BA_ "FlexKomSigName" SG_ 2432631935 CRC_SG_MPC_C07_Pkt "MPC_C07_Pkt";
BA_ "FlexKomSigLaenge" SG_ 2432631935 CRC_SG_MPC_C07_Pkt 64;
BA_ "FlexKomSigStartPos" SG_ 2432631935 CRC_SG_MPC_C07_Pkt 7;
BA_ "FlexKomSID" SG_ 2432631935 CRC_SG_MPC_C07_Pkt 100679813;
BA_ "GenSigStartValue" SG_ 2432631935 CRC_SG_MPC_C07_Pkt 28;
BA_ "FlexKomSigStartValue" SG_ 2432631935 CRC_SG_MPC_C07_Pkt "1CF0FFFFFFFFFFFFh";
BA_ "GenSigCycleTime" SG_ 2432631935 CRC_SG_MPC_C07_Pkt 50;
BA_ "GenSigSNA" SG_ 2432631935 SQC_SG_MPC_C07_Pkt "0h";
BA_ "FlexKomIsMotorola" SG_ 2432631935 SQC_SG_MPC_C07_Pkt 1;
BA_ "FlexKomComment" SG_ 2432631935 SQC_SG_MPC_C07_Pkt "MPC_C07_Pkt";
BA_ "FlexKomSigName" SG_ 2432631935 SQC_SG_MPC_C07_Pkt "MPC_C07_Pkt";
BA_ "FlexKomSigLaenge" SG_ 2432631935 SQC_SG_MPC_C07_Pkt 64;
BA_ "FlexKomSigStartPos" SG_ 2432631935 SQC_SG_MPC_C07_Pkt 7;
BA_ "FlexKomSID" SG_ 2432631935 SQC_SG_MPC_C07_Pkt 100679813;
BA_ "FlexKomSigStartValue" SG_ 2432631935 SQC_SG_MPC_C07_Pkt "1CF0FFFFFFFFFFFFh";
BA_ "GenSigCycleTime" SG_ 2432631935 SQC_SG_MPC_C07_Pkt 50;
BA_ "GenSigSNA" SG_ 2432631935 ConfLvl_PedObj0_Cval "3h";
BA_ "FlexKomIsMotorola" SG_ 2432631935 ConfLvl_PedObj0_Cval 1;
BA_ "FlexKomComment" SG_ 2432631935 ConfLvl_PedObj0_Cval "MPC_C07_Pkt";
BA_ "FlexKomSigName" SG_ 2432631935 ConfLvl_PedObj0_Cval "MPC_C07_Pkt";
BA_ "FlexKomSigLaenge" SG_ 2432631935 ConfLvl_PedObj0_Cval 64;
BA_ "FlexKomSigStartPos" SG_ 2432631935 ConfLvl_PedObj0_Cval 7;
BA_ "FlexKomSID" SG_ 2432631935 ConfLvl_PedObj0_Cval 100679813;
BA_ "GenSigStartValue" SG_ 2432631935 ConfLvl_PedObj0_Cval 3;
BA_ "FlexKomSigStartValue" SG_ 2432631935 ConfLvl_PedObj0_Cval "1CF0FFFFFFFFFFFFh";
BA_ "GenSigCycleTime" SG_ 2432631935 ConfLvl_PedObj0_Cval 50;
BA_ "GenSigSNA" SG_ 2432631935 DtctStat_PedObj0_MPC "3h";
BA_ "FlexKomIsMotorola" SG_ 2432631935 DtctStat_PedObj0_MPC 1;
BA_ "FlexKomComment" SG_ 2432631935 DtctStat_PedObj0_MPC "MPC_C07_Pkt";
BA_ "FlexKomSigName" SG_ 2432631935 DtctStat_PedObj0_MPC "MPC_C07_Pkt";
BA_ "FlexKomSigLaenge" SG_ 2432631935 DtctStat_PedObj0_MPC 64;
BA_ "FlexKomSigStartPos" SG_ 2432631935 DtctStat_PedObj0_MPC 7;
BA_ "FlexKomSID" SG_ 2432631935 DtctStat_PedObj0_MPC 100679813;
BA_ "GenSigStartValue" SG_ 2432631935 DtctStat_PedObj0_MPC 3;
BA_ "FlexKomSigStartValue" SG_ 2432631935 DtctStat_PedObj0_MPC "1CF0FFFFFFFFFFFFh";
BA_ "GenSigCycleTime" SG_ 2432631935 DtctStat_PedObj0_MPC 50;
BA_ "GenSigSNA" SG_ 2432631935 Spd_X_PedObj0_Cval_MPC "FFh";
BA_ "FlexKomIsMotorola" SG_ 2432631935 Spd_X_PedObj0_Cval_MPC 1;
BA_ "FlexKomComment" SG_ 2432631935 Spd_X_PedObj0_Cval_MPC "MPC_C07_Pkt";
BA_ "FlexKomSigName" SG_ 2432631935 Spd_X_PedObj0_Cval_MPC "MPC_C07_Pkt";
BA_ "FlexKomSigLaenge" SG_ 2432631935 Spd_X_PedObj0_Cval_MPC 64;
BA_ "FlexKomSigStartPos" SG_ 2432631935 Spd_X_PedObj0_Cval_MPC 7;
BA_ "FlexKomSID" SG_ 2432631935 Spd_X_PedObj0_Cval_MPC 100679813;
BA_ "GenSigStartValue" SG_ 2432631935 Spd_X_PedObj0_Cval_MPC 255;
BA_ "FlexKomSigStartValue" SG_ 2432631935 Spd_X_PedObj0_Cval_MPC "1CF0FFFFFFFFFFFFh";
BA_ "GenSigCycleTime" SG_ 2432631935 Spd_X_PedObj0_Cval_MPC 50;
BA_ "GenSigSNA" SG_ 2432631935 Spd_Y_PedObj0_Cval_MPC "FFh";
BA_ "FlexKomIsMotorola" SG_ 2432631935 Spd_Y_PedObj0_Cval_MPC 1;
BA_ "FlexKomComment" SG_ 2432631935 Spd_Y_PedObj0_Cval_MPC "MPC_C07_Pkt";
BA_ "FlexKomSigName" SG_ 2432631935 Spd_Y_PedObj0_Cval_MPC "MPC_C07_Pkt";
BA_ "FlexKomSigLaenge" SG_ 2432631935 Spd_Y_PedObj0_Cval_MPC 64;
BA_ "FlexKomSigStartPos" SG_ 2432631935 Spd_Y_PedObj0_Cval_MPC 7;
BA_ "FlexKomSID" SG_ 2432631935 Spd_Y_PedObj0_Cval_MPC 100679813;
BA_ "GenSigStartValue" SG_ 2432631935 Spd_Y_PedObj0_Cval_MPC 255;
BA_ "FlexKomSigStartValue" SG_ 2432631935 Spd_Y_PedObj0_Cval_MPC "1CF0FFFFFFFFFFFFh";
BA_ "GenSigCycleTime" SG_ 2432631935 Spd_Y_PedObj0_Cval_MPC 50;
BA_ "GenSigSNA" SG_ 2432631935 Dist_X_PedObj0_Cval_MPC "FFFFh";
BA_ "FlexKomIsMotorola" SG_ 2432631935 Dist_X_PedObj0_Cval_MPC 1;
BA_ "FlexKomComment" SG_ 2432631935 Dist_X_PedObj0_Cval_MPC "MPC_C07_Pkt";
BA_ "FlexKomSigName" SG_ 2432631935 Dist_X_PedObj0_Cval_MPC "MPC_C07_Pkt";
BA_ "FlexKomSigLaenge" SG_ 2432631935 Dist_X_PedObj0_Cval_MPC 64;
BA_ "FlexKomSigStartPos" SG_ 2432631935 Dist_X_PedObj0_Cval_MPC 7;
BA_ "FlexKomSID" SG_ 2432631935 Dist_X_PedObj0_Cval_MPC 100679813;
BA_ "GenSigStartValue" SG_ 2432631935 Dist_X_PedObj0_Cval_MPC 65535;
BA_ "FlexKomSigStartValue" SG_ 2432631935 Dist_X_PedObj0_Cval_MPC "1CF0FFFFFFFFFFFFh";
BA_ "GenSigCycleTime" SG_ 2432631935 Dist_X_PedObj0_Cval_MPC 50;
BA_ "GenSigSNA" SG_ 2432631935 Dist_Y_PedObj0_Cval_MPC "FFFFh";
BA_ "FlexKomIsMotorola" SG_ 2432631935 Dist_Y_PedObj0_Cval_MPC 1;
BA_ "FlexKomComment" SG_ 2432631935 Dist_Y_PedObj0_Cval_MPC "MPC_C07_Pkt";
BA_ "FlexKomSigName" SG_ 2432631935 Dist_Y_PedObj0_Cval_MPC "MPC_C07_Pkt";
BA_ "FlexKomSigLaenge" SG_ 2432631935 Dist_Y_PedObj0_Cval_MPC 64;
BA_ "FlexKomSigStartPos" SG_ 2432631935 Dist_Y_PedObj0_Cval_MPC 7;
BA_ "FlexKomSID" SG_ 2432631935 Dist_Y_PedObj0_Cval_MPC 100679813;
BA_ "GenSigStartValue" SG_ 2432631935 Dist_Y_PedObj0_Cval_MPC 65535;
BA_ "FlexKomSigStartValue" SG_ 2432631935 Dist_Y_PedObj0_Cval_MPC "1CF0FFFFFFFFFFFFh";
BA_ "GenSigCycleTime" SG_ 2432631935 Dist_Y_PedObj0_Cval_MPC 50;
BA_ "GenSigSNA" SG_ 2432632191 CRC_SG_MPC_C08_Pkt "66h";
BA_ "FlexKomIsMotorola" SG_ 2432632191 CRC_SG_MPC_C08_Pkt 1;
BA_ "FlexKomComment" SG_ 2432632191 CRC_SG_MPC_C08_Pkt "MPC_C08_Pkt";
BA_ "FlexKomSigName" SG_ 2432632191 CRC_SG_MPC_C08_Pkt "MPC_C08_Pkt";
BA_ "FlexKomSigLaenge" SG_ 2432632191 CRC_SG_MPC_C08_Pkt 64;
BA_ "FlexKomSigStartPos" SG_ 2432632191 CRC_SG_MPC_C08_Pkt 7;
BA_ "FlexKomSID" SG_ 2432632191 CRC_SG_MPC_C08_Pkt 100679816;
BA_ "GenSigStartValue" SG_ 2432632191 CRC_SG_MPC_C08_Pkt 102;
BA_ "FlexKomSigStartValue" SG_ 2432632191 CRC_SG_MPC_C08_Pkt "66F0FFFFFFFFFFFFh";
BA_ "GenSigCycleTime" SG_ 2432632191 CRC_SG_MPC_C08_Pkt 50;
BA_ "GenSigSNA" SG_ 2432632191 SQC_SG_MPC_C08_Pkt "0h";
BA_ "FlexKomIsMotorola" SG_ 2432632191 SQC_SG_MPC_C08_Pkt 1;
BA_ "FlexKomComment" SG_ 2432632191 SQC_SG_MPC_C08_Pkt "MPC_C08_Pkt";
BA_ "FlexKomSigName" SG_ 2432632191 SQC_SG_MPC_C08_Pkt "MPC_C08_Pkt";
BA_ "FlexKomSigLaenge" SG_ 2432632191 SQC_SG_MPC_C08_Pkt 64;
BA_ "FlexKomSigStartPos" SG_ 2432632191 SQC_SG_MPC_C08_Pkt 7;
BA_ "FlexKomSID" SG_ 2432632191 SQC_SG_MPC_C08_Pkt 100679816;
BA_ "FlexKomSigStartValue" SG_ 2432632191 SQC_SG_MPC_C08_Pkt "66F0FFFFFFFFFFFFh";
BA_ "GenSigCycleTime" SG_ 2432632191 SQC_SG_MPC_C08_Pkt 50;
BA_ "GenSigSNA" SG_ 2432632191 ConfLvl_PedObj1_Cval "3h";
BA_ "FlexKomIsMotorola" SG_ 2432632191 ConfLvl_PedObj1_Cval 1;
BA_ "FlexKomComment" SG_ 2432632191 ConfLvl_PedObj1_Cval "MPC_C08_Pkt";
BA_ "FlexKomSigName" SG_ 2432632191 ConfLvl_PedObj1_Cval "MPC_C08_Pkt";
BA_ "FlexKomSigLaenge" SG_ 2432632191 ConfLvl_PedObj1_Cval 64;
BA_ "FlexKomSigStartPos" SG_ 2432632191 ConfLvl_PedObj1_Cval 7;
BA_ "FlexKomSID" SG_ 2432632191 ConfLvl_PedObj1_Cval 100679816;
BA_ "GenSigStartValue" SG_ 2432632191 ConfLvl_PedObj1_Cval 3;
BA_ "FlexKomSigStartValue" SG_ 2432632191 ConfLvl_PedObj1_Cval "66F0FFFFFFFFFFFFh";
BA_ "GenSigCycleTime" SG_ 2432632191 ConfLvl_PedObj1_Cval 50;
BA_ "GenSigSNA" SG_ 2432632191 DtctStat_PedObj1_MPC "3h";
BA_ "FlexKomIsMotorola" SG_ 2432632191 DtctStat_PedObj1_MPC 1;
BA_ "FlexKomComment" SG_ 2432632191 DtctStat_PedObj1_MPC "MPC_C08_Pkt";
BA_ "FlexKomSigName" SG_ 2432632191 DtctStat_PedObj1_MPC "MPC_C08_Pkt";
BA_ "FlexKomSigLaenge" SG_ 2432632191 DtctStat_PedObj1_MPC 64;
BA_ "FlexKomSigStartPos" SG_ 2432632191 DtctStat_PedObj1_MPC 7;
BA_ "FlexKomSID" SG_ 2432632191 DtctStat_PedObj1_MPC 100679816;
BA_ "GenSigStartValue" SG_ 2432632191 DtctStat_PedObj1_MPC 3;
BA_ "FlexKomSigStartValue" SG_ 2432632191 DtctStat_PedObj1_MPC "66F0FFFFFFFFFFFFh";
BA_ "GenSigCycleTime" SG_ 2432632191 DtctStat_PedObj1_MPC 50;
BA_ "GenSigSNA" SG_ 2432632191 Spd_X_PedObj1_Cval_MPC "FFh";
BA_ "FlexKomIsMotorola" SG_ 2432632191 Spd_X_PedObj1_Cval_MPC 1;
BA_ "FlexKomComment" SG_ 2432632191 Spd_X_PedObj1_Cval_MPC "MPC_C08_Pkt";
BA_ "FlexKomSigName" SG_ 2432632191 Spd_X_PedObj1_Cval_MPC "MPC_C08_Pkt";
BA_ "FlexKomSigLaenge" SG_ 2432632191 Spd_X_PedObj1_Cval_MPC 64;
BA_ "FlexKomSigStartPos" SG_ 2432632191 Spd_X_PedObj1_Cval_MPC 7;
BA_ "FlexKomSID" SG_ 2432632191 Spd_X_PedObj1_Cval_MPC 100679816;
BA_ "GenSigStartValue" SG_ 2432632191 Spd_X_PedObj1_Cval_MPC 255;
BA_ "FlexKomSigStartValue" SG_ 2432632191 Spd_X_PedObj1_Cval_MPC "66F0FFFFFFFFFFFFh";
BA_ "GenSigCycleTime" SG_ 2432632191 Spd_X_PedObj1_Cval_MPC 50;
BA_ "GenSigSNA" SG_ 2432632191 Spd_Y_PedObj1_Cval_MPC "FFh";
BA_ "FlexKomIsMotorola" SG_ 2432632191 Spd_Y_PedObj1_Cval_MPC 1;
BA_ "FlexKomComment" SG_ 2432632191 Spd_Y_PedObj1_Cval_MPC "MPC_C08_Pkt";
BA_ "FlexKomSigName" SG_ 2432632191 Spd_Y_PedObj1_Cval_MPC "MPC_C08_Pkt";
BA_ "FlexKomSigLaenge" SG_ 2432632191 Spd_Y_PedObj1_Cval_MPC 64;
BA_ "FlexKomSigStartPos" SG_ 2432632191 Spd_Y_PedObj1_Cval_MPC 7;
BA_ "FlexKomSID" SG_ 2432632191 Spd_Y_PedObj1_Cval_MPC 100679816;
BA_ "GenSigStartValue" SG_ 2432632191 Spd_Y_PedObj1_Cval_MPC 255;
BA_ "FlexKomSigStartValue" SG_ 2432632191 Spd_Y_PedObj1_Cval_MPC "66F0FFFFFFFFFFFFh";
BA_ "GenSigCycleTime" SG_ 2432632191 Spd_Y_PedObj1_Cval_MPC 50;
BA_ "GenSigSNA" SG_ 2432632191 Dist_X_PedObj1_Cval_MPC "FFFFh";
BA_ "FlexKomIsMotorola" SG_ 2432632191 Dist_X_PedObj1_Cval_MPC 1;
BA_ "FlexKomComment" SG_ 2432632191 Dist_X_PedObj1_Cval_MPC "MPC_C08_Pkt";
BA_ "FlexKomSigName" SG_ 2432632191 Dist_X_PedObj1_Cval_MPC "MPC_C08_Pkt";
BA_ "FlexKomSigLaenge" SG_ 2432632191 Dist_X_PedObj1_Cval_MPC 64;
BA_ "FlexKomSigStartPos" SG_ 2432632191 Dist_X_PedObj1_Cval_MPC 7;
BA_ "FlexKomSID" SG_ 2432632191 Dist_X_PedObj1_Cval_MPC 100679816;
BA_ "GenSigStartValue" SG_ 2432632191 Dist_X_PedObj1_Cval_MPC 65535;
BA_ "FlexKomSigStartValue" SG_ 2432632191 Dist_X_PedObj1_Cval_MPC "66F0FFFFFFFFFFFFh";
BA_ "GenSigCycleTime" SG_ 2432632191 Dist_X_PedObj1_Cval_MPC 50;
BA_ "GenSigSNA" SG_ 2432632191 Dist_Y_PedObj1_Cval_MPC "FFFFh";
BA_ "FlexKomIsMotorola" SG_ 2432632191 Dist_Y_PedObj1_Cval_MPC 1;
BA_ "FlexKomComment" SG_ 2432632191 Dist_Y_PedObj1_Cval_MPC "MPC_C08_Pkt";
BA_ "FlexKomSigName" SG_ 2432632191 Dist_Y_PedObj1_Cval_MPC "MPC_C08_Pkt";
BA_ "FlexKomSigLaenge" SG_ 2432632191 Dist_Y_PedObj1_Cval_MPC 64;
BA_ "FlexKomSigStartPos" SG_ 2432632191 Dist_Y_PedObj1_Cval_MPC 7;
BA_ "FlexKomSID" SG_ 2432632191 Dist_Y_PedObj1_Cval_MPC 100679816;
BA_ "GenSigStartValue" SG_ 2432632191 Dist_Y_PedObj1_Cval_MPC 65535;
BA_ "FlexKomSigStartValue" SG_ 2432632191 Dist_Y_PedObj1_Cval_MPC "66F0FFFFFFFFFFFFh";
BA_ "GenSigCycleTime" SG_ 2432632191 Dist_Y_PedObj1_Cval_MPC 50;
BA_ "GenSigSNA" SG_ 2432632447 CRC_SG_MPC_C09_Pkt "65h";
BA_ "FlexKomIsMotorola" SG_ 2432632447 CRC_SG_MPC_C09_Pkt 1;
BA_ "FlexKomComment" SG_ 2432632447 CRC_SG_MPC_C09_Pkt "MPC_C09_Pkt";
BA_ "FlexKomSigName" SG_ 2432632447 CRC_SG_MPC_C09_Pkt "MPC_C09_Pkt";
BA_ "FlexKomSigLaenge" SG_ 2432632447 CRC_SG_MPC_C09_Pkt 64;
BA_ "FlexKomSigStartPos" SG_ 2432632447 CRC_SG_MPC_C09_Pkt 7;
BA_ "FlexKomSID" SG_ 2432632447 CRC_SG_MPC_C09_Pkt 100679818;
BA_ "GenSigStartValue" SG_ 2432632447 CRC_SG_MPC_C09_Pkt 101;
BA_ "FlexKomSigStartValue" SG_ 2432632447 CRC_SG_MPC_C09_Pkt "65F0FFFFFFFFFFFFh";
BA_ "GenSigCycleTime" SG_ 2432632447 CRC_SG_MPC_C09_Pkt 50;
BA_ "GenSigSNA" SG_ 2432632447 SQC_SG_MPC_C09_Pkt "0h";
BA_ "FlexKomIsMotorola" SG_ 2432632447 SQC_SG_MPC_C09_Pkt 1;
BA_ "FlexKomComment" SG_ 2432632447 SQC_SG_MPC_C09_Pkt "MPC_C09_Pkt";
BA_ "FlexKomSigName" SG_ 2432632447 SQC_SG_MPC_C09_Pkt "MPC_C09_Pkt";
BA_ "FlexKomSigLaenge" SG_ 2432632447 SQC_SG_MPC_C09_Pkt 64;
BA_ "FlexKomSigStartPos" SG_ 2432632447 SQC_SG_MPC_C09_Pkt 7;
BA_ "FlexKomSID" SG_ 2432632447 SQC_SG_MPC_C09_Pkt 100679818;
BA_ "FlexKomSigStartValue" SG_ 2432632447 SQC_SG_MPC_C09_Pkt "65F0FFFFFFFFFFFFh";
BA_ "GenSigCycleTime" SG_ 2432632447 SQC_SG_MPC_C09_Pkt 50;
BA_ "GenSigSNA" SG_ 2432632447 ConfLvl_PedObj2_Cval "3h";
BA_ "FlexKomIsMotorola" SG_ 2432632447 ConfLvl_PedObj2_Cval 1;
BA_ "FlexKomComment" SG_ 2432632447 ConfLvl_PedObj2_Cval "MPC_C09_Pkt";
BA_ "FlexKomSigName" SG_ 2432632447 ConfLvl_PedObj2_Cval "MPC_C09_Pkt";
BA_ "FlexKomSigLaenge" SG_ 2432632447 ConfLvl_PedObj2_Cval 64;
BA_ "FlexKomSigStartPos" SG_ 2432632447 ConfLvl_PedObj2_Cval 7;
BA_ "FlexKomSID" SG_ 2432632447 ConfLvl_PedObj2_Cval 100679818;
BA_ "GenSigStartValue" SG_ 2432632447 ConfLvl_PedObj2_Cval 3;
BA_ "FlexKomSigStartValue" SG_ 2432632447 ConfLvl_PedObj2_Cval "65F0FFFFFFFFFFFFh";
BA_ "GenSigCycleTime" SG_ 2432632447 ConfLvl_PedObj2_Cval 50;
BA_ "GenSigSNA" SG_ 2432632447 DtctStat_PedObj2_MPC "3h";
BA_ "FlexKomIsMotorola" SG_ 2432632447 DtctStat_PedObj2_MPC 1;
BA_ "FlexKomComment" SG_ 2432632447 DtctStat_PedObj2_MPC "MPC_C09_Pkt";
BA_ "FlexKomSigName" SG_ 2432632447 DtctStat_PedObj2_MPC "MPC_C09_Pkt";
BA_ "FlexKomSigLaenge" SG_ 2432632447 DtctStat_PedObj2_MPC 64;
BA_ "FlexKomSigStartPos" SG_ 2432632447 DtctStat_PedObj2_MPC 7;
BA_ "FlexKomSID" SG_ 2432632447 DtctStat_PedObj2_MPC 100679818;
BA_ "GenSigStartValue" SG_ 2432632447 DtctStat_PedObj2_MPC 3;
BA_ "FlexKomSigStartValue" SG_ 2432632447 DtctStat_PedObj2_MPC "65F0FFFFFFFFFFFFh";
BA_ "GenSigCycleTime" SG_ 2432632447 DtctStat_PedObj2_MPC 50;
BA_ "GenSigSNA" SG_ 2432632447 Spd_X_PedObj2_Cval_MPC "FFh";
BA_ "FlexKomIsMotorola" SG_ 2432632447 Spd_X_PedObj2_Cval_MPC 1;
BA_ "FlexKomComment" SG_ 2432632447 Spd_X_PedObj2_Cval_MPC "MPC_C09_Pkt";
BA_ "FlexKomSigName" SG_ 2432632447 Spd_X_PedObj2_Cval_MPC "MPC_C09_Pkt";
BA_ "FlexKomSigLaenge" SG_ 2432632447 Spd_X_PedObj2_Cval_MPC 64;
BA_ "FlexKomSigStartPos" SG_ 2432632447 Spd_X_PedObj2_Cval_MPC 7;
BA_ "FlexKomSID" SG_ 2432632447 Spd_X_PedObj2_Cval_MPC 100679818;
BA_ "GenSigStartValue" SG_ 2432632447 Spd_X_PedObj2_Cval_MPC 255;
BA_ "FlexKomSigStartValue" SG_ 2432632447 Spd_X_PedObj2_Cval_MPC "65F0FFFFFFFFFFFFh";
BA_ "GenSigCycleTime" SG_ 2432632447 Spd_X_PedObj2_Cval_MPC 50;
BA_ "GenSigSNA" SG_ 2432632447 Spd_Y_PedObj2_Cval_MPC "FFh";
BA_ "FlexKomIsMotorola" SG_ 2432632447 Spd_Y_PedObj2_Cval_MPC 1;
BA_ "FlexKomComment" SG_ 2432632447 Spd_Y_PedObj2_Cval_MPC "MPC_C09_Pkt";
BA_ "FlexKomSigName" SG_ 2432632447 Spd_Y_PedObj2_Cval_MPC "MPC_C09_Pkt";
BA_ "FlexKomSigLaenge" SG_ 2432632447 Spd_Y_PedObj2_Cval_MPC 64;
BA_ "FlexKomSigStartPos" SG_ 2432632447 Spd_Y_PedObj2_Cval_MPC 7;
BA_ "FlexKomSID" SG_ 2432632447 Spd_Y_PedObj2_Cval_MPC 100679818;
BA_ "GenSigStartValue" SG_ 2432632447 Spd_Y_PedObj2_Cval_MPC 255;
BA_ "FlexKomSigStartValue" SG_ 2432632447 Spd_Y_PedObj2_Cval_MPC "65F0FFFFFFFFFFFFh";
BA_ "GenSigCycleTime" SG_ 2432632447 Spd_Y_PedObj2_Cval_MPC 50;
BA_ "GenSigSNA" SG_ 2432632447 Dist_X_PedObj2_Cval_MPC "FFFFh";
BA_ "FlexKomIsMotorola" SG_ 2432632447 Dist_X_PedObj2_Cval_MPC 1;
BA_ "FlexKomComment" SG_ 2432632447 Dist_X_PedObj2_Cval_MPC "MPC_C09_Pkt";
BA_ "FlexKomSigName" SG_ 2432632447 Dist_X_PedObj2_Cval_MPC "MPC_C09_Pkt";
BA_ "FlexKomSigLaenge" SG_ 2432632447 Dist_X_PedObj2_Cval_MPC 64;
BA_ "FlexKomSigStartPos" SG_ 2432632447 Dist_X_PedObj2_Cval_MPC 7;
BA_ "FlexKomSID" SG_ 2432632447 Dist_X_PedObj2_Cval_MPC 100679818;
BA_ "GenSigStartValue" SG_ 2432632447 Dist_X_PedObj2_Cval_MPC 65535;
BA_ "FlexKomSigStartValue" SG_ 2432632447 Dist_X_PedObj2_Cval_MPC "65F0FFFFFFFFFFFFh";
BA_ "GenSigCycleTime" SG_ 2432632447 Dist_X_PedObj2_Cval_MPC 50;
BA_ "GenSigSNA" SG_ 2432632447 Dist_Y_PedObj2_Cval_MPC "FFFFh";
BA_ "FlexKomIsMotorola" SG_ 2432632447 Dist_Y_PedObj2_Cval_MPC 1;
BA_ "FlexKomComment" SG_ 2432632447 Dist_Y_PedObj2_Cval_MPC "MPC_C09_Pkt";
BA_ "FlexKomSigName" SG_ 2432632447 Dist_Y_PedObj2_Cval_MPC "MPC_C09_Pkt";
BA_ "FlexKomSigLaenge" SG_ 2432632447 Dist_Y_PedObj2_Cval_MPC 64;
BA_ "FlexKomSigStartPos" SG_ 2432632447 Dist_Y_PedObj2_Cval_MPC 7;
BA_ "FlexKomSID" SG_ 2432632447 Dist_Y_PedObj2_Cval_MPC 100679818;
BA_ "GenSigStartValue" SG_ 2432632447 Dist_Y_PedObj2_Cval_MPC 65535;
BA_ "FlexKomSigStartValue" SG_ 2432632447 Dist_Y_PedObj2_Cval_MPC "65F0FFFFFFFFFFFFh";
BA_ "GenSigCycleTime" SG_ 2432632447 Dist_Y_PedObj2_Cval_MPC 50;
BA_ "GenSigSNA" SG_ 2432632703 CRC_SG_MPC_C10_Pkt "78h";
BA_ "FlexKomIsMotorola" SG_ 2432632703 CRC_SG_MPC_C10_Pkt 1;
BA_ "FlexKomComment" SG_ 2432632703 CRC_SG_MPC_C10_Pkt "MPC_C10_Pkt";
BA_ "FlexKomSigName" SG_ 2432632703 CRC_SG_MPC_C10_Pkt "MPC_C10_Pkt";
BA_ "FlexKomSigLaenge" SG_ 2432632703 CRC_SG_MPC_C10_Pkt 64;
BA_ "FlexKomSigStartPos" SG_ 2432632703 CRC_SG_MPC_C10_Pkt 7;
BA_ "FlexKomSID" SG_ 2432632703 CRC_SG_MPC_C10_Pkt 100679819;
BA_ "GenSigStartValue" SG_ 2432632703 CRC_SG_MPC_C10_Pkt 120;
BA_ "FlexKomSigStartValue" SG_ 2432632703 CRC_SG_MPC_C10_Pkt "78F0FFFFFFFFFFFFh";
BA_ "GenSigCycleTime" SG_ 2432632703 CRC_SG_MPC_C10_Pkt 50;
BA_ "GenSigSNA" SG_ 2432632703 SQC_SG_MPC_C10_Pkt "0h";
BA_ "FlexKomIsMotorola" SG_ 2432632703 SQC_SG_MPC_C10_Pkt 1;
BA_ "FlexKomComment" SG_ 2432632703 SQC_SG_MPC_C10_Pkt "MPC_C10_Pkt";
BA_ "FlexKomSigName" SG_ 2432632703 SQC_SG_MPC_C10_Pkt "MPC_C10_Pkt";
BA_ "FlexKomSigLaenge" SG_ 2432632703 SQC_SG_MPC_C10_Pkt 64;
BA_ "FlexKomSigStartPos" SG_ 2432632703 SQC_SG_MPC_C10_Pkt 7;
BA_ "FlexKomSID" SG_ 2432632703 SQC_SG_MPC_C10_Pkt 100679819;
BA_ "FlexKomSigStartValue" SG_ 2432632703 SQC_SG_MPC_C10_Pkt "78F0FFFFFFFFFFFFh";
BA_ "GenSigCycleTime" SG_ 2432632703 SQC_SG_MPC_C10_Pkt 50;
BA_ "GenSigSNA" SG_ 2432632703 ConfLvl_PedObj3_Cval "3h";
BA_ "FlexKomIsMotorola" SG_ 2432632703 ConfLvl_PedObj3_Cval 1;
BA_ "FlexKomComment" SG_ 2432632703 ConfLvl_PedObj3_Cval "MPC_C10_Pkt";
BA_ "FlexKomSigName" SG_ 2432632703 ConfLvl_PedObj3_Cval "MPC_C10_Pkt";
BA_ "FlexKomSigLaenge" SG_ 2432632703 ConfLvl_PedObj3_Cval 64;
BA_ "FlexKomSigStartPos" SG_ 2432632703 ConfLvl_PedObj3_Cval 7;
BA_ "FlexKomSID" SG_ 2432632703 ConfLvl_PedObj3_Cval 100679819;
BA_ "GenSigStartValue" SG_ 2432632703 ConfLvl_PedObj3_Cval 3;
BA_ "FlexKomSigStartValue" SG_ 2432632703 ConfLvl_PedObj3_Cval "78F0FFFFFFFFFFFFh";
BA_ "GenSigCycleTime" SG_ 2432632703 ConfLvl_PedObj3_Cval 50;
BA_ "GenSigSNA" SG_ 2432632703 DtctStat_PedObj3_MPC "3h";
BA_ "FlexKomIsMotorola" SG_ 2432632703 DtctStat_PedObj3_MPC 1;
BA_ "FlexKomComment" SG_ 2432632703 DtctStat_PedObj3_MPC "MPC_C10_Pkt";
BA_ "FlexKomSigName" SG_ 2432632703 DtctStat_PedObj3_MPC "MPC_C10_Pkt";
BA_ "FlexKomSigLaenge" SG_ 2432632703 DtctStat_PedObj3_MPC 64;
BA_ "FlexKomSigStartPos" SG_ 2432632703 DtctStat_PedObj3_MPC 7;
BA_ "FlexKomSID" SG_ 2432632703 DtctStat_PedObj3_MPC 100679819;
BA_ "GenSigStartValue" SG_ 2432632703 DtctStat_PedObj3_MPC 3;
BA_ "FlexKomSigStartValue" SG_ 2432632703 DtctStat_PedObj3_MPC "78F0FFFFFFFFFFFFh";
BA_ "GenSigCycleTime" SG_ 2432632703 DtctStat_PedObj3_MPC 50;
BA_ "GenSigSNA" SG_ 2432632703 Spd_X_PedObj3_Cval_MPC "FFh";
BA_ "FlexKomIsMotorola" SG_ 2432632703 Spd_X_PedObj3_Cval_MPC 1;
BA_ "FlexKomComment" SG_ 2432632703 Spd_X_PedObj3_Cval_MPC "MPC_C10_Pkt";
BA_ "FlexKomSigName" SG_ 2432632703 Spd_X_PedObj3_Cval_MPC "MPC_C10_Pkt";
BA_ "FlexKomSigLaenge" SG_ 2432632703 Spd_X_PedObj3_Cval_MPC 64;
BA_ "FlexKomSigStartPos" SG_ 2432632703 Spd_X_PedObj3_Cval_MPC 7;
BA_ "FlexKomSID" SG_ 2432632703 Spd_X_PedObj3_Cval_MPC 100679819;
BA_ "GenSigStartValue" SG_ 2432632703 Spd_X_PedObj3_Cval_MPC 255;
BA_ "FlexKomSigStartValue" SG_ 2432632703 Spd_X_PedObj3_Cval_MPC "78F0FFFFFFFFFFFFh";
BA_ "GenSigCycleTime" SG_ 2432632703 Spd_X_PedObj3_Cval_MPC 50;
BA_ "GenSigSNA" SG_ 2432632703 Spd_Y_PedObj3_Cval_MPC "FFh";
BA_ "FlexKomIsMotorola" SG_ 2432632703 Spd_Y_PedObj3_Cval_MPC 1;
BA_ "FlexKomComment" SG_ 2432632703 Spd_Y_PedObj3_Cval_MPC "MPC_C10_Pkt";
BA_ "FlexKomSigName" SG_ 2432632703 Spd_Y_PedObj3_Cval_MPC "MPC_C10_Pkt";
BA_ "FlexKomSigLaenge" SG_ 2432632703 Spd_Y_PedObj3_Cval_MPC 64;
BA_ "FlexKomSigStartPos" SG_ 2432632703 Spd_Y_PedObj3_Cval_MPC 7;
BA_ "FlexKomSID" SG_ 2432632703 Spd_Y_PedObj3_Cval_MPC 100679819;
BA_ "GenSigStartValue" SG_ 2432632703 Spd_Y_PedObj3_Cval_MPC 255;
BA_ "FlexKomSigStartValue" SG_ 2432632703 Spd_Y_PedObj3_Cval_MPC "78F0FFFFFFFFFFFFh";
BA_ "GenSigCycleTime" SG_ 2432632703 Spd_Y_PedObj3_Cval_MPC 50;
BA_ "GenSigSNA" SG_ 2432632703 Dist_X_PedObj3_Cval_MPC "FFFFh";
BA_ "FlexKomIsMotorola" SG_ 2432632703 Dist_X_PedObj3_Cval_MPC 1;
BA_ "FlexKomComment" SG_ 2432632703 Dist_X_PedObj3_Cval_MPC "MPC_C10_Pkt";
BA_ "FlexKomSigName" SG_ 2432632703 Dist_X_PedObj3_Cval_MPC "MPC_C10_Pkt";
BA_ "FlexKomSigLaenge" SG_ 2432632703 Dist_X_PedObj3_Cval_MPC 64;
BA_ "FlexKomSigStartPos" SG_ 2432632703 Dist_X_PedObj3_Cval_MPC 7;
BA_ "FlexKomSID" SG_ 2432632703 Dist_X_PedObj3_Cval_MPC 100679819;
BA_ "GenSigStartValue" SG_ 2432632703 Dist_X_PedObj3_Cval_MPC 65535;
BA_ "FlexKomSigStartValue" SG_ 2432632703 Dist_X_PedObj3_Cval_MPC "78F0FFFFFFFFFFFFh";
BA_ "GenSigCycleTime" SG_ 2432632703 Dist_X_PedObj3_Cval_MPC 50;
BA_ "GenSigSNA" SG_ 2432632703 Dist_Y_PedObj3_Cval_MPC "FFFFh";
BA_ "FlexKomIsMotorola" SG_ 2432632703 Dist_Y_PedObj3_Cval_MPC 1;
BA_ "FlexKomComment" SG_ 2432632703 Dist_Y_PedObj3_Cval_MPC "MPC_C10_Pkt";
BA_ "FlexKomSigName" SG_ 2432632703 Dist_Y_PedObj3_Cval_MPC "MPC_C10_Pkt";
BA_ "FlexKomSigLaenge" SG_ 2432632703 Dist_Y_PedObj3_Cval_MPC 64;
BA_ "FlexKomSigStartPos" SG_ 2432632703 Dist_Y_PedObj3_Cval_MPC 7;
BA_ "FlexKomSID" SG_ 2432632703 Dist_Y_PedObj3_Cval_MPC 100679819;
BA_ "GenSigStartValue" SG_ 2432632703 Dist_Y_PedObj3_Cval_MPC 65535;
BA_ "FlexKomSigStartValue" SG_ 2432632703 Dist_Y_PedObj3_Cval_MPC "78F0FFFFFFFFFFFFh";
BA_ "GenSigCycleTime" SG_ 2432632703 Dist_Y_PedObj3_Cval_MPC 50;
BA_ "GenSigSNA" SG_ 2432632959 CRC_SG_MPC_C11_Pkt "4Eh";
BA_ "FlexKomIsMotorola" SG_ 2432632959 CRC_SG_MPC_C11_Pkt 1;
BA_ "FlexKomComment" SG_ 2432632959 CRC_SG_MPC_C11_Pkt "MPC_C11_Pkt";
BA_ "FlexKomSigName" SG_ 2432632959 CRC_SG_MPC_C11_Pkt "MPC_C11_Pkt";
BA_ "FlexKomSigLaenge" SG_ 2432632959 CRC_SG_MPC_C11_Pkt 64;
BA_ "FlexKomSigStartPos" SG_ 2432632959 CRC_SG_MPC_C11_Pkt 7;
BA_ "FlexKomSID" SG_ 2432632959 CRC_SG_MPC_C11_Pkt 100679821;
BA_ "GenSigStartValue" SG_ 2432632959 CRC_SG_MPC_C11_Pkt 78;
BA_ "FlexKomSigStartValue" SG_ 2432632959 CRC_SG_MPC_C11_Pkt "4EF0FFFFFFFFFFFFh";
BA_ "GenSigCycleTime" SG_ 2432632959 CRC_SG_MPC_C11_Pkt 50;
BA_ "GenSigSNA" SG_ 2432632959 SQC_SG_MPC_C11_Pkt "0h";
BA_ "FlexKomIsMotorola" SG_ 2432632959 SQC_SG_MPC_C11_Pkt 1;
BA_ "FlexKomComment" SG_ 2432632959 SQC_SG_MPC_C11_Pkt "MPC_C11_Pkt";
BA_ "FlexKomSigName" SG_ 2432632959 SQC_SG_MPC_C11_Pkt "MPC_C11_Pkt";
BA_ "FlexKomSigLaenge" SG_ 2432632959 SQC_SG_MPC_C11_Pkt 64;
BA_ "FlexKomSigStartPos" SG_ 2432632959 SQC_SG_MPC_C11_Pkt 7;
BA_ "FlexKomSID" SG_ 2432632959 SQC_SG_MPC_C11_Pkt 100679821;
BA_ "FlexKomSigStartValue" SG_ 2432632959 SQC_SG_MPC_C11_Pkt "4EF0FFFFFFFFFFFFh";
BA_ "GenSigCycleTime" SG_ 2432632959 SQC_SG_MPC_C11_Pkt 50;
BA_ "GenSigSNA" SG_ 2432632959 ConfLvl_PedObj4_Cval "3h";
BA_ "FlexKomIsMotorola" SG_ 2432632959 ConfLvl_PedObj4_Cval 1;
BA_ "FlexKomComment" SG_ 2432632959 ConfLvl_PedObj4_Cval "MPC_C11_Pkt";
BA_ "FlexKomSigName" SG_ 2432632959 ConfLvl_PedObj4_Cval "MPC_C11_Pkt";
BA_ "FlexKomSigLaenge" SG_ 2432632959 ConfLvl_PedObj4_Cval 64;
BA_ "FlexKomSigStartPos" SG_ 2432632959 ConfLvl_PedObj4_Cval 7;
BA_ "FlexKomSID" SG_ 2432632959 ConfLvl_PedObj4_Cval 100679821;
BA_ "GenSigStartValue" SG_ 2432632959 ConfLvl_PedObj4_Cval 3;
BA_ "FlexKomSigStartValue" SG_ 2432632959 ConfLvl_PedObj4_Cval "4EF0FFFFFFFFFFFFh";
BA_ "GenSigCycleTime" SG_ 2432632959 ConfLvl_PedObj4_Cval 50;
BA_ "GenSigSNA" SG_ 2432632959 DtctStat_PedObj4_MPC "3h";
BA_ "FlexKomIsMotorola" SG_ 2432632959 DtctStat_PedObj4_MPC 1;
BA_ "FlexKomComment" SG_ 2432632959 DtctStat_PedObj4_MPC "MPC_C11_Pkt";
BA_ "FlexKomSigName" SG_ 2432632959 DtctStat_PedObj4_MPC "MPC_C11_Pkt";
BA_ "FlexKomSigLaenge" SG_ 2432632959 DtctStat_PedObj4_MPC 64;
BA_ "FlexKomSigStartPos" SG_ 2432632959 DtctStat_PedObj4_MPC 7;
BA_ "FlexKomSID" SG_ 2432632959 DtctStat_PedObj4_MPC 100679821;
BA_ "GenSigStartValue" SG_ 2432632959 DtctStat_PedObj4_MPC 3;
BA_ "FlexKomSigStartValue" SG_ 2432632959 DtctStat_PedObj4_MPC "4EF0FFFFFFFFFFFFh";
BA_ "GenSigCycleTime" SG_ 2432632959 DtctStat_PedObj4_MPC 50;
BA_ "GenSigSNA" SG_ 2432632959 Spd_X_PedObj4_Cval_MPC "FFh";
BA_ "FlexKomIsMotorola" SG_ 2432632959 Spd_X_PedObj4_Cval_MPC 1;
BA_ "FlexKomComment" SG_ 2432632959 Spd_X_PedObj4_Cval_MPC "MPC_C11_Pkt";
BA_ "FlexKomSigName" SG_ 2432632959 Spd_X_PedObj4_Cval_MPC "MPC_C11_Pkt";
BA_ "FlexKomSigLaenge" SG_ 2432632959 Spd_X_PedObj4_Cval_MPC 64;
BA_ "FlexKomSigStartPos" SG_ 2432632959 Spd_X_PedObj4_Cval_MPC 7;
BA_ "FlexKomSID" SG_ 2432632959 Spd_X_PedObj4_Cval_MPC 100679821;
BA_ "GenSigStartValue" SG_ 2432632959 Spd_X_PedObj4_Cval_MPC 255;
BA_ "FlexKomSigStartValue" SG_ 2432632959 Spd_X_PedObj4_Cval_MPC "4EF0FFFFFFFFFFFFh";
BA_ "GenSigCycleTime" SG_ 2432632959 Spd_X_PedObj4_Cval_MPC 50;
BA_ "GenSigSNA" SG_ 2432632959 Spd_Y_PedObj4_Cval_MPC "FFh";
BA_ "FlexKomIsMotorola" SG_ 2432632959 Spd_Y_PedObj4_Cval_MPC 1;
BA_ "FlexKomComment" SG_ 2432632959 Spd_Y_PedObj4_Cval_MPC "MPC_C11_Pkt";
BA_ "FlexKomSigName" SG_ 2432632959 Spd_Y_PedObj4_Cval_MPC "MPC_C11_Pkt";
BA_ "FlexKomSigLaenge" SG_ 2432632959 Spd_Y_PedObj4_Cval_MPC 64;
BA_ "FlexKomSigStartPos" SG_ 2432632959 Spd_Y_PedObj4_Cval_MPC 7;
BA_ "FlexKomSID" SG_ 2432632959 Spd_Y_PedObj4_Cval_MPC 100679821;
BA_ "GenSigStartValue" SG_ 2432632959 Spd_Y_PedObj4_Cval_MPC 255;
BA_ "FlexKomSigStartValue" SG_ 2432632959 Spd_Y_PedObj4_Cval_MPC "4EF0FFFFFFFFFFFFh";
BA_ "GenSigCycleTime" SG_ 2432632959 Spd_Y_PedObj4_Cval_MPC 50;
BA_ "GenSigSNA" SG_ 2432632959 Dist_X_PedObj4_Cval_MPC "FFFFh";
BA_ "FlexKomIsMotorola" SG_ 2432632959 Dist_X_PedObj4_Cval_MPC 1;
BA_ "FlexKomComment" SG_ 2432632959 Dist_X_PedObj4_Cval_MPC "MPC_C11_Pkt";
BA_ "FlexKomSigName" SG_ 2432632959 Dist_X_PedObj4_Cval_MPC "MPC_C11_Pkt";
BA_ "FlexKomSigLaenge" SG_ 2432632959 Dist_X_PedObj4_Cval_MPC 64;
BA_ "FlexKomSigStartPos" SG_ 2432632959 Dist_X_PedObj4_Cval_MPC 7;
BA_ "FlexKomSID" SG_ 2432632959 Dist_X_PedObj4_Cval_MPC 100679821;
BA_ "GenSigStartValue" SG_ 2432632959 Dist_X_PedObj4_Cval_MPC 65535;
BA_ "FlexKomSigStartValue" SG_ 2432632959 Dist_X_PedObj4_Cval_MPC "4EF0FFFFFFFFFFFFh";
BA_ "GenSigCycleTime" SG_ 2432632959 Dist_X_PedObj4_Cval_MPC 50;
BA_ "GenSigSNA" SG_ 2432632959 Dist_Y_PedObj4_Cval_MPC "FFFFh";
BA_ "FlexKomIsMotorola" SG_ 2432632959 Dist_Y_PedObj4_Cval_MPC 1;
BA_ "FlexKomComment" SG_ 2432632959 Dist_Y_PedObj4_Cval_MPC "MPC_C11_Pkt";
BA_ "FlexKomSigName" SG_ 2432632959 Dist_Y_PedObj4_Cval_MPC "MPC_C11_Pkt";
BA_ "FlexKomSigLaenge" SG_ 2432632959 Dist_Y_PedObj4_Cval_MPC 64;
BA_ "FlexKomSigStartPos" SG_ 2432632959 Dist_Y_PedObj4_Cval_MPC 7;
BA_ "FlexKomSID" SG_ 2432632959 Dist_Y_PedObj4_Cval_MPC 100679821;
BA_ "GenSigStartValue" SG_ 2432632959 Dist_Y_PedObj4_Cval_MPC 65535;
BA_ "FlexKomSigStartValue" SG_ 2432632959 Dist_Y_PedObj4_Cval_MPC "4EF0FFFFFFFFFFFFh";
BA_ "GenSigCycleTime" SG_ 2432632959 Dist_Y_PedObj4_Cval_MPC 50;
BA_ "GenSigSNA" SG_ 2432633215 CRC_SG_MPC_C12_Pkt "F3h";
BA_ "FlexKomIsMotorola" SG_ 2432633215 CRC_SG_MPC_C12_Pkt 1;
BA_ "FlexKomComment" SG_ 2432633215 CRC_SG_MPC_C12_Pkt "MPC_C12_Pkt";
BA_ "FlexKomSigName" SG_ 2432633215 CRC_SG_MPC_C12_Pkt "MPC_C12_Pkt";
BA_ "FlexKomSigLaenge" SG_ 2432633215 CRC_SG_MPC_C12_Pkt 64;
BA_ "FlexKomSigStartPos" SG_ 2432633215 CRC_SG_MPC_C12_Pkt 7;
BA_ "FlexKomSID" SG_ 2432633215 CRC_SG_MPC_C12_Pkt 100679824;
BA_ "GenSigStartValue" SG_ 2432633215 CRC_SG_MPC_C12_Pkt 243;
BA_ "FlexKomSigStartValue" SG_ 2432633215 CRC_SG_MPC_C12_Pkt "F3F0FFFFFFFFFFFFh";
BA_ "GenSigCycleTime" SG_ 2432633215 CRC_SG_MPC_C12_Pkt 50;
BA_ "GenSigSNA" SG_ 2432633215 SQC_SG_MPC_C12_Pkt "0h";
BA_ "FlexKomIsMotorola" SG_ 2432633215 SQC_SG_MPC_C12_Pkt 1;
BA_ "FlexKomComment" SG_ 2432633215 SQC_SG_MPC_C12_Pkt "MPC_C12_Pkt";
BA_ "FlexKomSigName" SG_ 2432633215 SQC_SG_MPC_C12_Pkt "MPC_C12_Pkt";
BA_ "FlexKomSigLaenge" SG_ 2432633215 SQC_SG_MPC_C12_Pkt 64;
BA_ "FlexKomSigStartPos" SG_ 2432633215 SQC_SG_MPC_C12_Pkt 7;
BA_ "FlexKomSID" SG_ 2432633215 SQC_SG_MPC_C12_Pkt 100679824;
BA_ "FlexKomSigStartValue" SG_ 2432633215 SQC_SG_MPC_C12_Pkt "F3F0FFFFFFFFFFFFh";
BA_ "GenSigCycleTime" SG_ 2432633215 SQC_SG_MPC_C12_Pkt 50;
BA_ "GenSigSNA" SG_ 2432633215 ConfLvl_PedObj5_Cval "3h";
BA_ "FlexKomIsMotorola" SG_ 2432633215 ConfLvl_PedObj5_Cval 1;
BA_ "FlexKomComment" SG_ 2432633215 ConfLvl_PedObj5_Cval "MPC_C12_Pkt";
BA_ "FlexKomSigName" SG_ 2432633215 ConfLvl_PedObj5_Cval "MPC_C12_Pkt";
BA_ "FlexKomSigLaenge" SG_ 2432633215 ConfLvl_PedObj5_Cval 64;
BA_ "FlexKomSigStartPos" SG_ 2432633215 ConfLvl_PedObj5_Cval 7;
BA_ "FlexKomSID" SG_ 2432633215 ConfLvl_PedObj5_Cval 100679824;
BA_ "GenSigStartValue" SG_ 2432633215 ConfLvl_PedObj5_Cval 3;
BA_ "FlexKomSigStartValue" SG_ 2432633215 ConfLvl_PedObj5_Cval "F3F0FFFFFFFFFFFFh";
BA_ "GenSigCycleTime" SG_ 2432633215 ConfLvl_PedObj5_Cval 50;
BA_ "GenSigSNA" SG_ 2432633215 DtctStat_PedObj5_MPC "3h";
BA_ "FlexKomIsMotorola" SG_ 2432633215 DtctStat_PedObj5_MPC 1;
BA_ "FlexKomComment" SG_ 2432633215 DtctStat_PedObj5_MPC "MPC_C12_Pkt";
BA_ "FlexKomSigName" SG_ 2432633215 DtctStat_PedObj5_MPC "MPC_C12_Pkt";
BA_ "FlexKomSigLaenge" SG_ 2432633215 DtctStat_PedObj5_MPC 64;
BA_ "FlexKomSigStartPos" SG_ 2432633215 DtctStat_PedObj5_MPC 7;
BA_ "FlexKomSID" SG_ 2432633215 DtctStat_PedObj5_MPC 100679824;
BA_ "GenSigStartValue" SG_ 2432633215 DtctStat_PedObj5_MPC 3;
BA_ "FlexKomSigStartValue" SG_ 2432633215 DtctStat_PedObj5_MPC "F3F0FFFFFFFFFFFFh";
BA_ "GenSigCycleTime" SG_ 2432633215 DtctStat_PedObj5_MPC 50;
BA_ "GenSigSNA" SG_ 2432633215 Spd_X_PedObj5_Cval_MPC "FFh";
BA_ "FlexKomIsMotorola" SG_ 2432633215 Spd_X_PedObj5_Cval_MPC 1;
BA_ "FlexKomComment" SG_ 2432633215 Spd_X_PedObj5_Cval_MPC "MPC_C12_Pkt";
BA_ "FlexKomSigName" SG_ 2432633215 Spd_X_PedObj5_Cval_MPC "MPC_C12_Pkt";
BA_ "FlexKomSigLaenge" SG_ 2432633215 Spd_X_PedObj5_Cval_MPC 64;
BA_ "FlexKomSigStartPos" SG_ 2432633215 Spd_X_PedObj5_Cval_MPC 7;
BA_ "FlexKomSID" SG_ 2432633215 Spd_X_PedObj5_Cval_MPC 100679824;
BA_ "GenSigStartValue" SG_ 2432633215 Spd_X_PedObj5_Cval_MPC 255;
BA_ "FlexKomSigStartValue" SG_ 2432633215 Spd_X_PedObj5_Cval_MPC "F3F0FFFFFFFFFFFFh";
BA_ "GenSigCycleTime" SG_ 2432633215 Spd_X_PedObj5_Cval_MPC 50;
BA_ "GenSigSNA" SG_ 2432633215 Spd_Y_PedObj5_Cval_MPC "FFh";
BA_ "FlexKomIsMotorola" SG_ 2432633215 Spd_Y_PedObj5_Cval_MPC 1;
BA_ "FlexKomComment" SG_ 2432633215 Spd_Y_PedObj5_Cval_MPC "MPC_C12_Pkt";
BA_ "FlexKomSigName" SG_ 2432633215 Spd_Y_PedObj5_Cval_MPC "MPC_C12_Pkt";
BA_ "FlexKomSigLaenge" SG_ 2432633215 Spd_Y_PedObj5_Cval_MPC 64;
BA_ "FlexKomSigStartPos" SG_ 2432633215 Spd_Y_PedObj5_Cval_MPC 7;
BA_ "FlexKomSID" SG_ 2432633215 Spd_Y_PedObj5_Cval_MPC 100679824;
BA_ "GenSigStartValue" SG_ 2432633215 Spd_Y_PedObj5_Cval_MPC 255;
BA_ "FlexKomSigStartValue" SG_ 2432633215 Spd_Y_PedObj5_Cval_MPC "F3F0FFFFFFFFFFFFh";
BA_ "GenSigCycleTime" SG_ 2432633215 Spd_Y_PedObj5_Cval_MPC 50;
BA_ "GenSigSNA" SG_ 2432633215 Dist_X_PedObj5_Cval_MPC "FFFFh";
BA_ "FlexKomIsMotorola" SG_ 2432633215 Dist_X_PedObj5_Cval_MPC 1;
BA_ "FlexKomComment" SG_ 2432633215 Dist_X_PedObj5_Cval_MPC "MPC_C12_Pkt";
BA_ "FlexKomSigName" SG_ 2432633215 Dist_X_PedObj5_Cval_MPC "MPC_C12_Pkt";
BA_ "FlexKomSigLaenge" SG_ 2432633215 Dist_X_PedObj5_Cval_MPC 64;
BA_ "FlexKomSigStartPos" SG_ 2432633215 Dist_X_PedObj5_Cval_MPC 7;
BA_ "FlexKomSID" SG_ 2432633215 Dist_X_PedObj5_Cval_MPC 100679824;
BA_ "GenSigStartValue" SG_ 2432633215 Dist_X_PedObj5_Cval_MPC 65535;
BA_ "FlexKomSigStartValue" SG_ 2432633215 Dist_X_PedObj5_Cval_MPC "F3F0FFFFFFFFFFFFh";
BA_ "GenSigCycleTime" SG_ 2432633215 Dist_X_PedObj5_Cval_MPC 50;
BA_ "GenSigSNA" SG_ 2432633215 Dist_Y_PedObj5_Cval_MPC "FFFFh";
BA_ "FlexKomIsMotorola" SG_ 2432633215 Dist_Y_PedObj5_Cval_MPC 1;
BA_ "FlexKomComment" SG_ 2432633215 Dist_Y_PedObj5_Cval_MPC "MPC_C12_Pkt";
BA_ "FlexKomSigName" SG_ 2432633215 Dist_Y_PedObj5_Cval_MPC "MPC_C12_Pkt";
BA_ "FlexKomSigLaenge" SG_ 2432633215 Dist_Y_PedObj5_Cval_MPC 64;
BA_ "FlexKomSigStartPos" SG_ 2432633215 Dist_Y_PedObj5_Cval_MPC 7;
BA_ "FlexKomSID" SG_ 2432633215 Dist_Y_PedObj5_Cval_MPC 100679824;
BA_ "GenSigStartValue" SG_ 2432633215 Dist_Y_PedObj5_Cval_MPC 65535;
BA_ "FlexKomSigStartValue" SG_ 2432633215 Dist_Y_PedObj5_Cval_MPC "F3F0FFFFFFFFFFFFh";
BA_ "GenSigCycleTime" SG_ 2432633215 Dist_Y_PedObj5_Cval_MPC 50;
BA_ "GenSigSNA" SG_ 2432633471 CRC_SG_MPC_C13_Pkt "FFh";
BA_ "FlexKomIsMotorola" SG_ 2432633471 CRC_SG_MPC_C13_Pkt 1;
BA_ "FlexKomComment" SG_ 2432633471 CRC_SG_MPC_C13_Pkt "MPC_C13_Pkt";
BA_ "FlexKomSigName" SG_ 2432633471 CRC_SG_MPC_C13_Pkt "MPC_C13_Pkt";
BA_ "FlexKomSigLaenge" SG_ 2432633471 CRC_SG_MPC_C13_Pkt 64;
BA_ "FlexKomSigStartPos" SG_ 2432633471 CRC_SG_MPC_C13_Pkt 7;
BA_ "FlexKomSID" SG_ 2432633471 CRC_SG_MPC_C13_Pkt 100679825;
BA_ "GenSigStartValue" SG_ 2432633471 CRC_SG_MPC_C13_Pkt 255;
BA_ "FlexKomSigStartValue" SG_ 2432633471 CRC_SG_MPC_C13_Pkt "FFF0FFFFFFFFFFFFh";
BA_ "GenSigCycleTime" SG_ 2432633471 CRC_SG_MPC_C13_Pkt 50;
BA_ "GenSigSNA" SG_ 2432633471 SQC_SG_MPC_C13_Pkt "0h";
BA_ "FlexKomIsMotorola" SG_ 2432633471 SQC_SG_MPC_C13_Pkt 1;
BA_ "FlexKomComment" SG_ 2432633471 SQC_SG_MPC_C13_Pkt "MPC_C13_Pkt";
BA_ "FlexKomSigName" SG_ 2432633471 SQC_SG_MPC_C13_Pkt "MPC_C13_Pkt";
BA_ "FlexKomSigLaenge" SG_ 2432633471 SQC_SG_MPC_C13_Pkt 64;
BA_ "FlexKomSigStartPos" SG_ 2432633471 SQC_SG_MPC_C13_Pkt 7;
BA_ "FlexKomSID" SG_ 2432633471 SQC_SG_MPC_C13_Pkt 100679825;
BA_ "FlexKomSigStartValue" SG_ 2432633471 SQC_SG_MPC_C13_Pkt "FFF0FFFFFFFFFFFFh";
BA_ "GenSigCycleTime" SG_ 2432633471 SQC_SG_MPC_C13_Pkt 50;
BA_ "GenSigSNA" SG_ 2432633471 ClassPedObj0_Stat_MPC "Fh";
BA_ "FlexKomIsMotorola" SG_ 2432633471 ClassPedObj0_Stat_MPC 1;
BA_ "FlexKomComment" SG_ 2432633471 ClassPedObj0_Stat_MPC "MPC_C13_Pkt";
BA_ "FlexKomSigName" SG_ 2432633471 ClassPedObj0_Stat_MPC "MPC_C13_Pkt";
BA_ "FlexKomSigLaenge" SG_ 2432633471 ClassPedObj0_Stat_MPC 64;
BA_ "FlexKomSigStartPos" SG_ 2432633471 ClassPedObj0_Stat_MPC 7;
BA_ "FlexKomSID" SG_ 2432633471 ClassPedObj0_Stat_MPC 100679825;
BA_ "GenSigStartValue" SG_ 2432633471 ClassPedObj0_Stat_MPC 15;
BA_ "FlexKomSigStartValue" SG_ 2432633471 ClassPedObj0_Stat_MPC "FFF0FFFFFFFFFFFFh";
BA_ "GenSigCycleTime" SG_ 2432633471 ClassPedObj0_Stat_MPC 50;
BA_ "GenSigSNA" SG_ 2432633471 NumPedObj0_Cval_MPC "1Fh";
BA_ "FlexKomIsMotorola" SG_ 2432633471 NumPedObj0_Cval_MPC 1;
BA_ "FlexKomComment" SG_ 2432633471 NumPedObj0_Cval_MPC "MPC_C13_Pkt";
BA_ "FlexKomSigName" SG_ 2432633471 NumPedObj0_Cval_MPC "MPC_C13_Pkt";
BA_ "FlexKomSigLaenge" SG_ 2432633471 NumPedObj0_Cval_MPC 64;
BA_ "FlexKomSigStartPos" SG_ 2432633471 NumPedObj0_Cval_MPC 7;
BA_ "FlexKomSID" SG_ 2432633471 NumPedObj0_Cval_MPC 100679825;
BA_ "GenSigStartValue" SG_ 2432633471 NumPedObj0_Cval_MPC 31;
BA_ "FlexKomSigStartValue" SG_ 2432633471 NumPedObj0_Cval_MPC "FFF0FFFFFFFFFFFFh";
BA_ "GenSigCycleTime" SG_ 2432633471 NumPedObj0_Cval_MPC 50;
BA_ "GenSigSNA" SG_ 2432633471 TypePedObj0_Stat_MPC "7h";
BA_ "FlexKomIsMotorola" SG_ 2432633471 TypePedObj0_Stat_MPC 1;
BA_ "FlexKomComment" SG_ 2432633471 TypePedObj0_Stat_MPC "MPC_C13_Pkt";
BA_ "FlexKomSigName" SG_ 2432633471 TypePedObj0_Stat_MPC "MPC_C13_Pkt";
BA_ "FlexKomSigLaenge" SG_ 2432633471 TypePedObj0_Stat_MPC 64;
BA_ "FlexKomSigStartPos" SG_ 2432633471 TypePedObj0_Stat_MPC 7;
BA_ "FlexKomSID" SG_ 2432633471 TypePedObj0_Stat_MPC 100679825;
BA_ "GenSigStartValue" SG_ 2432633471 TypePedObj0_Stat_MPC 7;
BA_ "FlexKomSigStartValue" SG_ 2432633471 TypePedObj0_Stat_MPC "FFF0FFFFFFFFFFFFh";
BA_ "GenSigCycleTime" SG_ 2432633471 TypePedObj0_Stat_MPC 50;
BA_ "GenSigSNA" SG_ 2432633471 StdRng_X_PedObj0_Cval_MPC "3h";
BA_ "FlexKomIsMotorola" SG_ 2432633471 StdRng_X_PedObj0_Cval_MPC 1;
BA_ "FlexKomComment" SG_ 2432633471 StdRng_X_PedObj0_Cval_MPC "MPC_C13_Pkt";
BA_ "FlexKomSigName" SG_ 2432633471 StdRng_X_PedObj0_Cval_MPC "MPC_C13_Pkt";
BA_ "FlexKomSigLaenge" SG_ 2432633471 StdRng_X_PedObj0_Cval_MPC 64;
BA_ "FlexKomSigStartPos" SG_ 2432633471 StdRng_X_PedObj0_Cval_MPC 7;
BA_ "FlexKomSID" SG_ 2432633471 StdRng_X_PedObj0_Cval_MPC 100679825;
BA_ "GenSigStartValue" SG_ 2432633471 StdRng_X_PedObj0_Cval_MPC 3;
BA_ "FlexKomSigStartValue" SG_ 2432633471 StdRng_X_PedObj0_Cval_MPC "FFF0FFFFFFFFFFFFh";
BA_ "GenSigCycleTime" SG_ 2432633471 StdRng_X_PedObj0_Cval_MPC 50;
BA_ "GenSigSNA" SG_ 2432633471 StdRng_Y_PedObj0_Cval_MPC "3h";
BA_ "FlexKomIsMotorola" SG_ 2432633471 StdRng_Y_PedObj0_Cval_MPC 1;
BA_ "FlexKomComment" SG_ 2432633471 StdRng_Y_PedObj0_Cval_MPC "MPC_C13_Pkt";
BA_ "FlexKomSigName" SG_ 2432633471 StdRng_Y_PedObj0_Cval_MPC "MPC_C13_Pkt";
BA_ "FlexKomSigLaenge" SG_ 2432633471 StdRng_Y_PedObj0_Cval_MPC 64;
BA_ "FlexKomSigStartPos" SG_ 2432633471 StdRng_Y_PedObj0_Cval_MPC 7;
BA_ "FlexKomSID" SG_ 2432633471 StdRng_Y_PedObj0_Cval_MPC 100679825;
BA_ "GenSigStartValue" SG_ 2432633471 StdRng_Y_PedObj0_Cval_MPC 3;
BA_ "FlexKomSigStartValue" SG_ 2432633471 StdRng_Y_PedObj0_Cval_MPC "FFF0FFFFFFFFFFFFh";
BA_ "GenSigCycleTime" SG_ 2432633471 StdRng_Y_PedObj0_Cval_MPC 50;
BA_ "GenSigSNA" SG_ 2432633471 StdRng_Spd_X_PedObj0_Cval_MPC "3h";
BA_ "FlexKomIsMotorola" SG_ 2432633471 StdRng_Spd_X_PedObj0_Cval_MPC 1;
BA_ "FlexKomComment" SG_ 2432633471 StdRng_Spd_X_PedObj0_Cval_MPC "MPC_C13_Pkt";
BA_ "FlexKomSigName" SG_ 2432633471 StdRng_Spd_X_PedObj0_Cval_MPC "MPC_C13_Pkt";
BA_ "FlexKomSigLaenge" SG_ 2432633471 StdRng_Spd_X_PedObj0_Cval_MPC 64;
BA_ "FlexKomSigStartPos" SG_ 2432633471 StdRng_Spd_X_PedObj0_Cval_MPC 7;
BA_ "FlexKomSID" SG_ 2432633471 StdRng_Spd_X_PedObj0_Cval_MPC 100679825;
BA_ "GenSigStartValue" SG_ 2432633471 StdRng_Spd_X_PedObj0_Cval_MPC 3;
BA_ "FlexKomSigStartValue" SG_ 2432633471 StdRng_Spd_X_PedObj0_Cval_MPC "FFF0FFFFFFFFFFFFh";
BA_ "GenSigCycleTime" SG_ 2432633471 StdRng_Spd_X_PedObj0_Cval_MPC 50;
BA_ "GenSigSNA" SG_ 2432633471 StdRng_Spd_Y_PedObj0_Cval_MPC "3h";
BA_ "FlexKomIsMotorola" SG_ 2432633471 StdRng_Spd_Y_PedObj0_Cval_MPC 1;
BA_ "FlexKomComment" SG_ 2432633471 StdRng_Spd_Y_PedObj0_Cval_MPC "MPC_C13_Pkt";
BA_ "FlexKomSigName" SG_ 2432633471 StdRng_Spd_Y_PedObj0_Cval_MPC "MPC_C13_Pkt";
BA_ "FlexKomSigLaenge" SG_ 2432633471 StdRng_Spd_Y_PedObj0_Cval_MPC 64;
BA_ "FlexKomSigStartPos" SG_ 2432633471 StdRng_Spd_Y_PedObj0_Cval_MPC 7;
BA_ "FlexKomSID" SG_ 2432633471 StdRng_Spd_Y_PedObj0_Cval_MPC 100679825;
BA_ "GenSigStartValue" SG_ 2432633471 StdRng_Spd_Y_PedObj0_Cval_MPC 3;
BA_ "FlexKomSigStartValue" SG_ 2432633471 StdRng_Spd_Y_PedObj0_Cval_MPC "FFF0FFFFFFFFFFFFh";
BA_ "GenSigCycleTime" SG_ 2432633471 StdRng_Spd_Y_PedObj0_Cval_MPC 50;
BA_ "GenSigSNA" SG_ 2432633471 WidthPedObj0_Cval_MPC "FFh";
BA_ "FlexKomIsMotorola" SG_ 2432633471 WidthPedObj0_Cval_MPC 1;
BA_ "FlexKomComment" SG_ 2432633471 WidthPedObj0_Cval_MPC "MPC_C13_Pkt";
BA_ "FlexKomSigName" SG_ 2432633471 WidthPedObj0_Cval_MPC "MPC_C13_Pkt";
BA_ "FlexKomSigLaenge" SG_ 2432633471 WidthPedObj0_Cval_MPC 64;
BA_ "FlexKomSigStartPos" SG_ 2432633471 WidthPedObj0_Cval_MPC 7;
BA_ "FlexKomSID" SG_ 2432633471 WidthPedObj0_Cval_MPC 100679825;
BA_ "GenSigStartValue" SG_ 2432633471 WidthPedObj0_Cval_MPC 255;
BA_ "FlexKomSigStartValue" SG_ 2432633471 WidthPedObj0_Cval_MPC "FFF0FFFFFFFFFFFFh";
BA_ "GenSigCycleTime" SG_ 2432633471 WidthPedObj0_Cval_MPC 50;
BA_ "GenSigSNA" SG_ 2432633471 OLA_PedObj0_Cval_MPC "FFh";
BA_ "FlexKomIsMotorola" SG_ 2432633471 OLA_PedObj0_Cval_MPC 1;
BA_ "FlexKomComment" SG_ 2432633471 OLA_PedObj0_Cval_MPC "MPC_C13_Pkt";
BA_ "FlexKomSigName" SG_ 2432633471 OLA_PedObj0_Cval_MPC "MPC_C13_Pkt";
BA_ "FlexKomSigLaenge" SG_ 2432633471 OLA_PedObj0_Cval_MPC 64;
BA_ "FlexKomSigStartPos" SG_ 2432633471 OLA_PedObj0_Cval_MPC 7;
BA_ "FlexKomSID" SG_ 2432633471 OLA_PedObj0_Cval_MPC 100679825;
BA_ "GenSigStartValue" SG_ 2432633471 OLA_PedObj0_Cval_MPC 255;
BA_ "FlexKomSigStartValue" SG_ 2432633471 OLA_PedObj0_Cval_MPC "FFF0FFFFFFFFFFFFh";
BA_ "GenSigCycleTime" SG_ 2432633471 OLA_PedObj0_Cval_MPC 50;
BA_ "GenSigSNA" SG_ 2432633471 HeightPedObj0_Cval_MPC "FFh";
BA_ "FlexKomIsMotorola" SG_ 2432633471 HeightPedObj0_Cval_MPC 1;
BA_ "FlexKomComment" SG_ 2432633471 HeightPedObj0_Cval_MPC "MPC_C13_Pkt";
BA_ "FlexKomSigName" SG_ 2432633471 HeightPedObj0_Cval_MPC "MPC_C13_Pkt";
BA_ "FlexKomSigLaenge" SG_ 2432633471 HeightPedObj0_Cval_MPC 64;
BA_ "FlexKomSigStartPos" SG_ 2432633471 HeightPedObj0_Cval_MPC 7;
BA_ "FlexKomSID" SG_ 2432633471 HeightPedObj0_Cval_MPC 100679825;
BA_ "GenSigStartValue" SG_ 2432633471 HeightPedObj0_Cval_MPC 255;
BA_ "FlexKomSigStartValue" SG_ 2432633471 HeightPedObj0_Cval_MPC "FFF0FFFFFFFFFFFFh";
BA_ "GenSigCycleTime" SG_ 2432633471 HeightPedObj0_Cval_MPC 50;
BA_ "GenSigSNA" SG_ 2432633471 LaneAlloc_PedObj0_Cval_MPC "7h";
BA_ "FlexKomIsMotorola" SG_ 2432633471 LaneAlloc_PedObj0_Cval_MPC 1;
BA_ "FlexKomComment" SG_ 2432633471 LaneAlloc_PedObj0_Cval_MPC "MPC_C13_Pkt";
BA_ "FlexKomSigName" SG_ 2432633471 LaneAlloc_PedObj0_Cval_MPC "MPC_C13_Pkt";
BA_ "FlexKomSigLaenge" SG_ 2432633471 LaneAlloc_PedObj0_Cval_MPC 64;
BA_ "FlexKomSigStartPos" SG_ 2432633471 LaneAlloc_PedObj0_Cval_MPC 7;
BA_ "FlexKomSID" SG_ 2432633471 LaneAlloc_PedObj0_Cval_MPC 100679825;
BA_ "GenSigStartValue" SG_ 2432633471 LaneAlloc_PedObj0_Cval_MPC 7;
BA_ "FlexKomSigStartValue" SG_ 2432633471 LaneAlloc_PedObj0_Cval_MPC "FFF0FFFFFFFFFFFFh";
BA_ "GenSigCycleTime" SG_ 2432633471 LaneAlloc_PedObj0_Cval_MPC 50;
BA_ "GenSigSNA" SG_ 2432633471 TurnSgl_PedObj0_Cval_MPC "7h";
BA_ "FlexKomIsMotorola" SG_ 2432633471 TurnSgl_PedObj0_Cval_MPC 1;
BA_ "FlexKomComment" SG_ 2432633471 TurnSgl_PedObj0_Cval_MPC "MPC_C13_Pkt";
BA_ "FlexKomSigName" SG_ 2432633471 TurnSgl_PedObj0_Cval_MPC "MPC_C13_Pkt";
BA_ "FlexKomSigLaenge" SG_ 2432633471 TurnSgl_PedObj0_Cval_MPC 64;
BA_ "FlexKomSigStartPos" SG_ 2432633471 TurnSgl_PedObj0_Cval_MPC 7;
BA_ "FlexKomSID" SG_ 2432633471 TurnSgl_PedObj0_Cval_MPC 100679825;
BA_ "GenSigStartValue" SG_ 2432633471 TurnSgl_PedObj0_Cval_MPC 7;
BA_ "FlexKomSigStartValue" SG_ 2432633471 TurnSgl_PedObj0_Cval_MPC "FFF0FFFFFFFFFFFFh";
BA_ "GenSigCycleTime" SG_ 2432633471 TurnSgl_PedObj0_Cval_MPC 50;
BA_ "GenSigSNA" SG_ 2432633471 LaneChgInd_PedObj0_Stat_MPC "3h";
BA_ "FlexKomIsMotorola" SG_ 2432633471 LaneChgInd_PedObj0_Stat_MPC 1;
BA_ "FlexKomComment" SG_ 2432633471 LaneChgInd_PedObj0_Stat_MPC "MPC_C13_Pkt";
BA_ "FlexKomSigName" SG_ 2432633471 LaneChgInd_PedObj0_Stat_MPC "MPC_C13_Pkt";
BA_ "FlexKomSigLaenge" SG_ 2432633471 LaneChgInd_PedObj0_Stat_MPC 64;
BA_ "FlexKomSigStartPos" SG_ 2432633471 LaneChgInd_PedObj0_Stat_MPC 7;
BA_ "FlexKomSID" SG_ 2432633471 LaneChgInd_PedObj0_Stat_MPC 100679825;
BA_ "GenSigStartValue" SG_ 2432633471 LaneChgInd_PedObj0_Stat_MPC 3;
BA_ "FlexKomSigStartValue" SG_ 2432633471 LaneChgInd_PedObj0_Stat_MPC "FFF0FFFFFFFFFFFFh";
BA_ "GenSigCycleTime" SG_ 2432633471 LaneChgInd_PedObj0_Stat_MPC 50;
BA_ "GenSigSNA" SG_ 2432633727 CRC_SG_MPC_C14_Pkt "C4h";
BA_ "FlexKomIsMotorola" SG_ 2432633727 CRC_SG_MPC_C14_Pkt 1;
BA_ "FlexKomComment" SG_ 2432633727 CRC_SG_MPC_C14_Pkt "MPC_C14_Pkt";
BA_ "FlexKomSigName" SG_ 2432633727 CRC_SG_MPC_C14_Pkt "MPC_C14_Pkt";
BA_ "FlexKomSigLaenge" SG_ 2432633727 CRC_SG_MPC_C14_Pkt 64;
BA_ "FlexKomSigStartPos" SG_ 2432633727 CRC_SG_MPC_C14_Pkt 7;
BA_ "FlexKomSID" SG_ 2432633727 CRC_SG_MPC_C14_Pkt 100679830;
BA_ "GenSigStartValue" SG_ 2432633727 CRC_SG_MPC_C14_Pkt 196;
BA_ "FlexKomSigStartValue" SG_ 2432633727 CRC_SG_MPC_C14_Pkt "C4F0FFFFFFFFFFFFh";
BA_ "GenSigCycleTime" SG_ 2432633727 CRC_SG_MPC_C14_Pkt 50;
BA_ "GenSigSNA" SG_ 2432633727 SQC_SG_MPC_C14_Pkt "0h";
BA_ "FlexKomIsMotorola" SG_ 2432633727 SQC_SG_MPC_C14_Pkt 1;
BA_ "FlexKomComment" SG_ 2432633727 SQC_SG_MPC_C14_Pkt "MPC_C14_Pkt";
BA_ "FlexKomSigName" SG_ 2432633727 SQC_SG_MPC_C14_Pkt "MPC_C14_Pkt";
BA_ "FlexKomSigLaenge" SG_ 2432633727 SQC_SG_MPC_C14_Pkt 64;
BA_ "FlexKomSigStartPos" SG_ 2432633727 SQC_SG_MPC_C14_Pkt 7;
BA_ "FlexKomSID" SG_ 2432633727 SQC_SG_MPC_C14_Pkt 100679830;
BA_ "FlexKomSigStartValue" SG_ 2432633727 SQC_SG_MPC_C14_Pkt "C4F0FFFFFFFFFFFFh";
BA_ "GenSigCycleTime" SG_ 2432633727 SQC_SG_MPC_C14_Pkt 50;
BA_ "GenSigSNA" SG_ 2432633727 ClassPedObj1_Stat_MPC "Fh";
BA_ "FlexKomIsMotorola" SG_ 2432633727 ClassPedObj1_Stat_MPC 1;
BA_ "FlexKomComment" SG_ 2432633727 ClassPedObj1_Stat_MPC "MPC_C14_Pkt";
BA_ "FlexKomSigName" SG_ 2432633727 ClassPedObj1_Stat_MPC "MPC_C14_Pkt";
BA_ "FlexKomSigLaenge" SG_ 2432633727 ClassPedObj1_Stat_MPC 64;
BA_ "FlexKomSigStartPos" SG_ 2432633727 ClassPedObj1_Stat_MPC 7;
BA_ "FlexKomSID" SG_ 2432633727 ClassPedObj1_Stat_MPC 100679830;
BA_ "GenSigStartValue" SG_ 2432633727 ClassPedObj1_Stat_MPC 15;
BA_ "FlexKomSigStartValue" SG_ 2432633727 ClassPedObj1_Stat_MPC "C4F0FFFFFFFFFFFFh";
BA_ "GenSigCycleTime" SG_ 2432633727 ClassPedObj1_Stat_MPC 50;
BA_ "GenSigSNA" SG_ 2432633727 NumPedObj1_Cval_MPC "1Fh";
BA_ "FlexKomIsMotorola" SG_ 2432633727 NumPedObj1_Cval_MPC 1;
BA_ "FlexKomComment" SG_ 2432633727 NumPedObj1_Cval_MPC "MPC_C14_Pkt";
BA_ "FlexKomSigName" SG_ 2432633727 NumPedObj1_Cval_MPC "MPC_C14_Pkt";
BA_ "FlexKomSigLaenge" SG_ 2432633727 NumPedObj1_Cval_MPC 64;
BA_ "FlexKomSigStartPos" SG_ 2432633727 NumPedObj1_Cval_MPC 7;
BA_ "FlexKomSID" SG_ 2432633727 NumPedObj1_Cval_MPC 100679830;
BA_ "GenSigStartValue" SG_ 2432633727 NumPedObj1_Cval_MPC 31;
BA_ "FlexKomSigStartValue" SG_ 2432633727 NumPedObj1_Cval_MPC "C4F0FFFFFFFFFFFFh";
BA_ "GenSigCycleTime" SG_ 2432633727 NumPedObj1_Cval_MPC 50;
BA_ "GenSigSNA" SG_ 2432633727 TypePedObj1_Stat_MPC "7h";
BA_ "FlexKomIsMotorola" SG_ 2432633727 TypePedObj1_Stat_MPC 1;
BA_ "FlexKomComment" SG_ 2432633727 TypePedObj1_Stat_MPC "MPC_C14_Pkt";
BA_ "FlexKomSigName" SG_ 2432633727 TypePedObj1_Stat_MPC "MPC_C14_Pkt";
BA_ "FlexKomSigLaenge" SG_ 2432633727 TypePedObj1_Stat_MPC 64;
BA_ "FlexKomSigStartPos" SG_ 2432633727 TypePedObj1_Stat_MPC 7;
BA_ "FlexKomSID" SG_ 2432633727 TypePedObj1_Stat_MPC 100679830;
BA_ "GenSigStartValue" SG_ 2432633727 TypePedObj1_Stat_MPC 7;
BA_ "FlexKomSigStartValue" SG_ 2432633727 TypePedObj1_Stat_MPC "C4F0FFFFFFFFFFFFh";
BA_ "GenSigCycleTime" SG_ 2432633727 TypePedObj1_Stat_MPC 50;
BA_ "GenSigSNA" SG_ 2432633727 StdRng_X_PedObj1_Cval_MPC "3h";
BA_ "FlexKomIsMotorola" SG_ 2432633727 StdRng_X_PedObj1_Cval_MPC 1;
BA_ "FlexKomComment" SG_ 2432633727 StdRng_X_PedObj1_Cval_MPC "MPC_C14_Pkt";
BA_ "FlexKomSigName" SG_ 2432633727 StdRng_X_PedObj1_Cval_MPC "MPC_C14_Pkt";
BA_ "FlexKomSigLaenge" SG_ 2432633727 StdRng_X_PedObj1_Cval_MPC 64;
BA_ "FlexKomSigStartPos" SG_ 2432633727 StdRng_X_PedObj1_Cval_MPC 7;
BA_ "FlexKomSID" SG_ 2432633727 StdRng_X_PedObj1_Cval_MPC 100679830;
BA_ "GenSigStartValue" SG_ 2432633727 StdRng_X_PedObj1_Cval_MPC 3;
BA_ "FlexKomSigStartValue" SG_ 2432633727 StdRng_X_PedObj1_Cval_MPC "C4F0FFFFFFFFFFFFh";
BA_ "GenSigCycleTime" SG_ 2432633727 StdRng_X_PedObj1_Cval_MPC 50;
BA_ "GenSigSNA" SG_ 2432633727 StdRng_Y_PedObj1_Cval_MPC "3h";
BA_ "FlexKomIsMotorola" SG_ 2432633727 StdRng_Y_PedObj1_Cval_MPC 1;
BA_ "FlexKomComment" SG_ 2432633727 StdRng_Y_PedObj1_Cval_MPC "MPC_C14_Pkt";
BA_ "FlexKomSigName" SG_ 2432633727 StdRng_Y_PedObj1_Cval_MPC "MPC_C14_Pkt";
BA_ "FlexKomSigLaenge" SG_ 2432633727 StdRng_Y_PedObj1_Cval_MPC 64;
BA_ "FlexKomSigStartPos" SG_ 2432633727 StdRng_Y_PedObj1_Cval_MPC 7;
BA_ "FlexKomSID" SG_ 2432633727 StdRng_Y_PedObj1_Cval_MPC 100679830;
BA_ "GenSigStartValue" SG_ 2432633727 StdRng_Y_PedObj1_Cval_MPC 3;
BA_ "FlexKomSigStartValue" SG_ 2432633727 StdRng_Y_PedObj1_Cval_MPC "C4F0FFFFFFFFFFFFh";
BA_ "GenSigCycleTime" SG_ 2432633727 StdRng_Y_PedObj1_Cval_MPC 50;
BA_ "GenSigSNA" SG_ 2432633727 StdRng_Spd_X_PedObj1_Cval_MPC "3h";
BA_ "FlexKomIsMotorola" SG_ 2432633727 StdRng_Spd_X_PedObj1_Cval_MPC 1;
BA_ "FlexKomComment" SG_ 2432633727 StdRng_Spd_X_PedObj1_Cval_MPC "MPC_C14_Pkt";
BA_ "FlexKomSigName" SG_ 2432633727 StdRng_Spd_X_PedObj1_Cval_MPC "MPC_C14_Pkt";
BA_ "FlexKomSigLaenge" SG_ 2432633727 StdRng_Spd_X_PedObj1_Cval_MPC 64;
BA_ "FlexKomSigStartPos" SG_ 2432633727 StdRng_Spd_X_PedObj1_Cval_MPC 7;
BA_ "FlexKomSID" SG_ 2432633727 StdRng_Spd_X_PedObj1_Cval_MPC 100679830;
BA_ "GenSigStartValue" SG_ 2432633727 StdRng_Spd_X_PedObj1_Cval_MPC 3;
BA_ "FlexKomSigStartValue" SG_ 2432633727 StdRng_Spd_X_PedObj1_Cval_MPC "C4F0FFFFFFFFFFFFh";
BA_ "GenSigCycleTime" SG_ 2432633727 StdRng_Spd_X_PedObj1_Cval_MPC 50;
BA_ "GenSigSNA" SG_ 2432633727 StdRng_Spd_Y_PedObj1_Cval_MPC "3h";
BA_ "FlexKomIsMotorola" SG_ 2432633727 StdRng_Spd_Y_PedObj1_Cval_MPC 1;
BA_ "FlexKomComment" SG_ 2432633727 StdRng_Spd_Y_PedObj1_Cval_MPC "MPC_C14_Pkt";
BA_ "FlexKomSigName" SG_ 2432633727 StdRng_Spd_Y_PedObj1_Cval_MPC "MPC_C14_Pkt";
BA_ "FlexKomSigLaenge" SG_ 2432633727 StdRng_Spd_Y_PedObj1_Cval_MPC 64;
BA_ "FlexKomSigStartPos" SG_ 2432633727 StdRng_Spd_Y_PedObj1_Cval_MPC 7;
BA_ "FlexKomSID" SG_ 2432633727 StdRng_Spd_Y_PedObj1_Cval_MPC 100679830;
BA_ "GenSigStartValue" SG_ 2432633727 StdRng_Spd_Y_PedObj1_Cval_MPC 3;
BA_ "FlexKomSigStartValue" SG_ 2432633727 StdRng_Spd_Y_PedObj1_Cval_MPC "C4F0FFFFFFFFFFFFh";
BA_ "GenSigCycleTime" SG_ 2432633727 StdRng_Spd_Y_PedObj1_Cval_MPC 50;
BA_ "GenSigSNA" SG_ 2432633727 WidthPedObj1_Cval_MPC "FFh";
BA_ "FlexKomIsMotorola" SG_ 2432633727 WidthPedObj1_Cval_MPC 1;
BA_ "FlexKomComment" SG_ 2432633727 WidthPedObj1_Cval_MPC "MPC_C14_Pkt";
BA_ "FlexKomSigName" SG_ 2432633727 WidthPedObj1_Cval_MPC "MPC_C14_Pkt";
BA_ "FlexKomSigLaenge" SG_ 2432633727 WidthPedObj1_Cval_MPC 64;
BA_ "FlexKomSigStartPos" SG_ 2432633727 WidthPedObj1_Cval_MPC 7;
BA_ "FlexKomSID" SG_ 2432633727 WidthPedObj1_Cval_MPC 100679830;
BA_ "GenSigStartValue" SG_ 2432633727 WidthPedObj1_Cval_MPC 255;
BA_ "FlexKomSigStartValue" SG_ 2432633727 WidthPedObj1_Cval_MPC "C4F0FFFFFFFFFFFFh";
BA_ "GenSigCycleTime" SG_ 2432633727 WidthPedObj1_Cval_MPC 50;
BA_ "GenSigSNA" SG_ 2432633727 OLA_PedObj1_Cval_MPC "FFh";
BA_ "FlexKomIsMotorola" SG_ 2432633727 OLA_PedObj1_Cval_MPC 1;
BA_ "FlexKomComment" SG_ 2432633727 OLA_PedObj1_Cval_MPC "MPC_C14_Pkt";
BA_ "FlexKomSigName" SG_ 2432633727 OLA_PedObj1_Cval_MPC "MPC_C14_Pkt";
BA_ "FlexKomSigLaenge" SG_ 2432633727 OLA_PedObj1_Cval_MPC 64;
BA_ "FlexKomSigStartPos" SG_ 2432633727 OLA_PedObj1_Cval_MPC 7;
BA_ "FlexKomSID" SG_ 2432633727 OLA_PedObj1_Cval_MPC 100679830;
BA_ "GenSigStartValue" SG_ 2432633727 OLA_PedObj1_Cval_MPC 255;
BA_ "FlexKomSigStartValue" SG_ 2432633727 OLA_PedObj1_Cval_MPC "C4F0FFFFFFFFFFFFh";
BA_ "GenSigCycleTime" SG_ 2432633727 OLA_PedObj1_Cval_MPC 50;
BA_ "GenSigSNA" SG_ 2432633727 HeightPedObj1_Cval_MPC "FFh";
BA_ "FlexKomIsMotorola" SG_ 2432633727 HeightPedObj1_Cval_MPC 1;
BA_ "FlexKomComment" SG_ 2432633727 HeightPedObj1_Cval_MPC "MPC_C14_Pkt";
BA_ "FlexKomSigName" SG_ 2432633727 HeightPedObj1_Cval_MPC "MPC_C14_Pkt";
BA_ "FlexKomSigLaenge" SG_ 2432633727 HeightPedObj1_Cval_MPC 64;
BA_ "FlexKomSigStartPos" SG_ 2432633727 HeightPedObj1_Cval_MPC 7;
BA_ "FlexKomSID" SG_ 2432633727 HeightPedObj1_Cval_MPC 100679830;
BA_ "GenSigStartValue" SG_ 2432633727 HeightPedObj1_Cval_MPC 255;
BA_ "FlexKomSigStartValue" SG_ 2432633727 HeightPedObj1_Cval_MPC "C4F0FFFFFFFFFFFFh";
BA_ "GenSigCycleTime" SG_ 2432633727 HeightPedObj1_Cval_MPC 50;
BA_ "GenSigSNA" SG_ 2432633727 LaneAlloc_PedObj1_Cval_MPC "7h";
BA_ "FlexKomIsMotorola" SG_ 2432633727 LaneAlloc_PedObj1_Cval_MPC 1;
BA_ "FlexKomComment" SG_ 2432633727 LaneAlloc_PedObj1_Cval_MPC "MPC_C14_Pkt";
BA_ "FlexKomSigName" SG_ 2432633727 LaneAlloc_PedObj1_Cval_MPC "MPC_C14_Pkt";
BA_ "FlexKomSigLaenge" SG_ 2432633727 LaneAlloc_PedObj1_Cval_MPC 64;
BA_ "FlexKomSigStartPos" SG_ 2432633727 LaneAlloc_PedObj1_Cval_MPC 7;
BA_ "FlexKomSID" SG_ 2432633727 LaneAlloc_PedObj1_Cval_MPC 100679830;
BA_ "GenSigStartValue" SG_ 2432633727 LaneAlloc_PedObj1_Cval_MPC 7;
BA_ "FlexKomSigStartValue" SG_ 2432633727 LaneAlloc_PedObj1_Cval_MPC "C4F0FFFFFFFFFFFFh";
BA_ "GenSigCycleTime" SG_ 2432633727 LaneAlloc_PedObj1_Cval_MPC 50;
BA_ "GenSigSNA" SG_ 2432633727 TurnSgl_PedObj1_Cval_MPC "7h";
BA_ "FlexKomIsMotorola" SG_ 2432633727 TurnSgl_PedObj1_Cval_MPC 1;
BA_ "FlexKomComment" SG_ 2432633727 TurnSgl_PedObj1_Cval_MPC "MPC_C14_Pkt";
BA_ "FlexKomSigName" SG_ 2432633727 TurnSgl_PedObj1_Cval_MPC "MPC_C14_Pkt";
BA_ "FlexKomSigLaenge" SG_ 2432633727 TurnSgl_PedObj1_Cval_MPC 64;
BA_ "FlexKomSigStartPos" SG_ 2432633727 TurnSgl_PedObj1_Cval_MPC 7;
BA_ "FlexKomSID" SG_ 2432633727 TurnSgl_PedObj1_Cval_MPC 100679830;
BA_ "GenSigStartValue" SG_ 2432633727 TurnSgl_PedObj1_Cval_MPC 7;
BA_ "FlexKomSigStartValue" SG_ 2432633727 TurnSgl_PedObj1_Cval_MPC "C4F0FFFFFFFFFFFFh";
BA_ "GenSigCycleTime" SG_ 2432633727 TurnSgl_PedObj1_Cval_MPC 50;
BA_ "GenSigSNA" SG_ 2432633727 LaneChgInd_PedObj1_Stat_MPC "3h";
BA_ "FlexKomIsMotorola" SG_ 2432633727 LaneChgInd_PedObj1_Stat_MPC 1;
BA_ "FlexKomComment" SG_ 2432633727 LaneChgInd_PedObj1_Stat_MPC "MPC_C14_Pkt";
BA_ "FlexKomSigName" SG_ 2432633727 LaneChgInd_PedObj1_Stat_MPC "MPC_C14_Pkt";
BA_ "FlexKomSigLaenge" SG_ 2432633727 LaneChgInd_PedObj1_Stat_MPC 64;
BA_ "FlexKomSigStartPos" SG_ 2432633727 LaneChgInd_PedObj1_Stat_MPC 7;
BA_ "FlexKomSID" SG_ 2432633727 LaneChgInd_PedObj1_Stat_MPC 100679830;
BA_ "GenSigStartValue" SG_ 2432633727 LaneChgInd_PedObj1_Stat_MPC 3;
BA_ "FlexKomSigStartValue" SG_ 2432633727 LaneChgInd_PedObj1_Stat_MPC "C4F0FFFFFFFFFFFFh";
BA_ "GenSigCycleTime" SG_ 2432633727 LaneChgInd_PedObj1_Stat_MPC 50;
BA_ "GenSigSNA" SG_ 2432633983 CRC_SG_MPC_C15_Pkt "21h";
BA_ "FlexKomIsMotorola" SG_ 2432633983 CRC_SG_MPC_C15_Pkt 1;
BA_ "FlexKomComment" SG_ 2432633983 CRC_SG_MPC_C15_Pkt "MPC_C15_Pkt";
BA_ "FlexKomSigName" SG_ 2432633983 CRC_SG_MPC_C15_Pkt "MPC_C15_Pkt";
BA_ "FlexKomSigLaenge" SG_ 2432633983 CRC_SG_MPC_C15_Pkt 64;
BA_ "FlexKomSigStartPos" SG_ 2432633983 CRC_SG_MPC_C15_Pkt 7;
BA_ "FlexKomSID" SG_ 2432633983 CRC_SG_MPC_C15_Pkt 100679831;
BA_ "GenSigStartValue" SG_ 2432633983 CRC_SG_MPC_C15_Pkt 33;
BA_ "FlexKomSigStartValue" SG_ 2432633983 CRC_SG_MPC_C15_Pkt "21F0FFFFFFFFFFFFh";
BA_ "GenSigCycleTime" SG_ 2432633983 CRC_SG_MPC_C15_Pkt 50;
BA_ "GenSigSNA" SG_ 2432633983 SQC_SG_MPC_C15_Pkt "0h";
BA_ "FlexKomIsMotorola" SG_ 2432633983 SQC_SG_MPC_C15_Pkt 1;
BA_ "FlexKomComment" SG_ 2432633983 SQC_SG_MPC_C15_Pkt "MPC_C15_Pkt";
BA_ "FlexKomSigName" SG_ 2432633983 SQC_SG_MPC_C15_Pkt "MPC_C15_Pkt";
BA_ "FlexKomSigLaenge" SG_ 2432633983 SQC_SG_MPC_C15_Pkt 64;
BA_ "FlexKomSigStartPos" SG_ 2432633983 SQC_SG_MPC_C15_Pkt 7;
BA_ "FlexKomSID" SG_ 2432633983 SQC_SG_MPC_C15_Pkt 100679831;
BA_ "FlexKomSigStartValue" SG_ 2432633983 SQC_SG_MPC_C15_Pkt "21F0FFFFFFFFFFFFh";
BA_ "GenSigCycleTime" SG_ 2432633983 SQC_SG_MPC_C15_Pkt 50;
BA_ "GenSigSNA" SG_ 2432633983 ClassPedObj2_Stat_MPC "Fh";
BA_ "FlexKomIsMotorola" SG_ 2432633983 ClassPedObj2_Stat_MPC 1;
BA_ "FlexKomComment" SG_ 2432633983 ClassPedObj2_Stat_MPC "MPC_C15_Pkt";
BA_ "FlexKomSigName" SG_ 2432633983 ClassPedObj2_Stat_MPC "MPC_C15_Pkt";
BA_ "FlexKomSigLaenge" SG_ 2432633983 ClassPedObj2_Stat_MPC 64;
BA_ "FlexKomSigStartPos" SG_ 2432633983 ClassPedObj2_Stat_MPC 7;
BA_ "FlexKomSID" SG_ 2432633983 ClassPedObj2_Stat_MPC 100679831;
BA_ "GenSigStartValue" SG_ 2432633983 ClassPedObj2_Stat_MPC 15;
BA_ "FlexKomSigStartValue" SG_ 2432633983 ClassPedObj2_Stat_MPC "21F0FFFFFFFFFFFFh";
BA_ "GenSigCycleTime" SG_ 2432633983 ClassPedObj2_Stat_MPC 50;
BA_ "GenSigSNA" SG_ 2432633983 NumPedObj2_Cval_MPC "1Fh";
BA_ "FlexKomIsMotorola" SG_ 2432633983 NumPedObj2_Cval_MPC 1;
BA_ "FlexKomComment" SG_ 2432633983 NumPedObj2_Cval_MPC "MPC_C15_Pkt";
BA_ "FlexKomSigName" SG_ 2432633983 NumPedObj2_Cval_MPC "MPC_C15_Pkt";
BA_ "FlexKomSigLaenge" SG_ 2432633983 NumPedObj2_Cval_MPC 64;
BA_ "FlexKomSigStartPos" SG_ 2432633983 NumPedObj2_Cval_MPC 7;
BA_ "FlexKomSID" SG_ 2432633983 NumPedObj2_Cval_MPC 100679831;
BA_ "GenSigStartValue" SG_ 2432633983 NumPedObj2_Cval_MPC 31;
BA_ "FlexKomSigStartValue" SG_ 2432633983 NumPedObj2_Cval_MPC "21F0FFFFFFFFFFFFh";
BA_ "GenSigCycleTime" SG_ 2432633983 NumPedObj2_Cval_MPC 50;
BA_ "GenSigSNA" SG_ 2432633983 TypePedObj2_Stat_MPC "7h";
BA_ "FlexKomIsMotorola" SG_ 2432633983 TypePedObj2_Stat_MPC 1;
BA_ "FlexKomComment" SG_ 2432633983 TypePedObj2_Stat_MPC "MPC_C15_Pkt";
BA_ "FlexKomSigName" SG_ 2432633983 TypePedObj2_Stat_MPC "MPC_C15_Pkt";
BA_ "FlexKomSigLaenge" SG_ 2432633983 TypePedObj2_Stat_MPC 64;
BA_ "FlexKomSigStartPos" SG_ 2432633983 TypePedObj2_Stat_MPC 7;
BA_ "FlexKomSID" SG_ 2432633983 TypePedObj2_Stat_MPC 100679831;
BA_ "GenSigStartValue" SG_ 2432633983 TypePedObj2_Stat_MPC 7;
BA_ "FlexKomSigStartValue" SG_ 2432633983 TypePedObj2_Stat_MPC "21F0FFFFFFFFFFFFh";
BA_ "GenSigCycleTime" SG_ 2432633983 TypePedObj2_Stat_MPC 50;
BA_ "GenSigSNA" SG_ 2432633983 StdRng_X_PedObj2_Cval_MPC "3h";
BA_ "FlexKomIsMotorola" SG_ 2432633983 StdRng_X_PedObj2_Cval_MPC 1;
BA_ "FlexKomComment" SG_ 2432633983 StdRng_X_PedObj2_Cval_MPC "MPC_C15_Pkt";
BA_ "FlexKomSigName" SG_ 2432633983 StdRng_X_PedObj2_Cval_MPC "MPC_C15_Pkt";
BA_ "FlexKomSigLaenge" SG_ 2432633983 StdRng_X_PedObj2_Cval_MPC 64;
BA_ "FlexKomSigStartPos" SG_ 2432633983 StdRng_X_PedObj2_Cval_MPC 7;
BA_ "FlexKomSID" SG_ 2432633983 StdRng_X_PedObj2_Cval_MPC 100679831;
BA_ "GenSigStartValue" SG_ 2432633983 StdRng_X_PedObj2_Cval_MPC 3;
BA_ "FlexKomSigStartValue" SG_ 2432633983 StdRng_X_PedObj2_Cval_MPC "21F0FFFFFFFFFFFFh";
BA_ "GenSigCycleTime" SG_ 2432633983 StdRng_X_PedObj2_Cval_MPC 50;
BA_ "GenSigSNA" SG_ 2432633983 StdRng_Y_PedObj2_Cval_MPC "3h";
BA_ "FlexKomIsMotorola" SG_ 2432633983 StdRng_Y_PedObj2_Cval_MPC 1;
BA_ "FlexKomComment" SG_ 2432633983 StdRng_Y_PedObj2_Cval_MPC "MPC_C15_Pkt";
BA_ "FlexKomSigName" SG_ 2432633983 StdRng_Y_PedObj2_Cval_MPC "MPC_C15_Pkt";
BA_ "FlexKomSigLaenge" SG_ 2432633983 StdRng_Y_PedObj2_Cval_MPC 64;
BA_ "FlexKomSigStartPos" SG_ 2432633983 StdRng_Y_PedObj2_Cval_MPC 7;
BA_ "FlexKomSID" SG_ 2432633983 StdRng_Y_PedObj2_Cval_MPC 100679831;
BA_ "GenSigStartValue" SG_ 2432633983 StdRng_Y_PedObj2_Cval_MPC 3;
BA_ "FlexKomSigStartValue" SG_ 2432633983 StdRng_Y_PedObj2_Cval_MPC "21F0FFFFFFFFFFFFh";
BA_ "GenSigCycleTime" SG_ 2432633983 StdRng_Y_PedObj2_Cval_MPC 50;
BA_ "GenSigSNA" SG_ 2432633983 StdRng_Spd_X_PedObj2_Cval_MPC "3h";
BA_ "FlexKomIsMotorola" SG_ 2432633983 StdRng_Spd_X_PedObj2_Cval_MPC 1;
BA_ "FlexKomComment" SG_ 2432633983 StdRng_Spd_X_PedObj2_Cval_MPC "MPC_C15_Pkt";
BA_ "FlexKomSigName" SG_ 2432633983 StdRng_Spd_X_PedObj2_Cval_MPC "MPC_C15_Pkt";
BA_ "FlexKomSigLaenge" SG_ 2432633983 StdRng_Spd_X_PedObj2_Cval_MPC 64;
BA_ "FlexKomSigStartPos" SG_ 2432633983 StdRng_Spd_X_PedObj2_Cval_MPC 7;
BA_ "FlexKomSID" SG_ 2432633983 StdRng_Spd_X_PedObj2_Cval_MPC 100679831;
BA_ "GenSigStartValue" SG_ 2432633983 StdRng_Spd_X_PedObj2_Cval_MPC 3;
BA_ "FlexKomSigStartValue" SG_ 2432633983 StdRng_Spd_X_PedObj2_Cval_MPC "21F0FFFFFFFFFFFFh";
BA_ "GenSigCycleTime" SG_ 2432633983 StdRng_Spd_X_PedObj2_Cval_MPC 50;
BA_ "GenSigSNA" SG_ 2432633983 StdRng_Spd_Y_PedObj2_Cval_MPC "3h";
BA_ "FlexKomIsMotorola" SG_ 2432633983 StdRng_Spd_Y_PedObj2_Cval_MPC 1;
BA_ "FlexKomComment" SG_ 2432633983 StdRng_Spd_Y_PedObj2_Cval_MPC "MPC_C15_Pkt";
BA_ "FlexKomSigName" SG_ 2432633983 StdRng_Spd_Y_PedObj2_Cval_MPC "MPC_C15_Pkt";
BA_ "FlexKomSigLaenge" SG_ 2432633983 StdRng_Spd_Y_PedObj2_Cval_MPC 64;
BA_ "FlexKomSigStartPos" SG_ 2432633983 StdRng_Spd_Y_PedObj2_Cval_MPC 7;
BA_ "FlexKomSID" SG_ 2432633983 StdRng_Spd_Y_PedObj2_Cval_MPC 100679831;
BA_ "GenSigStartValue" SG_ 2432633983 StdRng_Spd_Y_PedObj2_Cval_MPC 3;
BA_ "FlexKomSigStartValue" SG_ 2432633983 StdRng_Spd_Y_PedObj2_Cval_MPC "21F0FFFFFFFFFFFFh";
BA_ "GenSigCycleTime" SG_ 2432633983 StdRng_Spd_Y_PedObj2_Cval_MPC 50;
BA_ "GenSigSNA" SG_ 2432633983 WidthPedObj2_Cval_MPC "FFh";
BA_ "FlexKomIsMotorola" SG_ 2432633983 WidthPedObj2_Cval_MPC 1;
BA_ "FlexKomComment" SG_ 2432633983 WidthPedObj2_Cval_MPC "MPC_C15_Pkt";
BA_ "FlexKomSigName" SG_ 2432633983 WidthPedObj2_Cval_MPC "MPC_C15_Pkt";
BA_ "FlexKomSigLaenge" SG_ 2432633983 WidthPedObj2_Cval_MPC 64;
BA_ "FlexKomSigStartPos" SG_ 2432633983 WidthPedObj2_Cval_MPC 7;
BA_ "FlexKomSID" SG_ 2432633983 WidthPedObj2_Cval_MPC 100679831;
BA_ "GenSigStartValue" SG_ 2432633983 WidthPedObj2_Cval_MPC 255;
BA_ "FlexKomSigStartValue" SG_ 2432633983 WidthPedObj2_Cval_MPC "21F0FFFFFFFFFFFFh";
BA_ "GenSigCycleTime" SG_ 2432633983 WidthPedObj2_Cval_MPC 50;
BA_ "GenSigSNA" SG_ 2432633983 OLA_PedObj2_Cval_MPC "FFh";
BA_ "FlexKomIsMotorola" SG_ 2432633983 OLA_PedObj2_Cval_MPC 1;
BA_ "FlexKomComment" SG_ 2432633983 OLA_PedObj2_Cval_MPC "MPC_C15_Pkt";
BA_ "FlexKomSigName" SG_ 2432633983 OLA_PedObj2_Cval_MPC "MPC_C15_Pkt";
BA_ "FlexKomSigLaenge" SG_ 2432633983 OLA_PedObj2_Cval_MPC 64;
BA_ "FlexKomSigStartPos" SG_ 2432633983 OLA_PedObj2_Cval_MPC 7;
BA_ "FlexKomSID" SG_ 2432633983 OLA_PedObj2_Cval_MPC 100679831;
BA_ "GenSigStartValue" SG_ 2432633983 OLA_PedObj2_Cval_MPC 255;
BA_ "FlexKomSigStartValue" SG_ 2432633983 OLA_PedObj2_Cval_MPC "21F0FFFFFFFFFFFFh";
BA_ "GenSigCycleTime" SG_ 2432633983 OLA_PedObj2_Cval_MPC 50;
BA_ "GenSigSNA" SG_ 2432633983 HeightPedObj2_Cval_MPC "FFh";
BA_ "FlexKomIsMotorola" SG_ 2432633983 HeightPedObj2_Cval_MPC 1;
BA_ "FlexKomComment" SG_ 2432633983 HeightPedObj2_Cval_MPC "MPC_C15_Pkt";
BA_ "FlexKomSigName" SG_ 2432633983 HeightPedObj2_Cval_MPC "MPC_C15_Pkt";
BA_ "FlexKomSigLaenge" SG_ 2432633983 HeightPedObj2_Cval_MPC 64;
BA_ "FlexKomSigStartPos" SG_ 2432633983 HeightPedObj2_Cval_MPC 7;
BA_ "FlexKomSID" SG_ 2432633983 HeightPedObj2_Cval_MPC 100679831;
BA_ "GenSigStartValue" SG_ 2432633983 HeightPedObj2_Cval_MPC 255;
BA_ "FlexKomSigStartValue" SG_ 2432633983 HeightPedObj2_Cval_MPC "21F0FFFFFFFFFFFFh";
BA_ "GenSigCycleTime" SG_ 2432633983 HeightPedObj2_Cval_MPC 50;
BA_ "GenSigSNA" SG_ 2432633983 LaneAlloc_PedObj2_Cval_MPC "7h";
BA_ "FlexKomIsMotorola" SG_ 2432633983 LaneAlloc_PedObj2_Cval_MPC 1;
BA_ "FlexKomComment" SG_ 2432633983 LaneAlloc_PedObj2_Cval_MPC "MPC_C15_Pkt";
BA_ "FlexKomSigName" SG_ 2432633983 LaneAlloc_PedObj2_Cval_MPC "MPC_C15_Pkt";
BA_ "FlexKomSigLaenge" SG_ 2432633983 LaneAlloc_PedObj2_Cval_MPC 64;
BA_ "FlexKomSigStartPos" SG_ 2432633983 LaneAlloc_PedObj2_Cval_MPC 7;
BA_ "FlexKomSID" SG_ 2432633983 LaneAlloc_PedObj2_Cval_MPC 100679831;
BA_ "GenSigStartValue" SG_ 2432633983 LaneAlloc_PedObj2_Cval_MPC 7;
BA_ "FlexKomSigStartValue" SG_ 2432633983 LaneAlloc_PedObj2_Cval_MPC "21F0FFFFFFFFFFFFh";
BA_ "GenSigCycleTime" SG_ 2432633983 LaneAlloc_PedObj2_Cval_MPC 50;
BA_ "GenSigSNA" SG_ 2432633983 TurnSgl_PedObj2_Cval_MPC "7h";
BA_ "FlexKomIsMotorola" SG_ 2432633983 TurnSgl_PedObj2_Cval_MPC 1;
BA_ "FlexKomComment" SG_ 2432633983 TurnSgl_PedObj2_Cval_MPC "MPC_C15_Pkt";
BA_ "FlexKomSigName" SG_ 2432633983 TurnSgl_PedObj2_Cval_MPC "MPC_C15_Pkt";
BA_ "FlexKomSigLaenge" SG_ 2432633983 TurnSgl_PedObj2_Cval_MPC 64;
BA_ "FlexKomSigStartPos" SG_ 2432633983 TurnSgl_PedObj2_Cval_MPC 7;
BA_ "FlexKomSID" SG_ 2432633983 TurnSgl_PedObj2_Cval_MPC 100679831;
BA_ "GenSigStartValue" SG_ 2432633983 TurnSgl_PedObj2_Cval_MPC 7;
BA_ "FlexKomSigStartValue" SG_ 2432633983 TurnSgl_PedObj2_Cval_MPC "21F0FFFFFFFFFFFFh";
BA_ "GenSigCycleTime" SG_ 2432633983 TurnSgl_PedObj2_Cval_MPC 50;
BA_ "GenSigSNA" SG_ 2432633983 LaneChgInd_PedObj2_Stat_MPC "3h";
BA_ "FlexKomIsMotorola" SG_ 2432633983 LaneChgInd_PedObj2_Stat_MPC 1;
BA_ "FlexKomComment" SG_ 2432633983 LaneChgInd_PedObj2_Stat_MPC "MPC_C15_Pkt";
BA_ "FlexKomSigName" SG_ 2432633983 LaneChgInd_PedObj2_Stat_MPC "MPC_C15_Pkt";
BA_ "FlexKomSigLaenge" SG_ 2432633983 LaneChgInd_PedObj2_Stat_MPC 64;
BA_ "FlexKomSigStartPos" SG_ 2432633983 LaneChgInd_PedObj2_Stat_MPC 7;
BA_ "FlexKomSID" SG_ 2432633983 LaneChgInd_PedObj2_Stat_MPC 100679831;
BA_ "GenSigStartValue" SG_ 2432633983 LaneChgInd_PedObj2_Stat_MPC 3;
BA_ "FlexKomSigStartValue" SG_ 2432633983 LaneChgInd_PedObj2_Stat_MPC "21F0FFFFFFFFFFFFh";
BA_ "GenSigCycleTime" SG_ 2432633983 LaneChgInd_PedObj2_Stat_MPC 50;
VAL_ 2297437459 StwAngl_Cval_SWS 65280 "SNA_MIN" 65280 "ERR_MAX" 65024 "ERR_MIN" 65023 "RES_MAX" 64256 "RES_MIN" 65535 "SNA_MAX" ;
VAL_ 2297437459 StwTurnCntr_Cval_SWS 63 "SNA" 62 "ERR" ;
VAL_ 2297437459 StwAnglSensType_Cval_SWS 3 "SNA" 2 "RES" 1 "ABS" 0 "REL" ;
VAL_ 2298375691 SpdFtAxleLtWhl_Cval 65280 "SNA_MIN" 65280 "ERR_MAX" 65024 "ERR_MIN" 65023 "RES_MAX" 64256 "RES_MIN" 65535 "SNA_MAX" ;
VAL_ 2298375691 SpdFtAxleRtWhl_Cval 65280 "SNA_MIN" 65280 "ERR_MAX" 65024 "ERR_MIN" 65023 "RES_MAX" 64256 "RES_MIN" 65535 "SNA_MAX" ;
VAL_ 2298375691 SpdR_AxleLtWhl_Cval 65280 "SNA_MIN" 65280 "ERR_MAX" 65024 "ERR_MIN" 65023 "RES_MAX" 64256 "RES_MIN" 65535 "SNA_MAX" ;
VAL_ 2298375691 SpdR_AxleRtWhl_Cval 65280 "SNA_MIN" 65280 "ERR_MAX" 65024 "ERR_MIN" 65023 "RES_MAX" 64256 "RES_MIN" 65535 "SNA_MAX" ;
VAL_ 2365484055 DirInd_Stat_ICUC 3 "SNA" 2 "ERR" 1 "REV" 0 "FWD" ;
VAL_ 2365484055 VehSpd_Cval_ICUC 65535 "SNA" ;
VAL_ 2365521931 VehSpd_Cval_BS 255 "SNA" 254 "ERR" ;
VAL_ 2365522152 TmStmp_Cval_VRDU 255 "SNA" 254 "ERR" ;
VAL_ 2365522152 Accel_Y_Cval_VRDU 255 "SNA" ;
VAL_ 2365522152 StAngl_Cval_VRDU 65280 "SNA_MIN" 65279 "ERR_MAX" 65024 "ERR_MIN" 65023 "RES_MAX" 64256 "RES_MIN" 65535 "SNA_MAX" ;
VAL_ 2431648512 AccelPdlKickDnSw_Rq 3 "SNA" 2 "ERR" 1 "ACTIVE" 0 "PASSIVE" ;
VAL_ 2431648512 AccelPdlPosn_Cval 255 "SNA" 254 "ERR" ;
VAL_ 2432617087 DTC_PL_Stat_MPC 3 "SNA" 2 "RES" 1 "ON" 0 "OFF" ;
VAL_ 2432617087 DTC_AWL_Stat_MPC 3 "SNA" 2 "RES" 1 "ON" 0 "OFF" ;
VAL_ 2432617087 DTC_RSL_Stat_MPC 3 "SNA" 2 "RES" 1 "ON" 0 "OFF" ;
VAL_ 2432617087 DTC_MIL_Stat_MPC 3 "SNA" 2 "RES" 1 "ON" 0 "OFF" ;
VAL_ 2432617087 DTC_PL_Flash_Stat_MPC 3 "SNA" 2 "RES" 1 "FFLASH" 0 "SLOWFL" ;
VAL_ 2432617087 DTC_AWL_Flash_Stat_MPC 3 "SNA" 2 "RES" 1 "FFLASH" 0 "SLOWFL" ;
VAL_ 2432617087 DTC_RSL_Flash_Stat_MPC 3 "SNA" 2 "RES" 1 "FFLASH" 0 "SLOWFL" ;
VAL_ 2432617087 DTC_MIL_Flash_Stat_MPC 3 "SNA" 2 "RES" 1 "FFLASH" 0 "SLOWFL" ;
VAL_ 2432617087 DTC_OccCnt_MPC 127 "SNA" ;
VAL_ 2432617087 DTC_SPN_ConvMd_MPC 1 "Vers123" 0 "Vers4" ;
VAL_ 2432630817 IgnSw_Stat_SCA 15 "SNA" 14 "ERR" 13 "RES9" 12 "RES8" 11 "RES7" 10 "LOCK" 9 "RES6" 8 "RES5" 7 "RES4" 6 "RES3" 5 "RES2" 4 "RES" 3 "IGN_CRANK" 2 "IGN_ON" 1 "IGN_ACC" 0 "IGN_OFF" ;
VAL_ 2432630817 SysVolt_Stat 3 "SNA" 2 "UV" 1 "OV" 0 "OK" ;
VAL_ 2432630817 EngCrk_Stat 3 "SNA" 2 "ERR" 1 "ACTIVE" 0 "NACT" ;
VAL_ 2432630817 HiBm_Cmd 3 "SNA" 2 "RES" 1 "ON" 0 "OFF" ;
VAL_ 2432630911 LaneDptFuncActv_Stat_MPC 15 "SNA" 14 "ERR" 5 "OBS" 4 "ORS" 3 "OLS" 2 "PON" 1 "TOFF" 0 "OFF" ;
VAL_ 2432630911 LaneDptImntLt_Rq_MPC 3 "SNA" 2 "ERR" 1 "ON" 0 "OFF" ;
VAL_ 2432630911 LaneDptImntRt_Rq_MPC 3 "SNA" 2 "ERR" 1 "ON" 0 "OFF" ;
VAL_ 2432630911 LaneDptWarnLt_Rq_MPC 3 "SNA" 2 "ERR" 1 "ON" 0 "OFF" ;
VAL_ 2432630911 LaneDptWarnRt_Rq_MPC 3 "SNA" 2 "ERR" 1 "ON" 0 "OFF" ;
VAL_ 2432630911 LaneDptD_Actv_Stat_MPC 3 "SNA" 2 "ERR" 1 "ON" 0 "OFF" ;
VAL_ 2432630911 SwLED_LDW_Rq_MPC 3 "SNA_TNA" 2 "INTRM" 1 "ON" 0 "OFF" ;
VAL_ 2432630911 TypeLaneMarkLt_Stat_MPC 3 "SNA" 2 "CL" 1 "BL" 0 "NL" ;
VAL_ 2432630911 TypeLaneMarkRt_Stat_MPC 3 "SNA" 2 "CL" 1 "BL" 0 "NL" ;
VAL_ 2432630911 ActlLgtDist_Cval 255 "SNA" 254 "ERR" 251 "ONLY_LoBm" ;
VAL_ 2432630911 HL_ChgOvrLvl_Cval 15 "SNA" ;
VAL_ 2432630911 IHC_Func_Stat_MPC 15 "SNA" 14 "ERR" 3 "ACTIVE" 2 "INACTIVE" 1 "INIT" 0 "NIST" ;
VAL_ 2432630911 HiBm_Rq_MPC 3 "SNA" 2 "ERR" 1 "RQ" 0 "NRQ" ;
VAL_ 2432630911 DayNightMd_Stat_MPC 3 "SNA" 2 "ERR" 1 "DAY" 0 "NIGHT" ;
VAL_ 2432630911 LimSight_Stat_MPC 3 "SNA" 2 "ERR" 1 "LIMIT" 0 "NOLIMIT" ;
VAL_ 2432630911 LaneMarkRecLt_Stat 3 "SNA" 2 "CAND" 1 "MIRR" 0 "OBS" ;
VAL_ 2432630911 LaneMarkRecRt_Stat 3 "SNA" 2 "CAND" 1 "MIRR" 0 "OBS" ;
VAL_ 2432630911 LaneMarkColLt_Cval_MPC 7 "SNA" 6 "ERR" 3 "BLUE" 2 "RED" 1 "YELLOW" 0 "WHITE" ;
VAL_ 2432630911 LaneMarkColRt_Cval_MPC 7 "SNA" 6 "ERR" 3 "BLUE" 2 "RED" 1 "YELLOW" 0 "WHITE" ;
VAL_ 2432631051 YawRateCorr_Cval_BS 65280 "SNA_MIN" 65280 "ERR_MAX" 65024 "ERR_MIN" 65023 "RES_MAX" 64226 "RES_MIN" 65535 "SNA_MAX" ;
VAL_ 2432631051 YawRateCorrQual_Cval_BS 255 "SNA" 254 "ERR" ;
VAL_ 2432631167 TypeLaneMarkLtNotFltrd_Stat_MPC 3 "SNA" 2 "CL" 1 "BL" 0 "NL" ;
VAL_ 2432631167 TypeLaneMarkRtNotFltrd_Stat_MPC 3 "SNA" 2 "CL" 1 "BL" 0 "NL" ;
VAL_ 2432631167 WidthLaneLt_Cval_MPC 255 "SNA" 254 "ERR" ;
VAL_ 2432631167 WidthLaneRt_Cval_MPC 255 "SNA" 254 "ERR" ;
VAL_ 2432631167 DistLaneLineLt_Cval_MPC 65535 "SNA" ;
VAL_ 2432631167 DistLaneLineRt_Cval_MPC 65535 "SNA" ;
VAL_ 2432631270 BlockEquip_FOV_Stat 15 "SNA" 14 "ERR" 3 "BLOCK_RDF_MPC" 2 "BLOCK_MPC" 1 "BLOCK_RDF" 0 "NO_BLOCK" ;
VAL_ 2432631423 LaneChgInd_Stat_MPC 3 "SNA" 2 "ERR" 1 "CLL" 0 "NLC" ;
VAL_ 2432631423 LaneDtct_Fail_Stat_MPC 3 "SNA" 2 "RES" 1 "ERR" 0 "NOERR" ;
VAL_ 2432631423 ConfLaneLt_Cval_MPC 15 "SNA" 14 "ERR" ;
VAL_ 2432631423 ConfLaneRt_Cval_MPC 15 "SNA" 14 "ERR" ;
VAL_ 2432631423 Spd_Y_LaneMarkLt_MPC 255 "SNA" ;
VAL_ 2432631423 LaneCrvtrLt_Cval_MPC 65535 "SNA" ;
VAL_ 2432631423 AnglYawLaneLt_Cval_MPC 65535 "SNA" ;
VAL_ 2432631679 IntDtctAvl_Cval 3 "SNA" 2 "ERR" 1 "AVL" 0 "NA" ;
VAL_ 2432631679 IntDtct_Cval 3 "SNA" 2 "ERR" 1 "DTCT" 0 "NOTDTCT" ;
VAL_ 2432631679 DeltaTmStmp_Obj_MPC 255 "SNA" 254 "ERR" ;
VAL_ 2432631679 Spd_Y_LaneMarkRt_MPC 255 "SNA" ;
VAL_ 2432631679 LaneCrvtrRt_Cval_MPC 65535 "SNA" ;
VAL_ 2432631679 AnglYawLaneRt_Cval_MPC 65535 "SNA" ;
VAL_ 2432631935 ConfLvl_PedObj0_Cval 3 "SNA" 2 "CONFLVL2" 1 "CONFLVL1" 0 "NOCONF" ;
VAL_ 2432631935 DtctStat_PedObj0_MPC 3 "SNA" 2 "ERR" 1 "OBSRVD" 0 "NOBSRVD" ;
VAL_ 2432631935 Spd_X_PedObj0_Cval_MPC 255 "SNA" 254 "ERR" ;
VAL_ 2432631935 Spd_Y_PedObj0_Cval_MPC 255 "SNA" ;
VAL_ 2432631935 Dist_X_PedObj0_Cval_MPC 65535 "SNA" ;
VAL_ 2432631935 Dist_Y_PedObj0_Cval_MPC 65535 "SNA" ;
VAL_ 2432632191 ConfLvl_PedObj1_Cval 3 "SNA" 2 "CONFLVL2" 1 "CONFLVL1" 0 "NOCONF" ;
VAL_ 2432632191 DtctStat_PedObj1_MPC 3 "SNA" 2 "ERR" 1 "OBSRVD" 0 "NOBSRVD" ;
VAL_ 2432632191 Spd_X_PedObj1_Cval_MPC 255 "SNA" 254 "ERR" ;
VAL_ 2432632191 Spd_Y_PedObj1_Cval_MPC 255 "SNA" ;
VAL_ 2432632191 Dist_X_PedObj1_Cval_MPC 65535 "SNA" ;
VAL_ 2432632191 Dist_Y_PedObj1_Cval_MPC 65535 "SNA" ;
VAL_ 2432632447 ConfLvl_PedObj2_Cval 3 "SNA" 2 "CONFLVL2" 1 "CONFLVL1" 0 "NOCONF" ;
VAL_ 2432632447 DtctStat_PedObj2_MPC 3 "SNA" 2 "ERR" 1 "OBSRVD" 0 "NOBSRVD" ;
VAL_ 2432632447 Spd_X_PedObj2_Cval_MPC 255 "SNA" 254 "ERR" ;
VAL_ 2432632447 Spd_Y_PedObj2_Cval_MPC 255 "SNA" ;
VAL_ 2432632447 Dist_X_PedObj2_Cval_MPC 65535 "SNA" ;
VAL_ 2432632447 Dist_Y_PedObj2_Cval_MPC 65535 "SNA" ;
VAL_ 2432632703 ConfLvl_PedObj3_Cval 3 "SNA" 2 "CONFLVL2" 1 "CONFLVL1" 0 "NOCONF" ;
VAL_ 2432632703 DtctStat_PedObj3_MPC 3 "SNA" 2 "ERR" 1 "OBSRVD" 0 "NOBSRVD" ;
VAL_ 2432632703 Spd_X_PedObj3_Cval_MPC 255 "SNA" 254 "ERR" ;
VAL_ 2432632703 Spd_Y_PedObj3_Cval_MPC 255 "SNA" ;
VAL_ 2432632703 Dist_X_PedObj3_Cval_MPC 65535 "SNA" ;
VAL_ 2432632703 Dist_Y_PedObj3_Cval_MPC 65535 "SNA" ;
VAL_ 2432632959 ConfLvl_PedObj4_Cval 3 "SNA" 2 "CONFLVL2" 1 "CONFLVL1" 0 "NOCONF" ;
VAL_ 2432632959 DtctStat_PedObj4_MPC 3 "SNA" 2 "ERR" 1 "OBSRVD" 0 "NOBSRVD" ;
VAL_ 2432632959 Spd_X_PedObj4_Cval_MPC 255 "SNA" 254 "ERR" ;
VAL_ 2432632959 Spd_Y_PedObj4_Cval_MPC 255 "SNA" ;
VAL_ 2432632959 Dist_X_PedObj4_Cval_MPC 65535 "SNA" ;
VAL_ 2432632959 Dist_Y_PedObj4_Cval_MPC 65535 "SNA" ;
VAL_ 2432633215 ConfLvl_PedObj5_Cval 3 "SNA" 2 "CONFLVL2" 1 "CONFLVL1" 0 "NOCONF" ;
VAL_ 2432633215 DtctStat_PedObj5_MPC 3 "SNA" 2 "ERR" 1 "OBSRVD" 0 "NOBSRVD" ;
VAL_ 2432633215 Spd_X_PedObj5_Cval_MPC 255 "SNA" 254 "ERR" ;
VAL_ 2432633215 Spd_Y_PedObj5_Cval_MPC 255 "SNA" ;
VAL_ 2432633215 Dist_X_PedObj5_Cval_MPC 65535 "SNA" ;
VAL_ 2432633215 Dist_Y_PedObj5_Cval_MPC 65535 "SNA" ;
VAL_ 2432633471 ClassPedObj0_Stat_MPC 15 "SNA" 14 "ERR" 6 "OTHER" 5 "PED_GROUP" 4 "PEDESTRIAN" 3 "BICYCLE" 2 "MOT_CYC" 1 "PAS_CAR" 0 "TRUCK" ;
VAL_ 2432633471 NumPedObj0_Cval_MPC 31 "SNA" ;
VAL_ 2432633471 TypePedObj0_Stat_MPC 7 "SNA" 6 "init" 5 "oncom" 4 "cross" 3 "stati" 2 "Mov_Stop" 1 "Mov" 0 "not_detec" ;
VAL_ 2432633471 StdRng_X_PedObj0_Cval_MPC 3 "SNA" 2 "BELW_2M" 1 "BELW_1M" 0 "BELW_0_5M" ;
VAL_ 2432633471 StdRng_Y_PedObj0_Cval_MPC 3 "SNA" 2 "BELW_1M" 1 "BELW_0_5M" 0 "BELW_0_25M" ;
VAL_ 2432633471 StdRng_Spd_X_PedObj0_Cval_MPC 3 "SNA" 2 "BELW_2M_PER_S" 1 "BELW_1M_PER_S" 0 "BELW_0_5M_PER_S" ;
VAL_ 2432633471 StdRng_Spd_Y_PedObj0_Cval_MPC 3 "SNA" 2 "BELW_1_2M_PER_S" 1 "BELW_0_6M_PER_S" 0 "BELW_0_3M_PER_S" ;
VAL_ 2432633471 WidthPedObj0_Cval_MPC 255 "SNA" 254 "ERR" ;
VAL_ 2432633471 OLA_PedObj0_Cval_MPC 255 "SNA" 254 "ERR" ;
VAL_ 2432633471 HeightPedObj0_Cval_MPC 255 "SNA" 254 "ERR" ;
VAL_ 2432633471 LaneAlloc_PedObj0_Cval_MPC 7 "SNA" 3 "OBJ_RT" 2 "OBJ_CNT" 1 "OBJ_LT" 0 "NO_ALLOC" ;
VAL_ 2432633471 TurnSgl_PedObj0_Cval_MPC 7 "SNA" 3 "HAZARD" 2 "RIGHT" 1 "LEFT" 0 "NO" ;
VAL_ 2432633471 LaneChgInd_PedObj0_Stat_MPC 3 "SNA" 2 "CUT_OUT" 1 "CUT_IN" 0 "NO" ;
VAL_ 2432633727 ClassPedObj1_Stat_MPC 15 "SNA" 14 "ERR" 6 "OTHER" 5 "PED_GROUP" 4 "PEDESTRIAN" 3 "BICYCLE" 2 "MOT_CYC" 1 "PAS_CAR" 0 "TRUCK" ;
VAL_ 2432633727 NumPedObj1_Cval_MPC 31 "SNA" ;
VAL_ 2432633727 TypePedObj1_Stat_MPC 7 "SNA" 6 "init" 5 "oncom" 4 "cross" 3 "stati" 2 "Mov_Stop" 1 "Mov" 0 "not_detec" ;
VAL_ 2432633727 StdRng_X_PedObj1_Cval_MPC 3 "SNA" 2 "BELW_2M" 1 "BELW_1M" 0 "BELW_0_5M" ;
VAL_ 2432633727 StdRng_Y_PedObj1_Cval_MPC 3 "SNA" 2 "BELW_1M" 1 "BELW_0_5M" 0 "BELW_0_25M" ;
VAL_ 2432633727 StdRng_Spd_X_PedObj1_Cval_MPC 3 "SNA" 2 "BELW_2M_PER_S" 1 "BELW_1M_PER_S" 0 "BELW_0_5M_PER_S" ;
VAL_ 2432633727 StdRng_Spd_Y_PedObj1_Cval_MPC 3 "SNA" 2 "BELW_1_2M_PER_S" 1 "BELW_0_6M_PER_S" 0 "BELW_0_3M_PER_S" ;
VAL_ 2432633727 WidthPedObj1_Cval_MPC 255 "SNA" 254 "ERR" ;
VAL_ 2432633727 OLA_PedObj1_Cval_MPC 255 "SNA" 254 "ERR" ;
VAL_ 2432633727 HeightPedObj1_Cval_MPC 255 "SNA" 254 "ERR" ;
VAL_ 2432633727 LaneAlloc_PedObj1_Cval_MPC 7 "SNA" 3 "OBJ_RT" 2 "OBJ_CNT" 1 "OBJ_LT" 0 "NO_ALLOC" ;
VAL_ 2432633727 TurnSgl_PedObj1_Cval_MPC 7 "SNA" 3 "HAZARD" 2 "RIGHT" 1 "LEFT" 0 "NO" ;
VAL_ 2432633727 LaneChgInd_PedObj1_Stat_MPC 3 "SNA" 2 "CUT_OUT" 1 "CUT_IN" 0 "NO" ;
VAL_ 2432633983 ClassPedObj2_Stat_MPC 15 "SNA" 14 "ERR" 6 "OTHER" 5 "PED_GROUP" 4 "PEDESTRIAN" 3 "BICYCLE" 2 "MOT_CYC" 1 "PAS_CAR" 0 "TRUCK" ;
VAL_ 2432633983 NumPedObj2_Cval_MPC 31 "SNA" ;
VAL_ 2432633983 TypePedObj2_Stat_MPC 7 "SNA" 6 "init" 5 "oncom" 4 "cross" 3 "stati" 2 "Mov_Stop" 1 "Mov" 0 "not_detec" ;
VAL_ 2432633983 StdRng_X_PedObj2_Cval_MPC 3 "SNA" 2 "BELW_2M" 1 "BELW_1M" 0 "BELW_0_5M" ;
VAL_ 2432633983 StdRng_Y_PedObj2_Cval_MPC 3 "SNA" 2 "BELW_1M" 1 "BELW_0_5M" 0 "BELW_0_25M" ;
VAL_ 2432633983 StdRng_Spd_X_PedObj2_Cval_MPC 3 "SNA" 2 "BELW_2M_PER_S" 1 "BELW_1M_PER_S" 0 "BELW_0_5M_PER_S" ;
VAL_ 2432633983 StdRng_Spd_Y_PedObj2_Cval_MPC 3 "SNA" 2 "BELW_1_2M_PER_S" 1 "BELW_0_6M_PER_S" 0 "BELW_0_3M_PER_S" ;
VAL_ 2432633983 WidthPedObj2_Cval_MPC 255 "SNA" 254 "ERR" ;
VAL_ 2432633983 OLA_PedObj2_Cval_MPC 255 "SNA" 254 "ERR" ;
VAL_ 2432633983 HeightPedObj2_Cval_MPC 255 "SNA" 254 "ERR" ;
VAL_ 2432633983 LaneAlloc_PedObj2_Cval_MPC 7 "SNA" 3 "OBJ_RT" 2 "OBJ_CNT" 1 "OBJ_LT" 0 "NO_ALLOC" ;
VAL_ 2432633983 TurnSgl_PedObj2_Cval_MPC 7 "SNA" 3 "HAZARD" 2 "RIGHT" 1 "LEFT" 0 "NO" ;
VAL_ 2432633983 LaneChgInd_PedObj2_Stat_MPC 3 "SNA" 2 "CUT_OUT" 1 "CUT_IN" 0 "NO" ;
